VERSION "HNNBNNNYNNNNNNNNNNNNNNNNNNNNNNNNNNNNNNNNNN/4/%%%/4/'%**4NNN///"

NS_ :

BS_:

BU_: BAP_Tester BedienDisp_vo BedienSG_hi CGS DDA Gateway Gateway_PAG GurtMikrofon OTA_FC ZR_High ZR_LIMU ZR_MIB_TOP_ab_Gen3 ZR_Standard

BO_ 2527679896 Fahrwerk_12: 8 Gateway_PAG
 SG_ Fahrwerk_12_CRC : 0|8@1+ (1,0) [0|255] ""  Vector__XXX
 SG_ Fahrwerk_12_BZ : 8|4@1+ (1,0) [0|15] ""  Vector__XXX
 SG_ EFP_ReifenTempOf_VL : 12|6@1+ (2,-25) [-25|99] "Unit_DegreCelsi"  Vector__XXX
 SG_ EFP_ReifenTempOf_VR : 18|6@1+ (2,-25) [-25|99] "Unit_DegreCelsi"  Vector__XXX
 SG_ EFP_ReifenTempOf_HL : 24|6@1+ (2,-25) [-25|99] "Unit_DegreCelsi"  Vector__XXX
 SG_ EFP_ReifenTempOf_HR : 30|6@1+ (2,-25) [-25|99] "Unit_DegreCelsi"  Vector__XXX
 SG_ FA_FahrerAnf_Lift_Abwurf : 39|1@1+ (1.0,0.0) [0.0|1] ""  ZR_MIB_TOP_ab_Gen3
 SG_ FA_Niveau_AOCCT_timer2_verbaut : 40|1@1+ (1.0,0.0) [0.0|1] ""  Vector__XXX
 SG_ FA_Niveau_AOCCT_timer2_count : 41|1@1+ (1.0,0.0) [0.0|1] ""  Vector__XXX
 SG_ FA_Niveau_AOCCT_timer1_verbaut : 42|1@1+ (1.0,0.0) [0.0|1] ""  Vector__XXX
 SG_ FA_Niveau_AOCCT_timer1_count : 43|1@1+ (1.0,0.0) [0.0|1] ""  Vector__XXX
 SG_ FA_Niveau_AOCCT_teststatus : 44|1@1+ (1.0,0.0) [0.0|1] ""  Vector__XXX
 SG_ FA_Niveau_AOCCT_fehlerstatus : 45|1@1+ (1.0,0.0) [0.0|1] ""  Vector__XXX
 SG_ FA_Zuladung_VA : 46|6@1+ (20,0) [0|1200] "Unit_KiloGram"  Vector__XXX
 SG_ FA_Zuladung_HA : 52|6@1+ (20,0) [0|1200] "Unit_KiloGram"  Vector__XXX
 SG_ FA_Zuladung_Status_VA : 58|3@1+ (1.0,0.0) [0.0|7] ""  Vector__XXX
 SG_ FA_Zuladung_Status_HA : 61|3@1+ (1.0,0.0) [0.0|7] ""  Vector__XXX

BO_ 705 Fahrwerk_Anzeige_01: 8 Gateway
 SG_ Fahrwerk_Anzeige_01_CRC : 0|8@1+ (1,0) [0|255] ""  Vector__XXX
 SG_ Fahrwerk_Anzeige_01_BZ : 8|4@1+ (1,0) [0|15] ""  Vector__XXX
 SG_ EFP_Verbau_DR : 12|1@1+ (1.0,0.0) [0.0|1] ""  Vector__XXX
 SG_ EFP_Verbau_eAllrad : 13|1@1+ (1.0,0.0) [0.0|1] ""  Vector__XXX
 SG_ EFP_Verbau_LF : 14|1@1+ (1.0,0.0) [0.0|1] ""  Vector__XXX
 SG_ LF_Texte : 15|2@1+ (1.0,0.0) [0.0|3] ""  Vector__XXX
 SG_ EFP_Verbau_eAWS : 17|1@1+ (1.0,0.0) [0.0|1] ""  Vector__XXX
 SG_ eAWS_Warnmeldung_Prio1 : 18|1@1+ (1.0,0.0) [0.0|1] ""  Vector__XXX
 SG_ eAWS_Warnmeldung_Prio2 : 19|1@1+ (1.0,0.0) [0.0|1] ""  Vector__XXX
 SG_ LF_Texte_2 : 20|4@1+ (1.0,0.0) [0.0|15] ""  Vector__XXX
 SG_ EFP_Status_Taster_Lift : 24|2@1+ (1.0,0.0) [0.0|3] ""  OTA_FC
 SG_ EFP_Status_Taster_Fahrwerk : 26|2@1+ (1.0,0.0) [0.0|3] ""  BedienDisp_vo,OTA_FC
 SG_ FDR_Warnung_ALR : 28|2@1+ (1.0,0.0) [0.0|3] ""  Vector__XXX
 SG_ FDR_Warnung_TV : 30|2@1+ (1.0,0.0) [0.0|3] ""  Vector__XXX
 SG_ EFP_Verbau_eABC : 32|1@1+ (1.0,0.0) [0.0|1] ""  Vector__XXX
 SG_ LF_Warnung_Prio1_02 : 33|3@1+ (1.0,0.0) [0.0|7] ""  Vector__XXX
 SG_ LF_Warnung_Prio1 : 36|2@1+ (1.0,0.0) [0.0|3] ""  Vector__XXX
 SG_ LF_Warnung_Prio2 : 38|2@1+ (1.0,0.0) [0.0|3] ""  Vector__XXX
 SG_ eABC_Warnung_Prio2 : 40|2@1+ (1.0,0.0) [0.0|3] ""  Vector__XXX
 SG_ eABC_Warnung_Prio1 : 42|3@1+ (1.0,0.0) [0.0|7] ""  Vector__XXX
 SG_ eABC_Texte : 45|3@1+ (1.0,0.0) [0.0|7] ""  Vector__XXX
 SG_ DR_Warnung : 48|2@1+ (1.0,0.0) [0.0|3] ""  Vector__XXX
 SG_ NR_LED_Offroadlevel : 50|2@1+ (1.0,0.0) [0.0|3] ""  Vector__XXX
 SG_ NR_LED_Ladelevel : 52|2@1+ (1.0,0.0) [0.0|3] ""  Vector__XXX
 SG_ NR_LED_Sync : 54|2@1+ (1.0,0.0) [0.0|3] ""  Vector__XXX
 SG_ NR_LED_XtraLevel : 56|2@1+ (1.0,0.0) [0.0|3] ""  Vector__XXX
 SG_ NR_LED_Strassenlevel : 58|2@1+ (1.0,0.0) [0.0|3] ""  Vector__XXX
 SG_ EFP_Warnung_Naesse : 60|3@1+ (1.0,0.0) [0.0|7] ""  Vector__XXX
 SG_ EFP_Warnung_Naesse_verf : 63|1@1+ (1.0,0.0) [0.0|1] ""  Vector__XXX

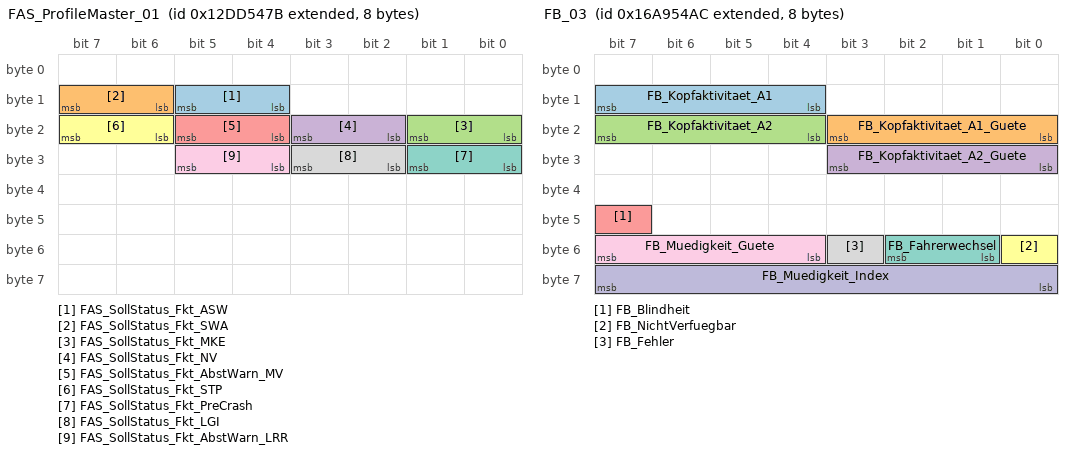
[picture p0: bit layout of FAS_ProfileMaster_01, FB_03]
BO_ 2463978619 FAS_ProfileMaster_01: 8 Gateway
 SG_ FAS_SollStatus_Fkt_ASW : 12|2@1+ (1.0,0.0) [0.0|3] ""  ZR_High
 SG_ FAS_SollStatus_Fkt_SWA : 14|2@1+ (1.0,0.0) [0.0|3] ""  ZR_High
 SG_ FAS_SollStatus_Fkt_MKE : 16|2@1+ (1.0,0.0) [0.0|3] ""  ZR_High
 SG_ FAS_SollStatus_Fkt_NV : 18|2@1+ (1.0,0.0) [0.0|3] ""  ZR_High
 SG_ FAS_SollStatus_Fkt_AbstWarn_MV : 20|2@1+ (1.0,0.0) [0.0|3] ""  ZR_High
 SG_ FAS_SollStatus_Fkt_STP : 22|2@1+ (1.0,0.0) [0.0|3] ""  ZR_High
 SG_ FAS_SollStatus_Fkt_PreCrash : 24|2@1+ (1.0,0.0) [0.0|3] ""  ZR_High
 SG_ FAS_SollStatus_Fkt_LGI : 26|2@1+ (1.0,0.0) [0.0|3] ""  ZR_High
 SG_ FAS_SollStatus_Fkt_AbstWarn_LRR : 28|2@1+ (1.0,0.0) [0.0|3] ""  Vector__XXX

BO_ 2527679660 FB_03: 8 Gateway
 SG_ FB_Kopfaktivitaet_A1 : 12|4@1+ (7.143,0) [0.000|100.002] "Unit_None"  Vector__XXX
 SG_ FB_Kopfaktivitaet_A1_Guete : 16|4@1+ (6.667,0) [0.000|100.005] "Unit_PerCent"  Vector__XXX
 SG_ FB_Kopfaktivitaet_A2 : 20|4@1+ (7.143,0) [0.000|100.002] "Unit_None"  Vector__XXX
 SG_ FB_Kopfaktivitaet_A2_Guete : 24|4@1+ (6.667,0) [0.000|100.005] "Unit_PerCent"  Vector__XXX
 SG_ FB_Blindheit : 47|1@1+ (1.0,0.0) [0.0|1] ""  Vector__XXX
 SG_ FB_NichtVerfuegbar : 48|1@1+ (1.0,0.0) [0.0|1] ""  Vector__XXX
 SG_ FB_Fahrerwechsel : 49|2@1+ (1.0,0.0) [0.0|3] ""  ZR_High
 SG_ FB_Fehler : 51|1@1+ (1.0,0.0) [0.0|1] ""  ZR_High
 SG_ FB_Muedigkeit_Guete : 52|4@1+ (6.667,0) [0.000|100.005] "Unit_PerCent"  ZR_High
 SG_ FB_Muedigkeit_Index : 56|8@1+ (0.05,0) [0.00|9.00] "Unit_None"  ZR_High

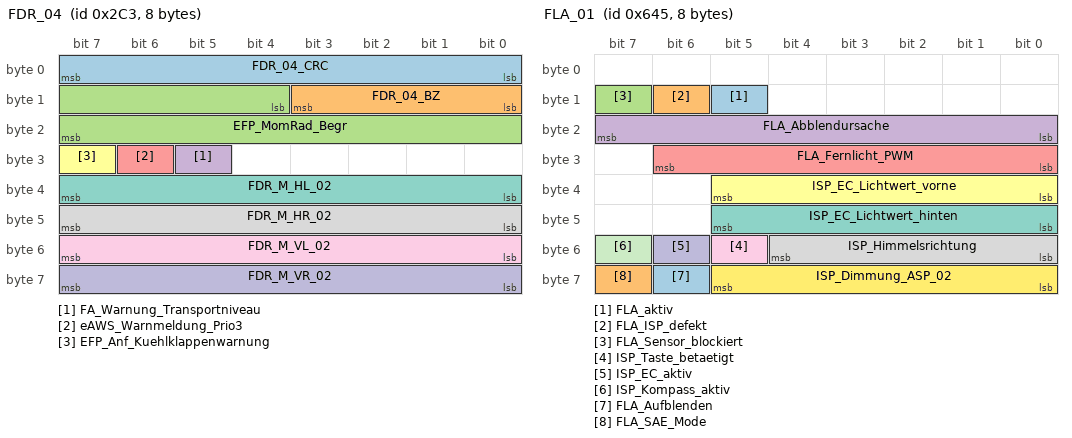
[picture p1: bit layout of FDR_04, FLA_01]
BO_ 707 FDR_04: 8 Gateway
 SG_ FDR_04_CRC : 0|8@1+ (1,0) [0|255] ""  Vector__XXX
 SG_ FDR_04_BZ : 8|4@1+ (1,0) [0|15] ""  Vector__XXX
 SG_ EFP_MomRad_Begr : 12|12@1+ (3,0) [0|12279] "Unit_NewtoMeter"  Vector__XXX
 SG_ FA_Warnung_Transportniveau : 29|1@1+ (1.0,0.0) [0.0|1] ""  Vector__XXX
 SG_ eAWS_Warnmeldung_Prio3 : 30|1@1+ (1.0,0.0) [0.0|1] ""  Vector__XXX
 SG_ EFP_Anf_Kuehlklappenwarnung : 31|1@1+ (1.0,0.0) [0.0|1] ""  Vector__XXX
 SG_ FDR_M_HL_02 : 32|8@1+ (1,-100) [-100|100] "Unit_PerCent"  ZR_High,ZR_LIMU,ZR_MIB_TOP_ab_Gen3,ZR_Standard
 SG_ FDR_M_HR_02 : 40|8@1+ (1,-100) [-100|100] "Unit_PerCent"  ZR_High,ZR_LIMU,ZR_MIB_TOP_ab_Gen3,ZR_Standard
 SG_ FDR_M_VL_02 : 48|8@1+ (1,-100) [-100|100] "Unit_PerCent"  ZR_High,ZR_LIMU,ZR_MIB_TOP_ab_Gen3,ZR_Standard
 SG_ FDR_M_VR_02 : 56|8@1+ (1,-100) [-100|100] "Unit_PerCent"  ZR_High,ZR_LIMU,ZR_MIB_TOP_ab_Gen3,ZR_Standard

BO_ 1605 FLA_01: 8 Gateway
 SG_ FLA_aktiv : 13|1@1+ (1.0,0.0) [0.0|1] ""  Vector__XXX
 SG_ FLA_ISP_defekt : 14|1@1+ (1.0,0.0) [0.0|1] ""  ZR_High
 SG_ FLA_Sensor_blockiert : 15|1@1+ (1.0,0.0) [0.0|1] ""  ZR_High
 SG_ FLA_Abblendursache : 16|8@1+ (1.0,0.0) [0.0|255] ""  ZR_High
 SG_ FLA_Fernlicht_PWM : 24|7@1+ (1,0) [0|100] "Unit_PerCent"  Vector__XXX
 SG_ ISP_EC_Lichtwert_vorne : 32|6@1+ (1,0) [0|61] "Unit_None"  Vector__XXX
 SG_ ISP_EC_Lichtwert_hinten : 40|6@1+ (1,0) [0|61] "Unit_None"  Vector__XXX
 SG_ ISP_Himmelsrichtung : 48|5@1+ (12,0) [0|348] "Unit_DegreOfArc"  Vector__XXX
 SG_ ISP_Taste_betaetigt : 53|1@1+ (1.0,0.0) [0.0|1] ""  Vector__XXX
 SG_ ISP_EC_aktiv : 54|1@1+ (1.0,0.0) [0.0|1] ""  Vector__XXX
 SG_ ISP_Kompass_aktiv : 55|1@1+ (1.0,0.0) [0.0|1] ""  Vector__XXX
 SG_ ISP_Dimmung_ASP_02 : 56|6@1+ (0.0226,0) [0.0000|1.4012] "Unit_Volt"  OTA_FC
 SG_ FLA_Aufblenden : 62|1@1+ (1.0,0.0) [0.0|1] ""  Vector__XXX
 SG_ FLA_SAE_Mode : 63|1@1+ (1.0,0.0) [0.0|1] ""  Vector__XXX

BO_ 2589283684 FoD_01: 8 Gateway
 SG_ FoD_Transmission_Info : 60|2@1+ (1.0,0.0) [0.0|3] ""  ZR_High,ZR_LIMU,ZR_MIB_TOP_ab_Gen3
 SG_ FoD_Anz_Funktionsabschaltung : 62|2@1+ (1.0,0.0) [0.0|3] ""  Vector__XXX

BO_ 2549875571 FoD_ZR_Req: 8 Gateway
 SG_ FoD_ZR_Req_Data : 0|64@1+ (1.0,0.0) [0.0|18446744073709551615] ""  ZR_High,ZR_LIMU,ZR_MIB_TOP_ab_Gen3

BO_ 2550006643 FoD_ZR_Resp: 8 ZR_High
 SG_ FoD_ZR_Resp_Data : 0|64@1+ (1.0,0.0) [0.0|18446744073709551615] ""  Gateway,Gateway_PAG

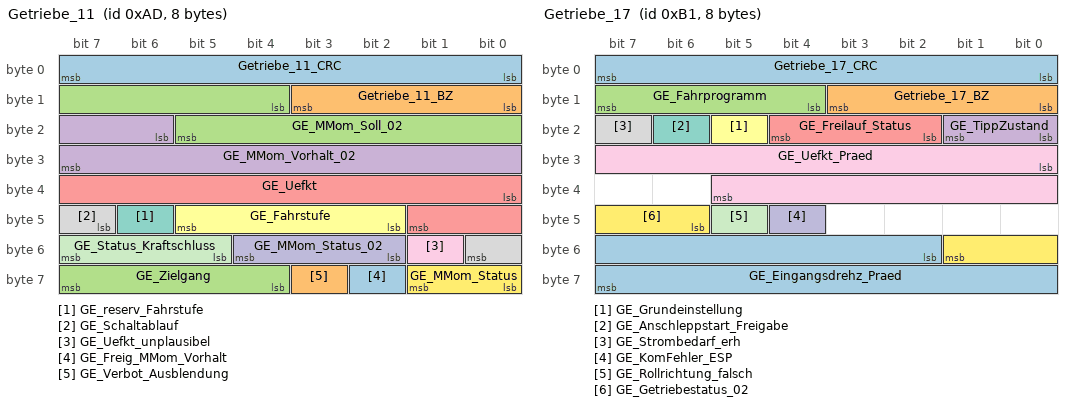
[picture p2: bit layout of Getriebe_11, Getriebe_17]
BO_ 173 Getriebe_11: 8 Gateway
 SG_ Getriebe_11_CRC : 0|8@1+ (1,0) [0|255] ""  Vector__XXX
 SG_ Getriebe_11_BZ : 8|4@1+ (1,0) [0|15] ""  Vector__XXX
 SG_ GE_MMom_Soll_02 : 12|10@1+ (1,-509) [-509|509] ""  Vector__XXX
 SG_ GE_MMom_Vorhalt_02 : 22|10@1+ (1,-509) [-509|509] ""  Vector__XXX
 SG_ GE_Uefkt : 32|10@1+ (0.1,0) [0.0|102.2] ""  Vector__XXX
 SG_ GE_Fahrstufe : 42|4@1+ (1.0,0.0) [0.0|15] ""  DDA,OTA_FC,ZR_High,ZR_LIMU,ZR_MIB_TOP_ab_Gen3
 SG_ GE_reserv_Fahrstufe : 46|1@1+ (1,0) [0|1] ""  Vector__XXX
 SG_ GE_Schaltablauf : 47|2@1+ (1.0,0.0) [0.0|3] ""  Vector__XXX
 SG_ GE_Uefkt_unplausibel : 49|1@1+ (1.0,0.0) [0.0|1] ""  Vector__XXX
 SG_ GE_MMom_Status_02 : 50|3@1+ (1.0,0.0) [0.0|7] ""  Vector__XXX
 SG_ GE_Status_Kraftschluss : 53|3@1+ (1.0,0.0) [0.0|7] ""  Vector__XXX
 SG_ GE_MMom_Status : 56|2@1+ (1.0,0.0) [0.0|3] ""  Vector__XXX
 SG_ GE_Freig_MMom_Vorhalt : 58|1@1+ (1.0,0.0) [0.0|1] ""  Vector__XXX
 SG_ GE_Verbot_Ausblendung : 59|1@1+ (1.0,0.0) [0.0|1] ""  Vector__XXX
 SG_ GE_Zielgang : 60|4@1+ (1.0,0.0) [0.0|15] ""  OTA_FC,ZR_High

BO_ 968 Getriebe_14: 8 Gateway
 SG_ GE_OBD_AbsperrVent : 12|4@1+ (1.0,0.0) [0.0|15] ""  Vector__XXX
 SG_ GE_amax_moeglich : 16|9@1+ (0.024,-2.016) [-2.016|10.224] "Unit_MeterPerSeconSquar"  Vector__XXX
 SG_ GE_Charisma_FahrPr : 25|4@1+ (1.0,0.0) [0.0|15] ""  Vector__XXX
 SG_ GE_Charisma_Status : 29|2@1+ (1.0,0.0) [0.0|3] ""  Vector__XXX
 SG_ GE_Freigabe_Verfallsinfo_WFS : 31|1@1+ (1.0,0.0) [0.0|1] ""  Vector__XXX
 SG_ GE_LaunchControl_LB : 32|4@1+ (1.0,0.0) [0.0|15] ""  Vector__XXX
 SG_ GE_Status_PaddleNeutral : 37|2@1+ (1.0,0.0) [0.0|3] ""  Vector__XXX
 SG_ GE_Remotestart_Betrieb : 39|1@1+ (1.0,0.0) [0.0|1] ""  Vector__XXX
 SG_ Freilauf_Charisma_FahrPr : 40|4@1+ (1.0,0.0) [0.0|15] ""  Vector__XXX
 SG_ Freilauf_Charisma_Status : 44|2@1+ (1.0,0.0) [0.0|3] ""  Vector__XXX
 SG_ GE_Freigabe_Info_WFS : 46|1@1+ (1.0,0.0) [0.0|1] ""  Vector__XXX
 SG_ GE_Sperr_Info_WFS : 47|1@1+ (1.0,0.0) [0.0|1] ""  Vector__XXX
 SG_ GE_Zustand_Kuppltemp : 48|2@1+ (1.0,0.0) [0.0|3] ""  Vector__XXX
 SG_ GE_Codierung_MSG : 50|1@1+ (1.0,0.0) [0.0|1] ""  Vector__XXX
 SG_ GE_LaunchControl : 51|1@1+ (1.0,0.0) [0.0|1] ""  OTA_FC
 SG_ GE_Heizwunsch : 52|2@1+ (1.0,0.0) [0.0|3] ""  Vector__XXX
 SG_ GE_OBD_Status : 54|1@1+ (1.0,0.0) [0.0|1] ""  Vector__XXX
 SG_ GE_LFR_Adaption : 55|1@1+ (1.0,0.0) [0.0|1] ""  Vector__XXX
 SG_ GE_Sumpftemperatur : 56|8@1+ (1,-58) [-58|196] "Unit_DegreCelsi"  OTA_FC,ZR_High,ZR_MIB_TOP_ab_Gen3,ZR_Standard

BO_ 177 Getriebe_17: 8 Gateway
 SG_ Getriebe_17_CRC : 0|8@1+ (1,0) [0|255] ""  Vector__XXX
 SG_ Getriebe_17_BZ : 8|4@1+ (1,0) [0|15] ""  Vector__XXX
 SG_ GE_Fahrprogramm : 12|4@1+ (1.0,0.0) [0.0|15] ""  OTA_FC,ZR_High
 SG_ GE_TippZustand : 16|2@1+ (1.0,0.0) [0.0|3] ""  ZR_High
 SG_ GE_Freilauf_Status : 18|3@1+ (1.0,0.0) [0.0|7] ""  Vector__XXX
 SG_ GE_Grundeinstellung : 21|1@1+ (1.0,0.0) [0.0|1] ""  Vector__XXX
 SG_ GE_Anschleppstart_Freigabe : 22|1@1+ (1.0,0.0) [0.0|1] ""  Vector__XXX
 SG_ GE_Strombedarf_erh : 23|1@1+ (1.0,0.0) [0.0|1] ""  Vector__XXX
 SG_ GE_Uefkt_Praed : 24|14@1+ (0.008,0) [0.000|131.056] ""  Vector__XXX
 SG_ GE_KomFehler_ESP : 44|1@1+ (1.0,0.0) [0.0|1] ""  Vector__XXX
 SG_ GE_Rollrichtung_falsch : 45|1@1+ (1.0,0.0) [0.0|1] ""  Vector__XXX
 SG_ GE_Getriebestatus_02 : 46|4@1+ (1.0,0.0) [0.0|15] ""  OTA_FC
 SG_ GE_Eingangsdrehz_Praed : 50|14@1+ (1,0) [0|16381] "Unit_MinutInver"  Vector__XXX

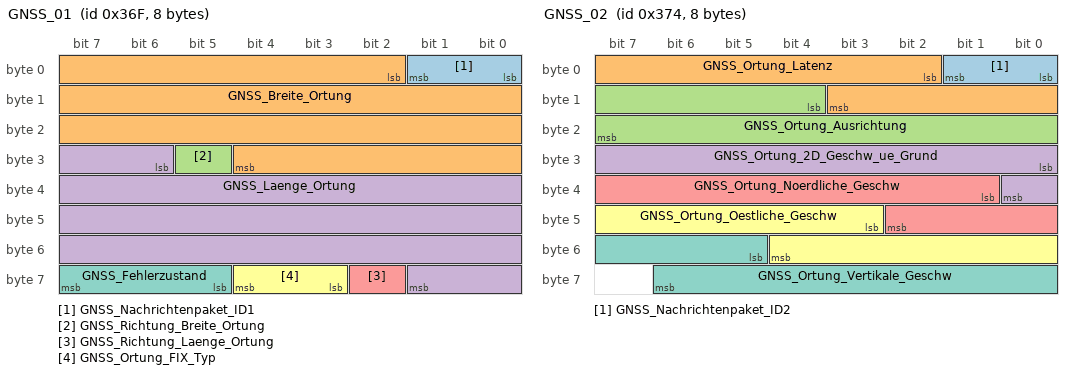
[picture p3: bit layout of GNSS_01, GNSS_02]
BO_ 879 GNSS_01: 8 Gateway
 SG_ GNSS_Nachrichtenpaket_ID1 : 0|2@1+ (1,0) [0|3] "Unit_Bit"  ZR_High,ZR_LIMU,ZR_MIB_TOP_ab_Gen3,ZR_Standard
 SG_ GNSS_Breite_Ortung : 2|27@1+ (0.000001,0) [0.000000|90.000000] "Unit_DegreOfArc"  ZR_High,ZR_LIMU,ZR_MIB_TOP_ab_Gen3,ZR_Standard
 SG_ GNSS_Richtung_Breite_Ortung : 29|1@1+ (1.0,0.0) [0.0|1] ""  ZR_High,ZR_LIMU,ZR_MIB_TOP_ab_Gen3,ZR_Standard
 SG_ GNSS_Laenge_Ortung : 30|28@1+ (0.000001,0) [0.000000|180.000000] "Unit_DegreOfArc"  ZR_High,ZR_LIMU,ZR_MIB_TOP_ab_Gen3,ZR_Standard
 SG_ GNSS_Richtung_Laenge_Ortung : 58|1@1+ (1.0,0.0) [0.0|1] ""  ZR_High,ZR_LIMU,ZR_MIB_TOP_ab_Gen3,ZR_Standard
 SG_ GNSS_Ortung_FIX_Typ : 59|2@1+ (1.0,0.0) [0.0|3] ""  ZR_High,ZR_LIMU,ZR_MIB_TOP_ab_Gen3,ZR_Standard
 SG_ GNSS_Fehlerzustand : 61|3@1+ (1.0,0.0) [0.0|7] ""  ZR_High,ZR_LIMU,ZR_MIB_TOP_ab_Gen3,ZR_Standard

BO_ 884 GNSS_02: 8 Gateway
 SG_ GNSS_Nachrichtenpaket_ID2 : 0|2@1+ (1,0) [0|3] "Unit_Bit"  ZR_High,ZR_LIMU,ZR_MIB_TOP_ab_Gen3,ZR_Standard
 SG_ GNSS_Ortung_Latenz : 2|10@1+ (1,0) [0|1021] "Unit_MilliSecon"  ZR_High,ZR_LIMU,ZR_MIB_TOP_ab_Gen3,ZR_Standard
 SG_ GNSS_Ortung_Ausrichtung : 12|12@1+ (0.1,0) [0.0|359.9] "Unit_DegreOfArc"  ZR_High,ZR_LIMU,ZR_MIB_TOP_ab_Gen3,ZR_Standard
 SG_ GNSS_Ortung_2D_Geschw_ue_Grund : 24|9@1+ (0.25,0) [0.00|125.00] "Unit_MeterPerSecon"  ZR_High,ZR_LIMU,ZR_MIB_TOP_ab_Gen3,ZR_Standard
 SG_ GNSS_Ortung_Noerdliche_Geschw : 33|10@1+ (0.25,-125) [-125.00|125.00] "Unit_MeterPerSecon"  ZR_High,ZR_LIMU,ZR_MIB_TOP_ab_Gen3,ZR_Standard
 SG_ GNSS_Ortung_Oestliche_Geschw : 43|10@1+ (0.25,-125) [-125.00|125.00] "Unit_MeterPerSecon"  ZR_High,ZR_LIMU,ZR_MIB_TOP_ab_Gen3,ZR_Standard
 SG_ GNSS_Ortung_Vertikale_Geschw : 53|10@1+ (0.25,-125) [-125.00|125.00] "Unit_MeterPerSecon"  ZR_High,ZR_LIMU,ZR_MIB_TOP_ab_Gen3,ZR_Standard

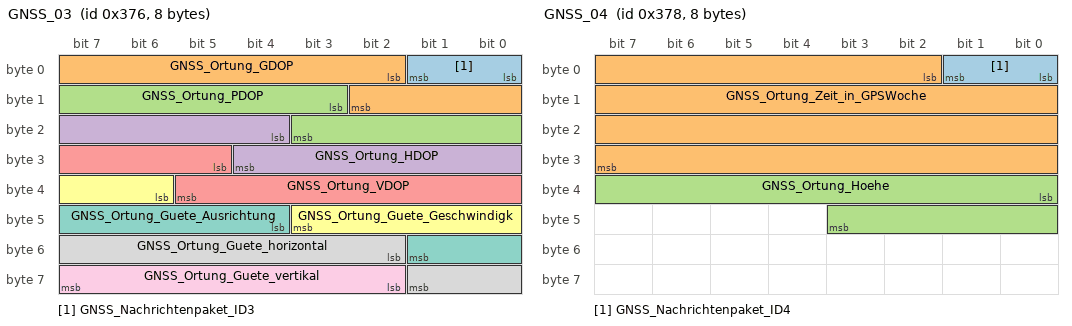
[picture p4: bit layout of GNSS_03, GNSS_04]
BO_ 886 GNSS_03: 8 Gateway
 SG_ GNSS_Nachrichtenpaket_ID3 : 0|2@1+ (1,0) [0|3] "Unit_Bit"  ZR_High,ZR_LIMU,ZR_MIB_TOP_ab_Gen3,ZR_Standard
 SG_ GNSS_Ortung_GDOP : 2|9@1+ (0.1,0) [0.0|50.0] "Unit_None"  ZR_High,ZR_LIMU,ZR_MIB_TOP_ab_Gen3,ZR_Standard
 SG_ GNSS_Ortung_PDOP : 11|9@1+ (0.1,0) [0.0|50.0] "Unit_None"  ZR_High,ZR_LIMU,ZR_MIB_TOP_ab_Gen3,ZR_Standard
 SG_ GNSS_Ortung_HDOP : 20|9@1+ (0.1,0) [0.0|50.0] "Unit_None"  ZR_High,ZR_LIMU,ZR_MIB_TOP_ab_Gen3,ZR_Standard
 SG_ GNSS_Ortung_VDOP : 29|9@1+ (0.1,0) [0.0|50.0] "Unit_None"  ZR_High,ZR_LIMU,ZR_MIB_TOP_ab_Gen3,ZR_Standard
 SG_ GNSS_Ortung_Guete_Geschwindigk : 38|6@1+ (0.05,0) [0.00|3.05] "Unit_MeterPerSecon"  ZR_High,ZR_LIMU,ZR_MIB_TOP_ab_Gen3,ZR_Standard
 SG_ GNSS_Ortung_Guete_Ausrichtung : 44|6@1+ (0.15,0) [0.00|9.15] "Unit_DegreOfArc"  ZR_High,ZR_LIMU,ZR_MIB_TOP_ab_Gen3,ZR_Standard
 SG_ GNSS_Ortung_Guete_horizontal : 50|8@1+ (1,0) [0|250] "Unit_Meter"  ZR_High,ZR_LIMU,ZR_MIB_TOP_ab_Gen3,ZR_Standard
 SG_ GNSS_Ortung_Guete_vertikal : 58|6@1+ (2,0) [0|122] "Unit_Meter"  ZR_High,ZR_LIMU,ZR_MIB_TOP_ab_Gen3,ZR_Standard

BO_ 888 GNSS_04: 8 Gateway
 SG_ GNSS_Nachrichtenpaket_ID4 : 0|2@1+ (1,0) [0|3] "Unit_Bit"  ZR_High,ZR_LIMU,ZR_MIB_TOP_ab_Gen3,ZR_Standard
 SG_ GNSS_Ortung_Zeit_in_GPSWoche : 2|30@1+ (1,0) [0|604800001] "Unit_MilliSecon"  ZR_High,ZR_LIMU,ZR_MIB_TOP_ab_Gen3,ZR_Standard
 SG_ GNSS_Ortung_Hoehe : 32|12@1+ (2,-500) [-500|7686] "Unit_Meter"  ZR_High,ZR_LIMU,ZR_MIB_TOP_ab_Gen3,ZR_Standard

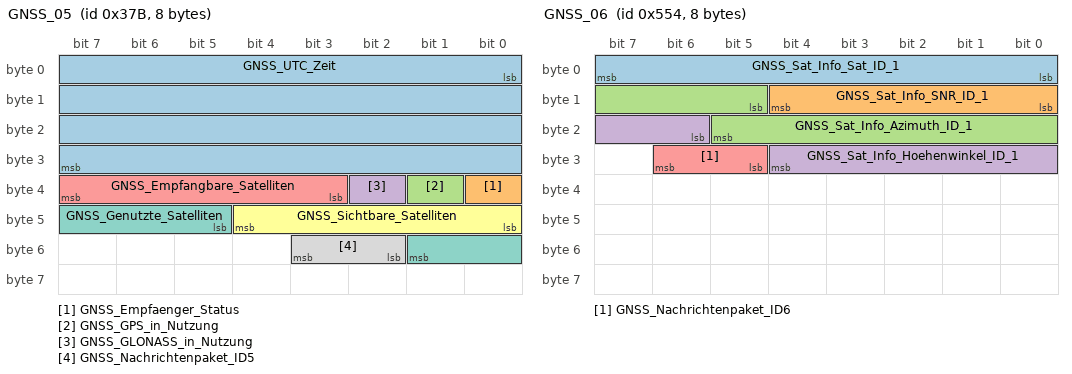
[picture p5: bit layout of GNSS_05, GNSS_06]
BO_ 891 GNSS_05: 8 Gateway
 SG_ GNSS_UTC_Zeit : 0|32@1+ (1,0) [1|4294967295] "Unit_Secon"  OTA_FC,ZR_High,ZR_LIMU,ZR_MIB_TOP_ab_Gen3,ZR_Standard
 SG_ GNSS_Empfaenger_Status : 32|1@1+ (1.0,0.0) [0.0|1] ""  OTA_FC,ZR_High,ZR_LIMU,ZR_MIB_TOP_ab_Gen3,ZR_Standard
 SG_ GNSS_GPS_in_Nutzung : 33|1@1+ (1.0,0.0) [0.0|1] ""  ZR_High,ZR_LIMU,ZR_MIB_TOP_ab_Gen3,ZR_Standard
 SG_ GNSS_GLONASS_in_Nutzung : 34|1@1+ (1.0,0.0) [0.0|1] ""  ZR_High,ZR_LIMU,ZR_MIB_TOP_ab_Gen3,ZR_Standard
 SG_ GNSS_Empfangbare_Satelliten : 35|5@1+ (1,0) [1|30] "Unit_None"  ZR_High,ZR_LIMU,ZR_MIB_TOP_ab_Gen3,ZR_Standard
 SG_ GNSS_Sichtbare_Satelliten : 40|5@1+ (1,0) [1|30] "Unit_None"  ZR_High,ZR_LIMU,ZR_MIB_TOP_ab_Gen3,ZR_Standard
 SG_ GNSS_Genutzte_Satelliten : 45|5@1+ (1,0) [1|30] "Unit_None"  ZR_High,ZR_LIMU,ZR_MIB_TOP_ab_Gen3,ZR_Standard
 SG_ GNSS_Nachrichtenpaket_ID5 : 50|2@1+ (1,0) [0|3] "Unit_Bit"  ZR_High,ZR_LIMU,ZR_MIB_TOP_ab_Gen3,ZR_Standard

BO_ 1364 GNSS_06: 8 Gateway
 SG_ GNSS_Sat_Info_Sat_ID_1 : 0|8@1+ (1,0) [0|255] ""  ZR_High,ZR_LIMU,ZR_MIB_TOP_ab_Gen3,ZR_Standard
 SG_ GNSS_Sat_Info_SNR_ID_1 : 8|5@1+ (2,0) [0|60] "Unit_DeziBel"  ZR_High,ZR_LIMU,ZR_MIB_TOP_ab_Gen3,ZR_Standard
 SG_ GNSS_Sat_Info_Azimuth_ID_1 : 13|9@1+ (1,0) [0|359] "Unit_DegreOfArc"  ZR_High,ZR_LIMU,ZR_MIB_TOP_ab_Gen3,ZR_Standard
 SG_ GNSS_Sat_Info_Hoehenwinkel_ID_1 : 22|7@1+ (1,0) [0|90] "Unit_DegreOfArc"  ZR_High,ZR_LIMU,ZR_MIB_TOP_ab_Gen3,ZR_Standard
 SG_ GNSS_Nachrichtenpaket_ID6 : 29|2@1+ (1,0) [0|3] "Unit_Bit"  ZR_High,ZR_LIMU,ZR_MIB_TOP_ab_Gen3,ZR_Standard

BO_ 299 GRA_ACC_01: 8 Gateway
 SG_ GRA_ACC_01_CRC : 0|8@1+ (1,0) [0|255] ""  Vector__XXX
 SG_ GRA_ACC_01_BZ : 8|4@1+ (1,0) [0|15] ""  Vector__XXX
 SG_ GRA_Hauptschalter : 12|1@1+ (1.0,0.0) [0.0|1] ""  ZR_High
 SG_ GRA_Abbrechen : 13|1@1+ (1.0,0.0) [0.0|1] ""  ZR_High
 SG_ GRA_Typ_Hauptschalter : 14|1@1+ (1.0,0.0) [0.0|1] ""  ZR_High
 SG_ GRA_Limiter : 15|1@1+ (1.0,0.0) [0.0|1] ""  ZR_High
 SG_ GRA_Tip_Setzen : 16|1@1+ (1.0,0.0) [0.0|1] ""  ZR_High
 SG_ GRA_Tip_Hoch : 17|1@1+ (1.0,0.0) [0.0|1] ""  ZR_High
 SG_ GRA_Tip_Runter : 18|1@1+ (1.0,0.0) [0.0|1] ""  ZR_High
 SG_ GRA_Tip_Wiederaufnahme : 19|1@1+ (1.0,0.0) [0.0|1] ""  ZR_High
 SG_ GRA_Verstellung_Zeitluecke : 20|2@1+ (1.0,0.0) [0.0|3] ""  ZR_High
 SG_ GRA_Codierung : 22|2@1+ (1.0,0.0) [0.0|3] ""  ZR_High
 SG_ GRA_Fehler : 24|1@1+ (1.0,0.0) [0.0|1] ""  ZR_High
 SG_ GRA_LIM_Taste_verfuegbar : 25|1@1+ (1.0,0.0) [0.0|1] ""  ZR_High
 SG_ GRA_Tip_Stufe_2 : 26|1@1+ (1.0,0.0) [0.0|1] ""  ZR_High
 SG_ GRA_Typ_Bedienteil : 27|3@1+ (1.0,0.0) [0.0|7] ""  ZR_High
 SG_ GRA_TravelAssist : 30|1@1+ (1.0,0.0) [0.0|1] ""  Vector__XXX
 SG_ GRA_reserveByte4 : 31|1@1+ (1.0,0.0) [0.0|1] ""  Vector__XXX
 SG_ GRA_reserveByte5 : 32|8@1+ (1.0,0.0) [0.0|255] ""  Vector__XXX
 SG_ GRA_reserveByte6 : 40|8@1+ (1.0,0.0) [0.0|255] ""  Vector__XXX
 SG_ GRA_reserveByte7 : 48|8@1+ (1.0,0.0) [0.0|255] ""  Vector__XXX
 SG_ GRA_reserveByte8 : 56|8@1+ (1.0,0.0) [0.0|255] ""  Vector__XXX

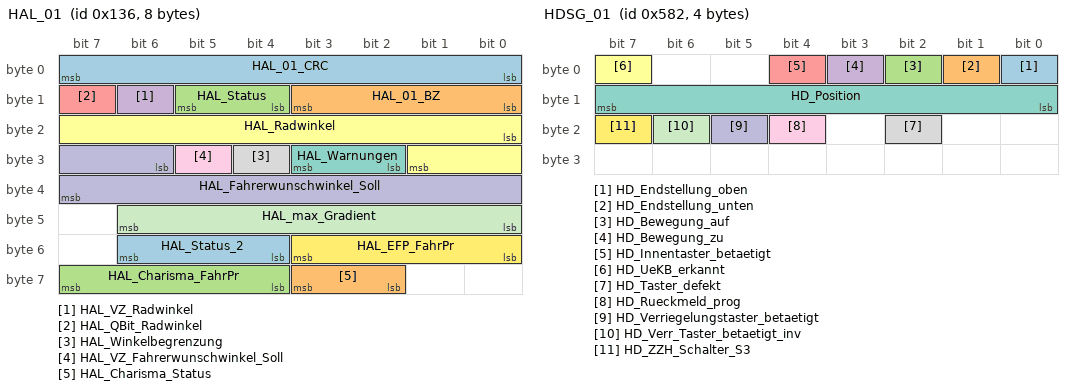
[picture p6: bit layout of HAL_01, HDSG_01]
BO_ 310 HAL_01: 8 Gateway
 SG_ HAL_01_CRC : 0|8@1+ (1,0) [0|255] ""  Vector__XXX
 SG_ HAL_01_BZ : 8|4@1+ (1,0) [0|15] ""  Vector__XXX
 SG_ HAL_Status : 12|2@1+ (1.0,0.0) [0.0|3] ""  Vector__XXX
 SG_ HAL_VZ_Radwinkel : 14|1@1+ (1.0,0.0) [0.0|1] ""  ZR_LIMU
 SG_ HAL_QBit_Radwinkel : 15|1@1+ (1.0,0.0) [0.0|1] ""  Vector__XXX
 SG_ HAL_Radwinkel : 16|10@1+ (0.01,0) [0.00|10.19] "Unit_DegreOfArc"  ZR_LIMU
 SG_ HAL_Warnungen : 26|2@1+ (1.0,0.0) [0.0|3] ""  Vector__XXX
 SG_ HAL_Winkelbegrenzung : 28|1@1+ (1.0,0.0) [0.0|1] ""  Vector__XXX
 SG_ HAL_VZ_Fahrerwunschwinkel_Soll : 29|1@1+ (1.0,0.0) [0.0|1] ""  Vector__XXX
 SG_ HAL_Fahrerwunschwinkel_Soll : 30|10@1+ (0.01,0) [0.00|10.21] "Unit_DegreOfArc"  Vector__XXX
 SG_ HAL_max_Gradient : 40|7@1+ (0.1,0) [0.0|12.5] "Unit_DegreOfArcPerSecon"  Vector__XXX
 SG_ HAL_EFP_FahrPr : 48|4@1+ (1.0,0.0) [0.0|15] ""  Vector__XXX
 SG_ HAL_Status_2 : 52|3@1+ (1.0,0.0) [0.0|7] ""  Vector__XXX
 SG_ HAL_Charisma_Status : 58|2@1+ (1.0,0.0) [0.0|3] ""  Vector__XXX
 SG_ HAL_Charisma_FahrPr : 60|4@1+ (1.0,0.0) [0.0|15] ""  Vector__XXX

BO_ 1410 HDSG_01: 4 Gateway
 SG_ HD_Endstellung_oben : 0|1@1+ (1.0,0.0) [0.0|1] ""  ZR_High
 SG_ HD_Endstellung_unten : 1|1@1+ (1.0,0.0) [0.0|1] ""  ZR_High
 SG_ HD_Bewegung_auf : 2|1@1+ (1.0,0.0) [0.0|1] ""  ZR_High
 SG_ HD_Bewegung_zu : 3|1@1+ (1.0,0.0) [0.0|1] ""  ZR_High
 SG_ HD_Innentaster_betaetigt : 4|1@1+ (1.0,0.0) [0.0|1] ""  ZR_High
 SG_ HD_UeKB_erkannt : 7|1@1+ (1.0,0.0) [0.0|1] ""  ZR_High
 SG_ HD_Position : 8|8@1+ (1,0) [0|100] "Unit_PerCent"  ZR_High
 SG_ HD_Taster_defekt : 18|1@1+ (1.0,0.0) [0.0|1] ""  ZR_High
 SG_ HD_Rueckmeld_prog : 20|1@1+ (1.0,0.0) [0.0|1] ""  Vector__XXX
 SG_ HD_Verriegelungstaster_betaetigt : 21|1@1+ (1.0,0.0) [0.0|1] ""  ZR_High
 SG_ HD_Verr_Taster_betaetigt_inv : 22|1@1+ (1.0,0.0) [0.0|1] ""  Vector__XXX
 SG_ HD_ZZH_Schalter_S3 : 23|1@1+ (1.0,0.0) [0.0|1] ""  Vector__XXX

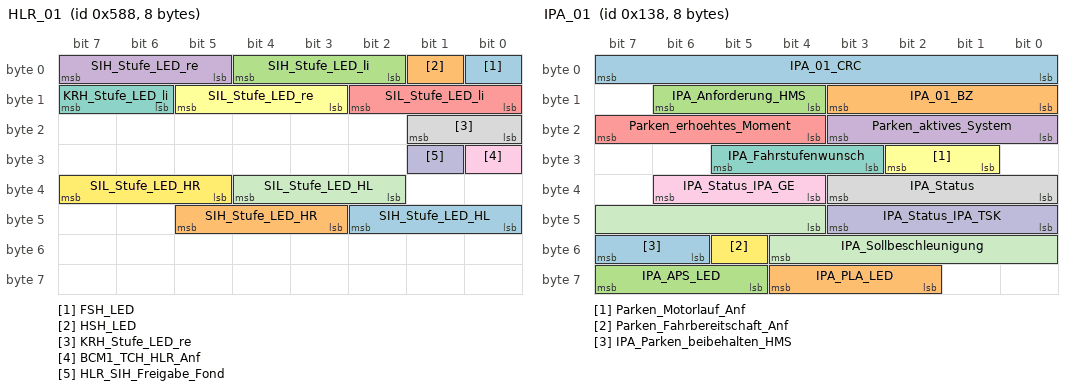
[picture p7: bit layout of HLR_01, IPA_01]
BO_ 1416 HLR_01: 8 Gateway
 SG_ FSH_LED : 0|1@1+ (1.0,0.0) [0.0|1] ""  ZR_High
 SG_ HSH_LED : 1|1@1+ (1.0,0.0) [0.0|1] ""  ZR_High
 SG_ SIH_Stufe_LED_li : 2|3@1+ (1.0,0.0) [0.0|7] ""  Vector__XXX
 SG_ SIH_Stufe_LED_re : 5|3@1+ (1.0,0.0) [0.0|7] ""  Vector__XXX
 SG_ SIL_Stufe_LED_li : 8|3@1+ (1.0,0.0) [0.0|7] ""  Vector__XXX
 SG_ SIL_Stufe_LED_re : 11|3@1+ (1.0,0.0) [0.0|7] ""  Vector__XXX
 SG_ KRH_Stufe_LED_li : 14|2@1+ (1.0,0.0) [0.0|3] ""  Vector__XXX
 SG_ KRH_Stufe_LED_re : 16|2@1+ (1.0,0.0) [0.0|3] ""  Vector__XXX
 SG_ BCM1_TCH_HLR_Anf : 24|1@1+ (1.0,0.0) [0.0|1] ""  Vector__XXX
 SG_ HLR_SIH_Freigabe_Fond : 25|1@1+ (1.0,0.0) [0.0|1] ""  ZR_High
 SG_ SIL_Stufe_LED_HL : 34|3@1+ (1.0,0.0) [0.0|7] ""  Vector__XXX
 SG_ SIL_Stufe_LED_HR : 37|3@1+ (1.0,0.0) [0.0|7] ""  Vector__XXX
 SG_ SIH_Stufe_LED_HL : 40|3@1+ (1.0,0.0) [0.0|7] ""  Vector__XXX
 SG_ SIH_Stufe_LED_HR : 43|3@1+ (1.0,0.0) [0.0|7] ""  Vector__XXX

BO_ 1016 HLR_02: 8 Gateway
 SG_ HLR_FlHz_Freigabe_Ruhesitz : 14|2@1+ (1.0,0.0) [0.0|3] ""  ZR_High
 SG_ HLR_FlHz_Freigabe_VR : 16|2@1+ (1.0,0.0) [0.0|3] ""  ZR_High
 SG_ HLR_FlHz_Freigabe_VL : 18|2@1+ (1.0,0.0) [0.0|3] ""  ZR_High
 SG_ HLR_FlHz_Freigabe_HR : 20|2@1+ (1.0,0.0) [0.0|3] ""  ZR_High
 SG_ HLR_FlHz_Freigabe_HL : 22|2@1+ (1.0,0.0) [0.0|3] ""  ZR_High
 SG_ HLR_TCH_Freigabe : 24|1@1+ (1.0,0.0) [0.0|1] ""  ZR_High
 SG_ HLR_SIH_Freigabe_Fond : 25|1@1+ (1.0,0.0) [0.0|1] ""  BedienSG_hi,ZR_High
 SG_ HLR_Sp_Heizung_Freigabe_BT : 26|1@1+ (1.0,0.0) [0.0|1] ""  ZR_High
 SG_ HLR_Sp_Heizung_Freigabe_FT : 27|1@1+ (1.0,0.0) [0.0|1] ""  ZR_High
 SG_ HLR_KRH_Freigabe_VL : 28|2@1+ (1.0,0.0) [0.0|3] ""  ZR_High
 SG_ HLR_KRH_Freigabe_VR : 30|2@1+ (1.0,0.0) [0.0|3] ""  ZR_High
 SG_ HLR_SIH_Freigabe_VL : 32|2@1+ (1.0,0.0) [0.0|3] ""  ZR_High
 SG_ HLR_SIH_Freigabe_VR : 34|2@1+ (1.0,0.0) [0.0|3] ""  ZR_High
 SG_ HLR_SIH_Freigabe_HL : 36|2@1+ (1.0,0.0) [0.0|3] ""  BedienSG_hi,ZR_High
 SG_ HLR_SIH_Freigabe_HR : 38|2@1+ (1.0,0.0) [0.0|3] ""  BedienSG_hi,ZR_High
 SG_ HLR_SIL_Freigabe_VL : 40|2@1+ (1.0,0.0) [0.0|3] ""  ZR_High
 SG_ HLR_SIL_Freigabe_VR : 42|2@1+ (1.0,0.0) [0.0|3] ""  ZR_High
 SG_ HLR_SIL_Freigabe_HL : 44|2@1+ (1.0,0.0) [0.0|3] ""  ZR_High
 SG_ HLR_SIL_Freigabe_HR : 46|2@1+ (1.0,0.0) [0.0|3] ""  ZR_High
 SG_ HLR_FSH_Freigabe : 48|6@1+ (20,0) [20|1240] "Unit_Watt"  ZR_High
 SG_ HLR_HSH_Freigabe : 54|1@1+ (1.0,0.0) [0.0|1] ""  ZR_High
 SG_ HLR_LRH_Freigabe : 55|1@1+ (1.0,0.0) [0.0|1] ""  ZR_High
 SG_ HLR_PTC_linear_Freigabe : 56|6@1+ (50,0) [0|3100] "Unit_Watt"  Vector__XXX
 SG_ HLR_PTC_Freigabe : 62|2@1+ (1.0,0.0) [0.0|3] ""  Vector__XXX

BO_ 1412 HSP_01: 6 Gateway_PAG
 SG_ HSP_01_CRC : 0|8@1+ (1,0) [0|255] ""  Vector__XXX
 SG_ HSP_01_BZ : 8|4@1+ (1,0) [0|15] ""  Vector__XXX
 SG_ HSP_Taster : 12|1@1+ (1.0,0.0) [0.0|1] ""  Vector__XXX
 SG_ HSP_Status_LED : 13|1@1+ (1.0,0.0) [0.0|1] ""  Vector__XXX
 SG_ HSP_Warnung_LED : 14|1@1+ (1.0,0.0) [0.0|1] ""  Vector__XXX
 SG_ HSP_Warnung_Ton : 15|1@1+ (1.0,0.0) [0.0|1] ""  Vector__XXX
 SG_ HSP_Warnung_Text : 16|1@1+ (1.0,0.0) [0.0|1] ""  Vector__XXX
 SG_ HSP_Endlage_eingefahren : 17|1@1+ (1.0,0.0) [0.0|1] ""  OTA_FC
 SG_ HSP_Endlage_ausgefahren : 18|1@1+ (1.0,0.0) [0.0|1] ""  OTA_FC
 SG_ HSP_Unterspannung : 19|1@1+ (1.0,0.0) [0.0|1] ""  Vector__XXX
 SG_ HSP_Ueberspannung : 20|1@1+ (1.0,0.0) [0.0|1] ""  Vector__XXX
 SG_ HSP_Lokalaktiv : 21|1@1+ (1.0,0.0) [0.0|1] ""  Vector__XXX
 SG_ HSP_ResponseError : 22|1@1+ (1.0,0.0) [0.0|1] ""  Vector__XXX
 SG_ HSP_ErrorGueltigkeit_1 : 23|1@1+ (1.0,0.0) [0.0|1] ""  Vector__XXX
 SG_ HSP_ErrorGueltigkeit_2 : 24|1@1+ (1.0,0.0) [0.0|1] ""  Vector__XXX
 SG_ HSP_def : 25|1@1+ (1.0,0.0) [0.0|1] ""  Vector__XXX
 SG_ HSP_Motor_def : 26|1@1+ (1.0,0.0) [0.0|1] ""  Vector__XXX
 SG_ HSP_Spoiler_Error : 27|1@1+ (1.0,0.0) [0.0|1] ""  Vector__XXX
 SG_ HSP_Taster_Error : 28|1@1+ (1.0,0.0) [0.0|1] ""  Vector__XXX
 SG_ HSP_LED_Error : 29|1@1+ (1.0,0.0) [0.0|1] ""  Vector__XXX
 SG_ HSP_Spielschutz : 30|1@1+ (1.0,0.0) [0.0|1] ""  Vector__XXX
 SG_ HSP_Motor_Temp_Text : 31|1@1+ (1.0,0.0) [0.0|1] ""  Vector__XXX
 SG_ HSP_Charisma_FahrPr : 32|4@1+ (1.0,0.0) [0.0|15] ""  Vector__XXX
 SG_ HSP_Charisma_Status : 36|2@1+ (1.0,0.0) [0.0|3] ""  Vector__XXX
 SG_ HSP_man_Betaet_nicht_zulaessig : 38|1@1+ (1.0,0.0) [0.0|1] ""  Vector__XXX
 SG_ HSP_Komponentensteuerung : 39|1@1+ (1.0,0.0) [0.0|1] ""  Vector__XXX
 SG_ HSP_BAP_Messages : 40|4@1+ (1.0,0.0) [0.0|15] ""  Vector__XXX

BO_ 1283 HVK_01: 8 Gateway
 SG_ HVK_01_CRC : 0|8@1+ (1,0) [0|255] ""  Vector__XXX
 SG_ HVK_01_BZ : 8|4@1+ (1,0) [0|15] ""  Vector__XXX
 SG_ HVK_Istmodus_Anf : 12|1@1+ (1.0,0.0) [0.0|1] ""  Vector__XXX
 SG_ HVK_TN1_Sollmodus : 13|2@1+ (1.0,0.0) [0.0|3] ""  Vector__XXX
 SG_ HVK_MO_EmSollzustand : 16|8@1+ (1.0,0.0) [0.0|255] ""  Vector__XXX
 SG_ HVK_BMS_Sollmodus : 24|3@1+ (1.0,0.0) [0.0|7] ""  ZR_High
 SG_ HVK_DCDC_Sollmodus : 27|3@1+ (1.0,0.0) [0.0|7] ""  Vector__XXX
 SG_ HVK_EKK_Sollmodus : 30|3@1+ (1.0,0.0) [0.0|7] ""  Vector__XXX
 SG_ HVK_HVPTC_Sollmodus : 33|3@1+ (1.0,0.0) [0.0|7] ""  Vector__XXX
 SG_ HVK_HVLM_Sollmodus : 36|3@1+ (1.0,0.0) [0.0|7] ""  Vector__XXX
 SG_ HVK_HV_Netz_Warnungen : 39|2@1+ (1.0,0.0) [0.0|3] ""  ZR_High
 SG_ HV_Bordnetz_aktiv : 41|1@1+ (1.0,0.0) [0.0|1] ""  OTA_FC
 SG_ HV_Bordnetz_Fehler : 42|1@1+ (1.0,0.0) [0.0|1] ""  ZR_High
 SG_ HVK_Gesamtst_Spgfreiheit : 43|2@1+ (1.0,0.0) [0.0|3] ""  ZR_High
 SG_ HVK_AktiveEntladung_Anf : 45|1@1+ (1.0,0.0) [0.0|1] ""  Vector__XXX
 SG_ HVK_Iso_Messung_Start : 50|3@1+ (1.0,0.0) [0.0|7] ""  Vector__XXX
 SG_ HVK_AIAD_Sollmodus_2 : 53|1@1+ (1.0,0.0) [0.0|1] ""  Vector__XXX
 SG_ HVK_DCDC_EKK_Sollmodus : 62|2@1+ (1.0,0.0) [0.0|3] ""  Vector__XXX

BO_ 1340 HVLM_04: 8 Gateway
 SG_ HVLM_04_CRC : 0|8@1+ (1,0) [0|255] ""  Vector__XXX
 SG_ HVLM_04_BZ : 8|4@1+ (1,0) [0|15] ""  Vector__XXX
 SG_ HVLM_STH_Betriebsmodus : 12|3@1+ (1.0,0.0) [0.0|7] ""  ZR_High
 SG_ HVLM_Standklima_Timer_Status : 15|1@1+ (1.0,0.0) [0.0|1] ""  ZR_High
 SG_ HVLM_HVEM_MaxLeistung : 16|9@1+ (50,0) [0|25450] "Unit_Watt"  Vector__XXX
 SG_ HVLM_Status_Netz : 25|1@1+ (1.0,0.0) [0.0|1] ""  ZR_High
 SG_ HVLM_Anf_Ladescreen : 26|1@1+ (1.0,0.0) [0.0|1] ""  ZR_LIMU,ZR_MIB_TOP_ab_Gen3
 SG_ HVLM_Ladeart : 27|2@1+ (1.0,0.0) [0.0|3] ""  OTA_FC,ZR_High
 SG_ HVLM_VK_STH_Einsatz : 29|3@1+ (1.0,0.0) [0.0|7] ""  ZR_High
 SG_ HVLM_VK_Modus : 32|2@1+ (1.0,0.0) [0.0|3] ""  OTA_FC,ZR_High
 SG_ HVLM_IstModus_02 : 34|2@1+ (1.0,0.0) [0.0|3] ""  OTA_FC,ZR_High
 SG_ HVLM_HV_Anf : 36|2@1+ (1.0,0.0) [0.0|3] ""  ZR_High
 SG_ HVLM_Fehlerstatus : 38|3@1+ (1.0,0.0) [0.0|7] ""  OTA_FC,ZR_High
 SG_ HVLM_Anforderung_HMS : 41|3@1+ (1.0,0.0) [0.0|7] ""  Vector__XXX
 SG_ HVLM_Parken_beibehalten_HMS : 44|2@1+ (1.0,0.0) [0.0|3] ""  OTA_FC
 SG_ HVLM_Status_Tankklappe : 46|2@1+ (1.0,0.0) [0.0|3] ""  Vector__XXX
 SG_ HVLM_AWC_Sollmodus : 48|3@1+ (1.0,0.0) [0.0|7] ""  ZR_High
 SG_ HVLM_Stecker_Status : 51|2@1+ (1.0,0.0) [0.0|3] ""  OTA_FC,ZR_High
 SG_ HVLM_LadeAnforderung : 53|3@1+ (1.0,0.0) [0.0|7] ""  ZR_High
 SG_ HVLM_MaxBatLadestromHV : 56|8@1+ (1,0) [0|253] "Unit_Amper"  Vector__XXX

BO_ 1524 Innenlicht_11: 8 Gateway
 SG_ IL_Dimmung_V_Tuerkontur : 0|8@1+ (1,0) [0|100] "Unit_PerCent"  ZR_High
 SG_ IL_Dimmung_H_Tuerkontur : 8|8@1+ (1,0) [0|100] "Unit_PerCent"  ZR_High
 SG_ IL_Dimmung_Tuerinnengriff : 16|8@1+ (1,0) [0|100] "Unit_PerCent"  ZR_High
 SG_ IL_Dimmung_Umfeldbel : 24|8@1+ (1,0) [0|100] "Unit_PerCent"  ZR_High
 SG_ IL_Bel_FS_Ausstieg : 32|1@1+ (1.0,0.0) [0.0|1] ""  ZR_High
 SG_ IL_Bel_BFS_Ausstieg : 33|1@1+ (1.0,0.0) [0.0|1] ""  ZR_High
 SG_ IL_Bel_HFS_Ausstieg : 34|1@1+ (1.0,0.0) [0.0|1] ""  ZR_High
 SG_ IL_Bel_HBFS_Ausstieg : 35|1@1+ (1.0,0.0) [0.0|1] ""  ZR_High
 SG_ BCM1_Innenlicht_gedimmt_V : 36|1@1+ (1.0,0.0) [0.0|1] ""  ZR_High
 SG_ BCM1_Innenlicht_gedimmt_H : 37|1@1+ (1.0,0.0) [0.0|1] ""  ZR_High
 SG_ IL_Innenlicht_aktiv : 38|1@1+ (1.0,0.0) [0.0|1] ""  ZR_High
 SG_ IL_Klemme_30G_aktiv : 39|1@1+ (1.0,0.0) [0.0|1] ""  Vector__XXX
 SG_ BCM1_DI_Rampe_Innenlicht : 40|1@1+ (1.0,0.0) [0.0|1] ""  ZR_High
 SG_ BCM1_DI_Rampe_Leselicht : 41|1@1+ (1.0,0.0) [0.0|1] ""  ZR_High
 SG_ BCM1_Innenlicht_H : 42|1@1+ (1.0,0.0) [0.0|1] ""  ZR_High
 SG_ BCM1_Innenlicht_V : 43|1@1+ (1.0,0.0) [0.0|1] ""  ZR_High
 SG_ BCM1_Leselicht_Anf_hl : 44|1@1+ (1.0,0.0) [0.0|1] ""  ZR_High
 SG_ BCM1_Leselicht_Anf_hr : 45|1@1+ (1.0,0.0) [0.0|1] ""  ZR_High
 SG_ BCM1_Leselicht_Anf_vl : 46|1@1+ (1.0,0.0) [0.0|1] ""  ZR_High
 SG_ BCM1_Leselicht_Anf_vr : 47|1@1+ (1.0,0.0) [0.0|1] ""  ZR_High
 SG_ BCM1_Leuchten_Aus : 48|1@1+ (1.0,0.0) [0.0|1] ""  ZR_High
 SG_ AMB_Charisma_FahrPr : 49|4@1+ (1.0,0.0) [0.0|15] ""  Vector__XXX
 SG_ AMB_Charisma_Status : 53|2@1+ (1.0,0.0) [0.0|3] ""  Vector__XXX
 SG_ IL_Dimmung_Lautspr : 56|8@1+ (1,0) [0|100] "Unit_PerCent"  ZR_High

BO_ 312 IPA_01: 8 Gateway
 SG_ IPA_01_CRC : 0|8@1+ (1,0) [0|255] ""  Vector__XXX
 SG_ IPA_01_BZ : 8|4@1+ (1,0) [0|15] ""  Vector__XXX
 SG_ IPA_Anforderung_HMS : 12|3@1+ (1.0,0.0) [0.0|7] ""  ZR_High
 SG_ Parken_aktives_System : 16|4@1+ (1.0,0.0) [0.0|15] ""  DDA,ZR_High
 SG_ Parken_erhoehtes_Moment : 20|4@1+ (1.0,0.0) [0.0|15] ""  Vector__XXX
 SG_ Parken_Motorlauf_Anf : 25|2@1+ (1.0,0.0) [0.0|3] ""  Vector__XXX
 SG_ IPA_Fahrstufenwunsch : 27|3@1+ (1.0,0.0) [0.0|7] ""  Vector__XXX
 SG_ IPA_Status : 32|4@1+ (1.0,0.0) [0.0|15] ""  Vector__XXX
 SG_ IPA_Status_IPA_GE : 36|3@1+ (1.0,0.0) [0.0|7] ""  Vector__XXX
 SG_ IPA_Status_IPA_TSK : 40|4@1+ (1.0,0.0) [0.0|15] ""  Vector__XXX
 SG_ IPA_Sollbeschleunigung : 44|9@1+ (0.01,-4.11) [-4.10|1.00] "Unit_MeterPerSeconSquar"  Vector__XXX
 SG_ Parken_Fahrbereitschaft_Anf : 53|1@1+ (1.0,0.0) [0.0|1] ""  Vector__XXX
 SG_ IPA_Parken_beibehalten_HMS : 54|2@1+ (1.0,0.0) [0.0|3] ""  Vector__XXX
 SG_ IPA_PLA_LED : 58|3@1+ (1.0,0.0) [0.0|7] ""  Vector__XXX
 SG_ IPA_APS_LED : 61|3@1+ (1.0,0.0) [0.0|7] ""  Vector__XXX

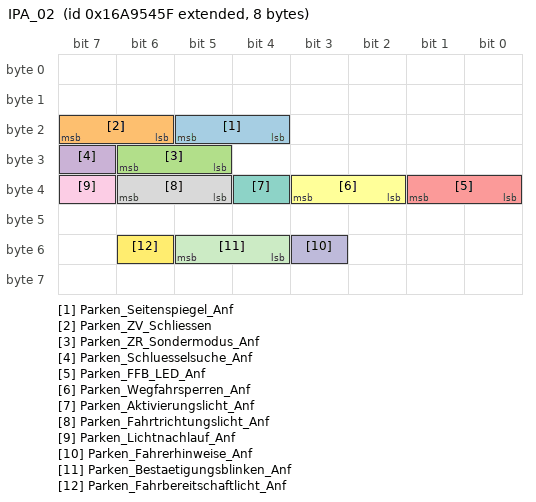
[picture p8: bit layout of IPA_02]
BO_ 2527679583 IPA_02: 8 Gateway
 SG_ Parken_Seitenspiegel_Anf : 20|2@1+ (1.0,0.0) [0.0|3] ""  ZR_High
 SG_ Parken_ZV_Schliessen : 22|2@1+ (1.0,0.0) [0.0|3] ""  ZR_High
 SG_ Parken_ZR_Sondermodus_Anf : 29|2@1+ (1.0,0.0) [0.0|3] ""  DDA,ZR_High,ZR_LIMU,ZR_MIB_TOP_ab_Gen3,ZR_Standard
 SG_ Parken_Schluesselsuche_Anf : 31|1@1+ (1.0,0.0) [0.0|1] ""  Vector__XXX
 SG_ Parken_FFB_LED_Anf : 32|2@1+ (1.0,0.0) [0.0|3] ""  Vector__XXX
 SG_ Parken_Wegfahrsperren_Anf : 34|2@1+ (1.0,0.0) [0.0|3] ""  Vector__XXX
 SG_ Parken_Aktivierungslicht_Anf : 36|1@1+ (1.0,0.0) [0.0|1] ""  Vector__XXX
 SG_ Parken_Fahrtrichtungslicht_Anf : 37|2@1+ (1.0,0.0) [0.0|3] ""  Vector__XXX
 SG_ Parken_Lichtnachlauf_Anf : 39|1@1+ (1.0,0.0) [0.0|1] ""  Vector__XXX
 SG_ Parken_Fahrerhinweise_Anf : 51|1@1+ (1.0,0.0) [0.0|1] ""  Vector__XXX
 SG_ Parken_Bestaetigungsblinken_Anf : 52|2@1+ (1.0,0.0) [0.0|3] ""  ZR_High
 SG_ Parken_Fahrbereitschaftlicht_Anf : 54|1@1+ (1.0,0.0) [0.0|1] ""  Vector__XXX

BO_ 1903 ISO_AMP_Req: 8 Gateway
 SG_ ISO_AMP_Req_Data : 0|64@1+ (1.0,0.0) [0.0|18446744073709551615] ""  ZR_High,ZR_MIB_TOP_ab_Gen3,ZR_Standard

BO_ 2009 ISO_AMP_Resp: 8 ZR_High
 SG_ ISO_AMP_Resp_Data : 0|64@1+ (1.0,0.0) [0.0|18446744073709551615] ""  Gateway,Gateway_PAG

BO_ 1792 ISO_Funktionaler_Req_All: 8 Gateway
 SG_ ISO_ALL_01_Req_Data : 0|64@1+ (1.0,0.0) [0.0|18446744073709551615] ""  BedienDisp_vo,BedienSG_hi,DDA,GurtMikrofon,ZR_High,ZR_LIMU,ZR_MIB_TOP_ab_Gen3,ZR_Standard

BO_TX_BU_ 705 :Gateway,Gateway_PAG;
BO_TX_BU_ 2463978619 :Gateway,Gateway_PAG;
BO_TX_BU_ 2527679660 :Gateway,Gateway_PAG;
BO_TX_BU_ 707 :Gateway,Gateway_PAG;
BO_TX_BU_ 1605 :Gateway,Gateway_PAG;
BO_TX_BU_ 2589283684 :Gateway,Gateway_PAG;
BO_TX_BU_ 2549875571 :Gateway,Gateway_PAG;
BO_TX_BU_ 2550006643 :ZR_High,ZR_LIMU,ZR_MIB_TOP_ab_Gen3;
BO_TX_BU_ 173 :Gateway,Gateway_PAG;
BO_TX_BU_ 968 :Gateway,Gateway_PAG;
BO_TX_BU_ 177 :Gateway,Gateway_PAG;
BO_TX_BU_ 879 :Gateway,Gateway_PAG;
BO_TX_BU_ 884 :Gateway,Gateway_PAG;
BO_TX_BU_ 886 :Gateway,Gateway_PAG;
BO_TX_BU_ 888 :Gateway,Gateway_PAG;
BO_TX_BU_ 891 :Gateway,Gateway_PAG;
BO_TX_BU_ 1364 :Gateway,Gateway_PAG;
BO_TX_BU_ 299 :Gateway,Gateway_PAG;
BO_TX_BU_ 310 :Gateway,Gateway_PAG;
BO_TX_BU_ 1410 :Gateway,Gateway_PAG;
BO_TX_BU_ 1416 :Gateway,Gateway_PAG;
BO_TX_BU_ 1016 :Gateway,Gateway_PAG;
BO_TX_BU_ 1283 :Gateway,Gateway_PAG;
BO_TX_BU_ 1340 :Gateway,Gateway_PAG;
BO_TX_BU_ 1524 :Gateway,Gateway_PAG;
BO_TX_BU_ 312 :Gateway,Gateway_PAG;
BO_TX_BU_ 2527679583 :Gateway,Gateway_PAG;
BO_TX_BU_ 1903 :Gateway,Gateway_PAG;
BO_TX_BU_ 2009 :ZR_High,ZR_MIB_TOP_ab_Gen3,ZR_Standard;
BO_TX_BU_ 1792 :Gateway,Gateway_PAG;
CM_ BO_ 879 "Nachricht 1 für Ortung:
Position und Fixtyp.";
CM_ BO_ 884 "Nachricht 2 für Ortung:
Latenz, Geschwindigkeit und Richtung.";
CM_ BO_ 886 "Nachricht 3 für Ortung:
Qualität der Ortung.";
CM_ BO_ 888 "Nachricht 4 für Ortung:
Zeitstempel der Ortung.";
CM_ BO_ 891 "Nachricht 5:
Empfängerstatus und UTC.";
CM_ BO_ 1364 "Nachricht 6:
Enthält Informationen über die Satelliten. Die Daten des stärksten Satelliten werden übertragen";
CM_ BO_ 1416 "Heizleistungsregelung";
CM_ BO_ 1016 "Heizleistungsregelung 
MLBevo (NVEM im Gateway)";
CM_ BO_ 1340 "CAN-Botschaft";
CM_ BO_ 2527679583 "ehemals ZFAS_01";

CM_ SG_ 2527679896 EFP_ReifenTempOf_HL "Oberflächennahe Reifentemperatur";
CM_ SG_ 2527679896 EFP_ReifenTempOf_HR "Oberflächennahe Reifentemperatur";
CM_ SG_ 2527679896 EFP_ReifenTempOf_VL "Oberflächennahe Reifentemperatur";
CM_ SG_ 2527679896 EFP_ReifenTempOf_VR "Oberflächennahe Reifentemperatur";
CM_ SG_ 2527679896 FA_FahrerAnf_Lift_Abwurf "Fahrer Lift Anforderung Abwurf";
CM_ SG_ 2527679896 FA_Niveau_AOCCT_fehlerstatus "Berechnung ActiveOffCycleCreditTechnology: Fahrwerk Niveau Fehler";
CM_ SG_ 2527679896 FA_Niveau_AOCCT_teststatus "Berechnung ActiveOffCycleCreditTechnology: Fahrwerk Niveau Diagnose durchgeführt";
CM_ SG_ 2527679896 FA_Niveau_AOCCT_timer1_count "Berechnung ActiveOffCycleCreditTechnology: Timer 1 für Fahrwerk Niveau Position <75%";
CM_ SG_ 2527679896 FA_Niveau_AOCCT_timer1_verbaut "Berechnung ActiveOffCycleCreditTechnology: Timer 1 für Fahrwerk Niveau verbaut und codiert";
CM_ SG_ 2527679896 FA_Niveau_AOCCT_timer2_count "Berechnung ActiveOffCycleCreditTechnology: Timer 2 für Fahrwerk Niveau Position >=75%";
CM_ SG_ 2527679896 FA_Niveau_AOCCT_timer2_verbaut "Berechnung ActiveOffCycleCreditTechnology: Timer 2 für Fahrwerk Niveau verbaut und codiert";
CM_ SG_ 2527679896 FA_Zuladung_HA "Signal für die Zuladung der Hinterachse aus dem EFP als delta Gewicht zu der kodierten Gewichtsklasse.";
CM_ SG_ 2527679896 FA_Zuladung_Status_HA "Status für die Zuladung der Hinterachse aus dem EFP";
CM_ SG_ 2527679896 FA_Zuladung_Status_VA "Status für die Zuladung der Vorderachse aus dem EFP";
CM_ SG_ 2527679896 FA_Zuladung_VA "Signal für die Zuladung der Vorderachse aus dem EFP als delta Gewicht zu der kodierten Gewichtsklasse.";
CM_ SG_ 2527679896 Fahrwerk_12_BZ "4bit Botschaftszähler, wird mit jeder Sendebotschaft inkrementiert";
CM_ SG_ 2527679896 Fahrwerk_12_CRC "Checksumme

Berechnung siehe Lastenheft 'End-to-End-Kommunkationsabsicherung'";

CM_ SG_ 705 DR_Warnung "Signal zur Ansteuerung von Dämpferregler-Warnungen im Kombiinstrument.";
CM_ SG_ 705 eABC_Texte "Signal zur Ansteuerung von Fahrerhinweisen im Kombi seitens eABC.";
CM_ SG_ 705 eABC_Warnung_Prio1 "Signal zur Ansteuerung von Prio1 Warnmeldungein im Kombi seitens eABC.";
CM_ SG_ 705 eABC_Warnung_Prio2 "Signal zur Ansteuerung von Prio2 Warnmeldungein im Kombi seitens eABC.";
CM_ SG_ 705 eAWS_Warnmeldung_Prio1 "Signal zur Ansteuerung der Prio1 Warnmeldung für das eAWS im Kombi ";
CM_ SG_ 705 eAWS_Warnmeldung_Prio2 "Signal zur Ansteuerung der Prio2 Warnmeldung für das eAWS im Kombi";
CM_ SG_ 705 EFP_Status_Taster_Fahrwerk "Status des EFP PAG Fahrwerkmodus";
CM_ SG_ 705 EFP_Status_Taster_Lift "Status des EFP Liftmodus";
CM_ SG_ 705 EFP_Verbau_DR "Verbauinfo Dämpferfunktion im EFP";
CM_ SG_ 705 EFP_Verbau_eABC "Verbauinfo eABC";
CM_ SG_ 705 EFP_Verbau_eAllrad "Verbauinfo eAllrad-Funktion im EFP";
CM_ SG_ 705 EFP_Verbau_eAWS "Verbauinfo eAWS";
CM_ SG_ 705 EFP_Verbau_LF "Verbauinfo Luftfederfunktion im EFP";
CM_ SG_ 705 EFP_Warnung_Naesse "Signal zur Ansteuerung von Naesse-Erkennung-Warnungen im Kombiinstrument";
CM_ SG_ 705 EFP_Warnung_Naesse_verf "Signal zur Ansteuerung von Fahrerhinweisen im Kombi";
CM_ SG_ 705 Fahrwerk_Anzeige_01_CRC "Für MLB:
'Berechnung siehe Lastenheft 'Kommunikationsabsicherung für FlexRay und CAN''

Ab MQB und MLBevo:
'Berechnung siehe Lastenheft 'End-to-End Kommunikationsabsicherung''

Endwerte siehe Begleitdokument 'S-PDU Kennungsfolgen'";
CM_ SG_ 705 FDR_Warnung_ALR "Warnmeldungen der Allradverteilung";
CM_ SG_ 705 FDR_Warnung_TV "Signal zur Ansteuerung von Warnungen im Kombi";
CM_ SG_ 705 LF_Texte "Signal zur Ansteuerung von Fahrerhinweisen im Kombi";
CM_ SG_ 705 LF_Texte_2 "Signal zur Ansteuerung von Fahrerhinweisen im Kombi";
CM_ SG_ 705 LF_Warnung_Prio1 "Signal zur Ansteuerung von Prio1-Warnungen im Kombi";
CM_ SG_ 705 LF_Warnung_Prio1_02 "Signal zur Ansteuerung von Prio1-Warnungen seitens Niveau im Kombi";
CM_ SG_ 705 LF_Warnung_Prio2 "Signal zur Ansteuerung von Prio2-Warnungen im Kombi";
CM_ SG_ 705 NR_LED_Ladelevel "Statusrückmeldung der eingestelten Fahrzeughöhe Ladelevel";
CM_ SG_ 705 NR_LED_Offroadlevel "Statusrückmeldung der eingestelten Fahrzeughöhe Offroadlevel";
CM_ SG_ 705 NR_LED_Strassenlevel "Statusrückmeldung der eingestelten Fahrzeughöhe Strassenlevel";
CM_ SG_ 705 NR_LED_Sync "Statusrückmeldung der Synchronität zwischen Luftfedersystem und Fahrprofilauswahl";
CM_ SG_ 705 NR_LED_XtraLevel "Statusrückmeldung der eingestelten Fahrzeughöhe XtraLevel";

CM_ SG_ 2463978619 FAS_SollStatus_Fkt_AbstWarn_LRR "FAS-ProfileMaster Sollstatus der Kundenfunktion";
CM_ SG_ 2463978619 FAS_SollStatus_Fkt_AbstWarn_MV "FAS-ProfileMaster Sollstatus der Kundenfunktion";
CM_ SG_ 2463978619 FAS_SollStatus_Fkt_ASW "FAS-ProfileMaster Sollstatus der Kundenfunktion";
CM_ SG_ 2463978619 FAS_SollStatus_Fkt_LGI "FAS-ProfileMaster Sollstatus der Kundenfunktion";
CM_ SG_ 2463978619 FAS_SollStatus_Fkt_MKE "FAS-ProfileMaster Sollstatus der Kundenfunktion";
CM_ SG_ 2463978619 FAS_SollStatus_Fkt_NV "FAS-ProfileMaster Sollstatus der Kundenfunktion";
CM_ SG_ 2463978619 FAS_SollStatus_Fkt_PreCrash "FAS-ProfileMaster Sollstatus der Kundenfunktion";
CM_ SG_ 2463978619 FAS_SollStatus_Fkt_STP "FAS-ProfileMaster Sollstatus der Kundenfunktion";
CM_ SG_ 2463978619 FAS_SollStatus_Fkt_SWA "FAS-ProfileMaster Sollstatus der Kundenfunktion";

CM_ SG_ 2527679660 FB_Blindheit "Blindheit: Sensor operativ aber Sichtbeeinträchtigung";
CM_ SG_ 2527679660 FB_Fahrerwechsel "Fahrerwechsel erkannt";
CM_ SG_ 2527679660 FB_Fehler "Fehler liegt vor";
CM_ SG_ 2527679660 FB_Kopfaktivitaet_A1 "kurzfristige Kopfbewegungen
";
CM_ SG_ 2527679660 FB_Kopfaktivitaet_A1_Guete "Guete kurzfristige Kopfbewegung";
CM_ SG_ 2527679660 FB_Kopfaktivitaet_A2 "langfristige Kopfbewegungen
";
CM_ SG_ 2527679660 FB_Kopfaktivitaet_A2_Guete "Guete Langfristige Kopfbewegung";
CM_ SG_ 2527679660 FB_Muedigkeit_Guete "Güte der Müdigkeitserkennung";
CM_ SG_ 2527679660 FB_Muedigkeit_Index "Müdigkeitsignal nach HFC Müdigkeitsskala";
CM_ SG_ 2527679660 FB_NichtVerfuegbar "Fahrerbeobachtung nicht verfügbar";

CM_ SG_ 707 eAWS_Warnmeldung_Prio3 "Signal zur Ansteuerung der Prio3 Warnmeldung für das eAWS im Kombi";
CM_ SG_ 707 EFP_Anf_Kuehlklappenwarnung "Signal wird zur Ansteuerung einer Kühlklappenwarnung im Kombiinstrument genutzt";
CM_ SG_ 707 EFP_MomRad_Begr "Begrenzung des beschleunigt wirkenden Antriebstrangsollmomentenanteils auf Summenradebene 
Für MLBevo: Faktor in TS_Faktor_Radmomente beachten!";
CM_ SG_ 707 FA_Warnung_Transportniveau "Signal zur Ansteuerung einer Warnmeldung, wenn beim Transportmodus das Zielniveau nicht angefahren wird";
CM_ SG_ 707 FDR_04_BZ "4bit Botschaftszähler, wird mit jeder Sendebotschaft inkrementiert";
CM_ SG_ 707 FDR_04_CRC "Für MLB:
Berechnung siehe Lastenheft 'Kommunikationsabsicherung für FlexRay und CAN'
Ab MQB und MLBevo:
Berechnung siehe Lastenheft 'End-to-End Kommunikationsabsicherung'

Endwerte siehe Begleitdokument 'S-PDU Kennungsfolgen'";
CM_ SG_ 707 FDR_M_HL_02 "Momentenanzeige für MMI.";
CM_ SG_ 707 FDR_M_HR_02 "Momentenanzeige für MMI.";
CM_ SG_ 707 FDR_M_VL_02 "Momentenanzeige für MMI.";
CM_ SG_ 707 FDR_M_VR_02 "Momentenanzeige für MMI.";

CM_ SG_ 1605 FLA_Abblendursache "FLA Abblendursache
(20ms Task)";
CM_ SG_ 1605 FLA_aktiv "FLA aktiv  (200ms Task)";
CM_ SG_ 1605 FLA_Aufblenden "FLA Aufblenden (20ms Task)";
CM_ SG_ 1605 FLA_Fernlicht_PWM "FLA PWM Vorgabe Fernlicht
(20ms Task)";
CM_ SG_ 1605 FLA_ISP_defekt "FLA Innenspiegel defekt
interner Fehler  (200ms Task)";
CM_ SG_ 1605 FLA_SAE_Mode "Rückmeldung an den Fahrer, über Wechsel in den SAE Modus --> wird nur für den amerikanischen Markt benötigt.";
CM_ SG_ 1605 FLA_Sensor_blockiert "FLA Sensor blockiert
Sichtbeeinträchtigung CMOS-Kamera  (200ms Task)";
CM_ SG_ 1605 ISP_Dimmung_ASP_02 "Dimmwertvorgabe für Aussenspiegel
Es wird 1:1 die Spannung am Innenspiegel nach außen übertragen.";
CM_ SG_ 1605 ISP_EC_aktiv "Status Innenspiegel (EC-Spiegel)";
CM_ SG_ 1605 ISP_EC_Lichtwert_hinten "Innenspiegel: Lichtwert hinten
";
CM_ SG_ 1605 ISP_EC_Lichtwert_vorne "Innenspiegel: Lichtwert vorne
";
CM_ SG_ 1605 ISP_Himmelsrichtung "Himmelsrichtung Kompass im EC Spiegel
Wertebereich 0-29 (12°-Schritte, 0-348°)
";
CM_ SG_ 1605 ISP_Kompass_aktiv "Status Kompass Innenspiegel";
CM_ SG_ 1605 ISP_Taste_betaetigt "ISP Taste betätigt
(200ms Task)";

CM_ SG_ 2589283684 FoD_Anz_Funktionsabschaltung "Signal triggert Aufschaltung eines Popups, um dem Fahrer die Abschaltung einer Funktion zu melden.";
CM_ SG_ 2589283684 FoD_Transmission_Info "Mit dem Signal zeigt der FoD-Master allen FoD-Slaves den Beginn und das Ende eines Freischaltuebertragungszykluses (FS-ID-Zyklus) an.";

CM_ SG_ 2549875571 FoD_ZR_Req_Data "FoD - Function On Demand
ISO-TP Datenkanal - FID2NA
Request Funktion 0x03 FoD-Master

FoD-Master an Zentralrechner";

CM_ SG_ 2550006643 FoD_ZR_Resp_Data "FoD - Function On Demand
ISO-TP Datenkanal - FID2NA
Response Knoten 0x73 Zentralrechner

Zentralrechner an FoD Master";

CM_ SG_ 173 GE_Fahrstufe "Fahrprogramm des Getriebes

Hinweis: Zwischenstellung '0x0' darf nur für Zustandswechsel P/R, R/N, N/D ausgegeben werden, nicht für D/S oder D/Tippgasse wegen Abschaltkriterium GRA/ACC";
CM_ SG_ 173 GE_Freig_MMom_Vorhalt "Freigabe für die Anforderung einer Momentenreserve durch das Getriebe über das Signal
MLB: GE_MMom_Vorhalt
MQB/MLBevo: GE_MMom_Vorhalt_02";
CM_ SG_ 173 GE_MMom_Soll_02 "Momenteneingriff an den Motor.
Fordert vom MSG eine kurzfristige Reduzierung oder Anhebung des Moments.
Das Signal ist nur gültig in Kombination mit GE_MMom_Status (bei MQB) bzw. GE_MMom_Status_02 (bei MLBevo).

Achtung:
Einheitenloser Wert! Faktor i";
CM_ SG_ 173 GE_MMom_Status "Qualifiziert 
MLB: GE_MMom_Soll
MQB: GE_MMom_Soll_02";
CM_ SG_ 173 GE_MMom_Status_02 "Das Signal qualifiziert GE_MMom_Soll_02 und gibt an, wie der Wert aus GE_MMom_soll – vorbehaltlich der Umsetzbarkeit aufgrund motorinterner Restriktionen – umgesetzt werden soll.
Werte:
0= kein Eingriff
1=   absoluter reduzierender Eingriff auf Gesamt ";
CM_ SG_ 173 GE_MMom_Vorhalt_02 "Anforderung einer Momentenreserve durch das Getriebe, gilt nur mit Freigabe durch 
GE_Freig_MMom_Vorhalt

Anforderung wird als Absolut-Wert umgesetzt, nicht als Relativ-Wert/Delta zum aktuellen Ist-Moment (d. h. eine Momentenreserve wird eingestellt, w";
CM_ SG_ 173 GE_reserv_Fahrstufe "reserviert, falls künftig Erweiterung von GE_Fahrstufe nötig";
CM_ SG_ 173 GE_Schaltablauf "Das Signal zeigt den aktuellen Status eines Schaltvorgangs.

Bei Signal = 0 liegt kein Schaltvorgang vor.
Bei Signal =2 liegt die Befüllphase der zuschaltenden Kupplung bzw. 
                      die Vorbereitungsphase dazu vor.

Mit den unterschie";
CM_ SG_ 173 GE_Status_Kraftschluss "Zeigt den Ist-Status des Kraftschlusses im Getriebe.
(Anmerkung: meist wird damit der Zustand des Anfahrelements beschrieben, d.h. bei DL/DQ die Kupplung;  bei AQ/AL der Wandler incl. Überbrückungskupplung)
0 = offen, kein Kraftschluss
1 = offen mit Kr";
CM_ SG_ 173 GE_Uefkt "Übertragungsfunktion des Getriebes
Drehzahlverhältnis = Eingangsdrehzahl / Ausgangsdrehzahl

AL: Wandlerverstärkung x Drehzahlverhältnis
VL: Drehzahlverhältnis
DL: Drehzahlverhältnis der aktiven und kraftschluß führenden Welle zum Abtrieb, bei Schalt";
CM_ SG_ 173 GE_Uefkt_unplausibel "Das Signal darf nur im Reku-Manager in Hybrid-Varianten verwendet werden.
Zeigt an, ob die Plausibilisierung Momenten-Verhältnis zu Drehzahl-Verhältnis i.O. ist.
Ein gesetztes Signal meldet eine unplausible GE_Uefkt bzw. GE_Uefkt_02.";
CM_ SG_ 173 GE_Verbot_Ausblendung "Verbot Einspritzausblendung für komfortable Schaltungen";
CM_ SG_ 173 GE_Zielgang "VL-Getriebe:
Signalisiert den Zielgang im manuellen Modus während eines Schaltvorgangs bzw. die momentane simulierte Gangstufe wenn kein Schaltvorgang aktiv ist. In den Fahrprogrammen 'D' und 'S' ist die Übersetzung variabel und somit wird dauerhaft 'Ist";
CM_ SG_ 173 Getriebe_11_BZ "Botschaftszähler
Botschaft asynchron geroutet. Zählerwert kann springen.";
CM_ SG_ 173 Getriebe_11_CRC "Für MLB:
'Berechnung siehe Lastenheft 'Kommunikationsabsicherung für FlexRay und CAN''

Ab MQB und MLBevo:
'Berechnung siehe Lastenheft 'End-to-End Kommunikationsabsicherung''

Endwerte siehe Begleitdokument 'S-PDU Kennungsfolgen'";

CM_ SG_ 968 Freilauf_Charisma_FahrPr "MLBevo: Aktuelles Fahrprogramm des Charisma-Teilnehmers (siehe Systemlastenheft Drive Select)
MQB: Istwert der Kennlinie (siehe Systemlastenheft MQB FPA)";
CM_ SG_ 968 Freilauf_Charisma_Status "Charisma Systemstatus des Charisma-Teilnehmers

Wert 0x3 ist nur für Fahrzeuge ab MQB relevant";
CM_ SG_ 968 GE_amax_moeglich "AL/DL: maximal mögliche Beschleunigung unter Berücksichtigung aller möglichen Gänge.

Eine Reduzierung des maximalen Motormoments durch Efficiency wird in dem Signal berücksichtigt.

VL: maximal mögliche Beschleunigung bei Nenndrehzahl (Efficency wird";
CM_ SG_ 968 GE_Charisma_FahrPr "MLBevo: Aktuelles Fahrprogramm des Charisma-Teilnehmers (siehe Systemlastenheft Drive Select)
MQB: Istwert der Kennlinie (siehe Systemlastenheft MQB FPA)";
CM_ SG_ 968 GE_Charisma_Status "Charisma Systemstatus des Charisma-Teilnehmers

Wert 0x3 ist nur für Fahrzeuge ab MQB relevant";
CM_ SG_ 968 GE_Codierung_MSG "Statusausgabe der Diagnose für Falschverbau. Plausibilisierung der empfangenen Motor- und Getriebevariante mit der erwarteten Motor- und Getriebevarianten.";
CM_ SG_ 968 GE_Freigabe_Info_WFS "WFS-Freigabeinformation";
CM_ SG_ 968 GE_Freigabe_Verfallsinfo_WFS "WFS";
CM_ SG_ 968 GE_LaunchControl "Während einer LaunchControl-Anfahrt sendet das Getriebesteuergerät das Bit LaunchControl aktiv.
Die Bremse wertet dieses Bit aus, um während einer solchen Anfahrt die Regelgrenzen der Schlupfregelung zu erweitern.
Im Motor Nutzung zur Verbesserung des A";
CM_ SG_ 968 GE_LaunchControl_LB "LB launch control status";
CM_ SG_ 968 GE_LFR_Adaption "Qualifiziert das ausgegeben Motorbelastungsmoment (durch GE_Vorsteuermoment) für die Verwendung zur LFR (Leerlauffüllungsregelung) im Moto";
CM_ SG_ 968 GE_OBD_AbsperrVent "Das Getriebesteuergerät führt eine elektrische Diagnose des von ihm angesteuerten Absperrventils für den Öl-Wasser-Wärmetauscher durch und übermittelt das Ergebnis an das MSG (Standard-4Bit-OBD-Status, nicht alle Zustände müssen genutzt werden; so sind z.";
CM_ SG_ 968 GE_OBD_Status "Dieses Bit steuert die MIL-Lampe an (Motorsteuergerät reicht diese Info an Kombi weiter).";
CM_ SG_ 968 GE_Remotestart_Betrieb "Das GSG ist für den Remotestart-Betrieb bereit. Nach Empfang der Motorstartanforderung für RSt-Betrieb durch BCM wird der Fahrzeugmotor gestartet und solange der Motor läuft, bleibt dieses Bit aktiv. Dieses Signal ist nur zur Verwendung durch das BCM zur ";
CM_ SG_ 968 GE_Sperr_Info_WFS "WFS-Sperrinformation";
CM_ SG_ 968 GE_Status_PaddleNeutral "Status Ablauf der Paddle Neutral Funktion";
CM_ SG_ 968 GE_Sumpftemperatur "Getriebesumpftemperatur wird über den Temperatursensor auf der Getriebeplatine ermittelt. Die absolute Sumpftemperatur wird vom Motor empfangen, um entsprechende Kühlleistung für das Getriebe einzustellen.";
CM_ SG_ 968 GE_Zustand_Kuppltemp "Dieses Signal gibt den Temperaturzustand der Kupplung im DQ-Getriebe (z. Zt. DQ2x0, DQ500) an das ACC-System.";

CM_ SG_ 177 GE_Anschleppstart_Freigabe "Bilden einer Schleppstartfreigabe aus Fahrdynamiksicht. Schleppstartabbruch bei kritischer Fahrzeugstabilität";
CM_ SG_ 177 GE_Eingangsdrehz_Praed "prädizierte Getriebe-Eingangsdrehzahl (während Schaltungen kann die voraussichtliche Drehzahl am Ende der Schaltung gezeigt werden)";
CM_ SG_ 177 GE_Fahrprogramm "Signalisiert das Fahrprogramm  im Bezug auf
die Fahrstufe des Getriebes.

Audi/MQB:
Offroad

Bentley:
Snow
Gravel
Mud_Ruts
Sand_Dune

Touareg:
Offroad
Snow";
CM_ SG_ 177 GE_Freilauf_Status "Freilauf-Status-Signal vom Frailauf-Master an aktive Freilauf-Teilnehmer. In diesem Signal zeigt der Freilauf-Master an, welchen aktuellen Status die Freilauf-Betriebsstrategie hat.";
CM_ SG_ 177 GE_Getriebestatus_02 "Signalisierung von speziellen Betriebszuständen des Getriebes:
1= Rennstartvorbereitung; genutzt im MSG zum Aufbau einer Momentenreserve, in Allrad und Quersperre (GQS)
2= Rennstart; nicht genutzt im MSG
3= Anfahrt; genutzt im MSG zur Umschaltung des F";
CM_ SG_ 177 GE_Grundeinstellung "Grundeinstellung des Getriebes ist aktiv

Hinweis:
Verwendung nur im MQB";
CM_ SG_ 177 GE_KomFehler_ESP "Anzeige Kommunikationsfehler bei Empfang vom ESP.

Einsatz nur in PDK-Projekten.";
CM_ SG_ 177 GE_Rollrichtung_falsch "Rollrichtung des Fahrzeugs ist entgegen der eingelegten Fahrstufe (bezogen auf GE_Fahrstufe);
0 = Rollrichtung richtig bzw. Init (auch im Stillstand bzw. in P/N/Zwischenposition)
1 = Rollrichtung falsch";
CM_ SG_ 177 GE_Strombedarf_erh "Das GSG teilt dem MSG einen aufgrund der Kühlung erhöhten Strombedarf mit, damit gleichzeitig die Kühler-Lüfter-Ansteuerung kurzzeitig reduziert wird.

Signal wird bisher nur im MQB-PHEV verwendet.";
CM_ SG_ 177 GE_TippZustand "Zeigt den Tippzustand in eine Fahrstufe und ein Fahrprogramm via Paddles oder Schaltbetätigung an.
Das Signal ist gültig in Kombination mit GE_Fahrstufe und GE_Fahrprogramm.

MLBevo:
DL und AL: nur Tipp_in_permanent
PDK2: Tipp_in_temporaer und Tipp_i";
CM_ SG_ 177 GE_Uefkt_Praed "Praedizierte Triebstrangübertragungsfunktion 
(Verständnis Übertragungsfunktion gemäß Ge_Uefkt_02)
Weiterführende Informationen sind bei der entsprechenden Fachabteilung zu erfragen.";
CM_ SG_ 177 Getriebe_17_BZ "Botschaftszähler
Botschaft asynchron geroutet. Zählerwert kann springen.";
CM_ SG_ 177 Getriebe_17_CRC "Für MLB:
'Berechnung siehe Lastenheft 'Kommunikationsabsicherung für FlexRay und CAN''

Ab MQB und MLBevo:
'Berechnung siehe Lastenheft 'End-to-End Kommunikationsabsicherung''

Endwerte siehe Begleitdokument 'S-PDU Kennungsfolgen'";

CM_ SG_ 879 GNSS_Breite_Ortung "Breitengrad des Ortungsergebnisses nach WGS84 als Kombination von mehreren GNSSen";
CM_ SG_ 879 GNSS_Fehlerzustand "Fehlerzustand von der GNSS-Funktion, daraufhin können keine GNSS-Daten geliefert werden";
CM_ SG_ 879 GNSS_Laenge_Ortung "Längengrad des Ortungsergebnisses nach WGS84 als Kombination von mehreren GNSSen";
CM_ SG_ 879 GNSS_Nachrichtenpaket_ID1 "+1 für jedes neue Paket. Zyklische ID-Vergabe (Zähler). Zur Identifizierung zusammenhängender Nachrichten, die die Daten derselben GNSS-Ortung enthalten und somit zum selben Zyklus gehören. D.h. Daten in den Nachrichten wurden zur selben Zeit erzeugt. Der";
CM_ SG_ 879 GNSS_Ortung_FIX_Typ "Art des 'GNSS-Fix' für die aktuelle Position auf Basis mehrerer GNSS Systeme.";
CM_ SG_ 879 GNSS_Richtung_Breite_Ortung "Richtung des Breitengrads des Ortungsergebnisses nach WGS84 als Kombination von mehreren GNSSen";
CM_ SG_ 879 GNSS_Richtung_Laenge_Ortung "Richtung des Längengrads des Ortungsergebnisses nach WGS84 als Kombination von mehreren GNSSen";

CM_ SG_ 884 GNSS_Nachrichtenpaket_ID2 "+1 für jedes neue Paket. Zyklische ID-Vergabe (Zähler). Zur Identifizierung zusammenhängender Nachrichten, die die Daten derselben GNSS-Ortung enthalten und somit zum selben Zyklus gehören. D.h. Daten in den Nachrichten wurden zur selben Zeit erzeugt. Der";
CM_ SG_ 884 GNSS_Ortung_2D_Geschw_ue_Grund "Geschwindigkeit in m pro Sekunde entsprechend dem GNSS-Empfänger";
CM_ SG_ 884 GNSS_Ortung_Ausrichtung "Ausrichtung (Kurswinkel) der GNSS-Messung";
CM_ SG_ 884 GNSS_Ortung_Latenz "Latenz zwischen GNSS-Messung und aktueller Verteilung über CAN-Bus.
Hinweis: Zur Stabilisierung der Latenz soll die GNSS-Zeit für die Bestimmung der CAN-Zyklendauer verwendet werden.";
CM_ SG_ 884 GNSS_Ortung_Noerdliche_Geschw "Geschwindigkeit in m pro Sekunde in Nordrichtung entsprechend dem GNSS-Empfänger";
CM_ SG_ 884 GNSS_Ortung_Oestliche_Geschw "Geschwindigkeit in m pro Sekunde in Ostrichtung entsprechend dem GNSS-Empfänger";
CM_ SG_ 884 GNSS_Ortung_Vertikale_Geschw "Geschwindigkeit  in m pro Sekunde in vertikaler Richtung (aufwärts) entsprechend dem GNSS-Empfänger";

CM_ SG_ 886 GNSS_Nachrichtenpaket_ID3 "+1 für jedes neue Paket. Zyklische ID-Vergabe (Zähler). Zur Identifizierung zusammenhängender Nachrichten, die die Daten derselben GNSS-Ortung enthalten und somit zum selben Zyklus gehören. D.h. Daten in den Nachrichten wurden zur selben Zeit erzeugt. Der";
CM_ SG_ 886 GNSS_Ortung_GDOP "Synthetischer Wert für den Verlust an Präzision der Postions- und Zeitmessung auf Grund der Satellitenkonstellation";
CM_ SG_ 886 GNSS_Ortung_Guete_Ausrichtung "Gesamtgenauigkeit bezüglich der Ausrichtung (Kurswinkel)";
CM_ SG_ 886 GNSS_Ortung_Guete_Geschwindigk "Gesamtgenauigkeit bezüglich Geschwindigkeit am Erdboden";
CM_ SG_ 886 GNSS_Ortung_Guete_horizontal "Gesamtgenauigkeit bezüglich der 2D-Position (horzontal)";
CM_ SG_ 886 GNSS_Ortung_Guete_vertikal "Gesamtgenauigkeit bezüglich der 1D-Position (vertikal)";
CM_ SG_ 886 GNSS_Ortung_HDOP "Synthetischer Wert für den Verlust an Präzision der 2D-Postionsmessung (horizontal) auf Grund der Satellitenkonstellation";
CM_ SG_ 886 GNSS_Ortung_PDOP "Synthetischer Wert für den Verlust an Präzision der Postionsmessung auf Grund der Satellitenkonstellation";
CM_ SG_ 886 GNSS_Ortung_VDOP "Synthetischer Wert für den Verlust an Präzision der 1D-Postionsmessung (vertikal) auf Grund der Satellitenkonstellation";

CM_ SG_ 888 GNSS_Nachrichtenpaket_ID4 "+1 für jedes neue Paket. Zyklische ID-Vergabe (Zähler). Zur Identifizierung zusammenhängender Nachrichten, die die Daten derselben GNSS-Ortung enthalten und somit zum selben Zyklus gehören. D.h. Daten in den Nachrichten wurden zur selben Zeit erzeugt. Der";
CM_ SG_ 888 GNSS_Ortung_Hoehe "Höhe über dem Meeresspiegel";
CM_ SG_ 888 GNSS_Ortung_Zeit_in_GPSWoche "Zeitstempel für die Jitter-Prüfung aso. Zeit muss sychron zur Zeit der GNSS-Ortung sein.";

CM_ SG_ 891 GNSS_Empfaenger_Status "Im 'Backup Mode' wird z.B. die UTC Zeit durch eine gepufferte 'Realtime Clock' bereitgestellt.
Im 'Live Mode' wird die UTC Zeit durch das GNSS Modul bereitgestellt. ";
CM_ SG_ 891 GNSS_Empfangbare_Satelliten "Anzahl der Satelliten, welche bei der aktuellen Satellitenkonfiguration ptentiell verfügbar sind";
CM_ SG_ 891 GNSS_Genutzte_Satelliten "Anzahl der Satelliten, welche für die aktuelle Ortung verwendet werden";
CM_ SG_ 891 GNSS_GLONASS_in_Nutzung "1: das genannte GNSS wurde für die Ortung verwendet";
CM_ SG_ 891 GNSS_GPS_in_Nutzung "1: das genannte GNSS wurde für die Ortung verwendet";
CM_ SG_ 891 GNSS_Nachrichtenpaket_ID5 "+1 für jedes neue Paket. Zyklische ID-Vergabe (Zähler). Zur Identifizierung zusammenhängender Nachrichten, die die Daten derselben GNSS-Ortung enthalten und somit zum selben Zyklus gehören. D.h. Daten in den Nachrichten wurden zur selben Zeit erzeugt. Der";
CM_ SG_ 891 GNSS_Sichtbare_Satelliten "Anzahl der Satelliten, welche aktuell empfangen werden";
CM_ SG_ 891 GNSS_UTC_Zeit "UTC-Zeit, Sekunden seit dem 01.01.1970 00:00";

CM_ SG_ 1364 GNSS_Nachrichtenpaket_ID6 "+1 für jedes neue Paket. Zyklische ID-Vergabe (Zähler). Zur Identifizierung zusammenhängender Nachrichten, die die Daten derselben GNSS-Ortung enthalten und somit zum selben Zyklus gehören. D.h. Daten in den Nachrichten wurden zur selben Zeit erzeugt. Der";
CM_ SG_ 1364 GNSS_Sat_Info_Azimuth_ID_1 "Azimut des Satelliten";
CM_ SG_ 1364 GNSS_Sat_Info_Hoehenwinkel_ID_1 "Höhenwinkel des Satelliten";
CM_ SG_ 1364 GNSS_Sat_Info_Sat_ID_1 "ID des Satelliten";
CM_ SG_ 1364 GNSS_Sat_Info_SNR_ID_1 "Signal-Rausch-Verhältnis des Satelliten";

CM_ SG_ 299 GRA_Abbrechen "GRA : aus mit speichern
ACC : Soft aus";
CM_ SG_ 299 GRA_ACC_01_BZ "4bit Botschaftszaehler, wird mit jeder Sendebotschaft inkrementiert
Botschaft asynchron geroutet. Zählerwert kann springen.";
CM_ SG_ 299 GRA_ACC_01_CRC "Für MLB:
'Berechnung siehe Lastenheft 'Kommunikationsabsicherung für FlexRay und CAN''

Ab MQB und MLBevo:
'Berechnung siehe Lastenheft 'End-to-End Kommunikationsabsicherung''

Endwerte siehe Begleitdokument 'S-PDU Kennungsfolgen'";
CM_ SG_ 299 GRA_Codierung "Das Signal zeigt an, ob das Sende-SG (SMLS/MFL) auf GRA- oder ACC-Bedienteil codiert ist:
0: kein GRA- oder ACC Bedienteil
1: GRA-Bedienteil
2: ACC-Bedienteil
3: Limiter_Only-Bedienteil";
CM_ SG_ 299 GRA_Fehler "Das Signal zeigt an, dass das Sende-SG (SMLS/MFG) einen Defekt des GRA-Bedienteils erkannt hat und hierzu ein FSPE abgelegt wurde.";
CM_ SG_ 299 GRA_Hauptschalter "Stellung des GRA/ACC-Hauptschalters: 
Bei gerastetem Hauptschalter:
0: Hauptschalter aus
1: Hauptschalter ein
Bei getastetem Hauptschalter:
0: Taster nicht betätigt
1: Taster betätigt";
CM_ SG_ 299 GRA_LIM_Taste_verfuegbar "Das Signal zeigt an, ob eine Limiter-Umschalttaste am jeweiligen GRA/ACC-Bedienelement vorhanden ist.";
CM_ SG_ 299 GRA_Limiter "Stellung des Limiter-Tasters";
CM_ SG_ 299 GRA_reserveByte4 "Zweck: Befüllen der reservierten Bitpositionen mit 0 (wg. LIN-Teilnehmer MFL)";
CM_ SG_ 299 GRA_reserveByte5 "Zweck: Befüllen der reservierten Bitpositionen mit 0 (wg. LIN-Teilnehmer MFL)";
CM_ SG_ 299 GRA_reserveByte6 "Zweck: Befüllen der reservierten Bitpositionen mit 0 (wg. LIN-Teilnehmer MFL)";
CM_ SG_ 299 GRA_reserveByte7 "Zweck: Befüllen der reservierten Bitpositionen mit 0 (wg. LIN-Teilnehmer MFL)";
CM_ SG_ 299 GRA_reserveByte8 "Zweck: Befüllen der reservierten Bitpositionen mit 0 (wg. LIN-Teilnehmer MFL)";
CM_ SG_ 299 GRA_Tip_Hoch "Tippschalter Tip Up / Geschwindigkeit erhöhen";
CM_ SG_ 299 GRA_Tip_Runter "Tippschalter Tip Down / Geschwindigkeit reduzieren";
CM_ SG_ 299 GRA_Tip_Setzen "Tippschalter Set";
CM_ SG_ 299 GRA_Tip_Stufe_2 "Signal zeigt an, dass der zweistufige GRA/ACC-Hebel (8_Positions_Bedienteil) in der 2. Tip-Stufe betätigt wird. Das Signal wird nur gleichzeitig mit dem Signal GRA_Tip_Hoch oder GRA_Tip_Runter gesetzt, wobei die Bits GRA_Tip_Hoch bzw. GRA_Tip_Runter die R";
CM_ SG_ 299 GRA_Tip_Wiederaufnahme "Tippschalter Wiederaufnahme";
CM_ SG_ 299 GRA_TravelAssist "Taste für TravelAssist";
CM_ SG_ 299 GRA_Typ_Bedienteil "Das Signal kennzeichnet die Variante des GRA/ACC-Bedienteils:
0: Init
1: 4-Positionen-Bedienteil (z.B. GRA im Blinkerhebel)
2: 6-Positionen-Bedienteil (GRA/ACC-Bedienteil mit separaten Stellungen für Set/Resume/TipUp/TipDown) 
3: 8-Positionen-Bediente";
CM_ SG_ 299 GRA_Typ_Hauptschalter "Variante des GRA/ACC-Hauptschalters:
0: gerasteter Hauptschalter (bzw. Taster mit Speicherung des Status im SMLS (PAG))
1: getasteter Hauptschalter, keine Speicherung des Status im SMLS";
CM_ SG_ 299 GRA_Verstellung_Zeitluecke "Verstellung der Zeitlücke für ACC

DIST -1 = Zeitluecke um 1 Stufe kleiner
DIST +1 = Zeitluecke um 1 Stufe groeßer
DIST Toggle = Zeitlücke um 1 Stufe kleiner, von kleinster Stufe auf größte Stufe";

CM_ SG_ 310 HAL_01_BZ "Botschaft asynchron geroutet. Zählerwert kann springen.";
CM_ SG_ 310 HAL_01_CRC "Für MLB:
'Berechnung siehe Lastenheft 'Kommunikationsabsicherung für FlexRay und CAN''

Ab MQB und MLBevo:
'Berechnung siehe Lastenheft 'End-to-End Kommunikationsabsicherung''

Endwerte siehe Begleitdokument 'S-PDU Kennungsfolgen'
";
CM_ SG_ 310 HAL_Charisma_FahrPr "MLBevo: Aktuelles Fahrprogramm des Charisma-Teilnehmers (siehe Systemlastenheft Drive Select)
MQB: Istwert der Kennlinie (siehe Systemlastenheft MQB FPA)";
CM_ SG_ 310 HAL_Charisma_Status "Rückmeldung an den Charisma-Master";
CM_ SG_ 310 HAL_EFP_FahrPr "Aktueller Ist-Zustand der HAL";
CM_ SG_ 310 HAL_Fahrerwunschwinkel_Soll "Zielwinkel (=Fahrerwunschwinkel) am Rad Hinterachslenkung in Grad";
CM_ SG_ 310 HAL_max_Gradient "maximaler Zustellgradient für die Stabilisierungsfunktion mit HAL durch ESP";
CM_ SG_ 310 HAL_QBit_Radwinkel "Wenn Bit gesetzt, dann entspreicht das Signal nicht mehr ASIL-D. (z.B. Ausfall der redundanten Sensorik)";
CM_ SG_ 310 HAL_Radwinkel "Zusätzlich durch die HAL gestellter Radwinkeloffset an der Hinterachse in Grad";
CM_ SG_ 310 HAL_Status "Status der Hinterachslenkung
0: normaler Betrieb 
1: HAL verriegelt (z.B. harter Fehler, nicht kalibriert)
2: Rücknahme der Leistung, Funktion eingeschränkt/Derating aktiv 
3: HAL deaktiviert";
CM_ SG_ 310 HAL_Status_2 "Zustand der Hinterachlenkung in der Smart application";
CM_ SG_ 310 HAL_VZ_Fahrerwunschwinkel_Soll "Soll-Lenkrichtung der HAL";
CM_ SG_ 310 HAL_VZ_Radwinkel "Lenkrichtung der HAL";
CM_ SG_ 310 HAL_Warnungen "Warnmeldungsanforderung von der Hinterachslenkung an das Kombiinstrumnent";
CM_ SG_ 310 HAL_Winkelbegrenzung "Signal liefert die Info über eine aktive Winkelbegrenzung in der HAL aufgrund Bauteilschutz";

CM_ SG_ 1410 HD_Bewegung_auf "Bewegung HD (öffnen)";
CM_ SG_ 1410 HD_Bewegung_zu "Bewegung HD (schließen)";
CM_ SG_ 1410 HD_Endstellung_oben "obere Endstellung HD
";
CM_ SG_ 1410 HD_Endstellung_unten "untere Endstellung HD";
CM_ SG_ 1410 HD_Innentaster_betaetigt "Betätigung Innentaster HD
";
CM_ SG_ 1410 HD_Position "HD Position von 0 bis 100 %";
CM_ SG_ 1410 HD_Rueckmeld_prog "Programmierung Endstellung HD 
";
CM_ SG_ 1410 HD_Taster_defekt "Anzeige ob Heckdeckeltaster defekt ist";
CM_ SG_ 1410 HD_UeKB_erkannt "Erkennung Einklemmschutz";
CM_ SG_ 1410 HD_Verr_Taster_betaetigt_inv "Inverses Bit (Fusi-Anforderung) Betätigung des Verriegelungstaster für Heckdeckel";
CM_ SG_ 1410 HD_Verriegelungstaster_betaetigt "Betätigung des Verriegelungstaster für Heckdeckel";
CM_ SG_ 1410 HD_ZZH_Schalter_S3 "Teilt den Zustand des Statusschalters in einer unidirektionalen ZZH mit.";

CM_ SG_ 1416 BCM1_TCH_HLR_Anf "Kundenanforderung des Thermocupholders zum Heizen-/Kühlen";
CM_ SG_ 1416 FSH_LED "LED Ansteuerung Frontscheibenheizung";
CM_ SG_ 1416 HLR_SIH_Freigabe_Fond "Freigabe des EM für Sitzheizungen hinten";
CM_ SG_ 1416 HSH_LED "LED Ansteuerung Heckscheibenheizung";
CM_ SG_ 1416 KRH_Stufe_LED_li "Statusmeldung Kopfraumheizung links";
CM_ SG_ 1416 KRH_Stufe_LED_re "Statusmeldung Kopfraumheizung rechts";
CM_ SG_ 1416 SIH_Stufe_LED_HL "Statusmeldung Sitzheizung hinten links";
CM_ SG_ 1416 SIH_Stufe_LED_HR "Statusmeldung Sitzheizung hinten rechts";
CM_ SG_ 1416 SIH_Stufe_LED_li "Statusmeldung Sitzheizung links";
CM_ SG_ 1416 SIH_Stufe_LED_re "Statusmeldung Sitzheizung rechts";
CM_ SG_ 1416 SIL_Stufe_LED_HL "Statusmeldung Sitzlüftung hinten links";
CM_ SG_ 1416 SIL_Stufe_LED_HR "Statusmeldung Sitzlüftung hinten rechts";
CM_ SG_ 1416 SIL_Stufe_LED_li "Statusmeldung Sitzlüftung links";
CM_ SG_ 1416 SIL_Stufe_LED_re "Statusmeldung Sitzlüftung rechts";

CM_ SG_ 1016 HLR_FlHz_Freigabe_HL "Freigabe des NVEM für die Flächenheizung hinten links";
CM_ SG_ 1016 HLR_FlHz_Freigabe_HR "Freigabe des NVEM für die Flächenheizung hinten rechts";
CM_ SG_ 1016 HLR_FlHz_Freigabe_Ruhesitz "Freigabe des NVEM für die Flächenheizung des Ruhesitzes";
CM_ SG_ 1016 HLR_FlHz_Freigabe_VL "Freigabe des NVEM für die Flächenheizung vorne links";
CM_ SG_ 1016 HLR_FlHz_Freigabe_VR "Freigabe des NVEM für die Flächenheizung vorne rechts";
CM_ SG_ 1016 HLR_FSH_Freigabe "Freigabe des EEM für die Frontscheibenheizung";
CM_ SG_ 1016 HLR_HSH_Freigabe "Freigabe des EEM für die Heckscheibenheizung";
CM_ SG_ 1016 HLR_KRH_Freigabe_VL "Freigabe des EEM für die Kopfraumheizung vorne links";
CM_ SG_ 1016 HLR_KRH_Freigabe_VR "Freigabe des EEM für die Kopfraumheizung vorne rechts";
CM_ SG_ 1016 HLR_LRH_Freigabe "Freigabe für die Lenkradheizung";
CM_ SG_ 1016 HLR_PTC_Freigabe "Freigabe des elektrischen Energiemanagements für das gestufte/geregelte PTC";
CM_ SG_ 1016 HLR_PTC_linear_Freigabe "Freigabe des EEM für den linearen PTC-Zuheizer";
CM_ SG_ 1016 HLR_SIH_Freigabe_Fond "Freigabe des EM für Sitzheizungen hinten";
CM_ SG_ 1016 HLR_SIH_Freigabe_HL "Freigabe des EEM für die Sitzheizung hinten links";
CM_ SG_ 1016 HLR_SIH_Freigabe_HR "Freigabe des EEM für die Sitzheizung hinten rechts";
CM_ SG_ 1016 HLR_SIH_Freigabe_VL "Freigabe des EEM für die Sitzheizung vorne links";
CM_ SG_ 1016 HLR_SIH_Freigabe_VR "Freigabe des EEM für die Sitzheizung vorne rechts";
CM_ SG_ 1016 HLR_SIL_Freigabe_HL "Freigabe des EEM für die Sitzbelüftung hinten links";
CM_ SG_ 1016 HLR_SIL_Freigabe_HR "Freigabe des EEM für die Sitzlüftung hinten rechts";
CM_ SG_ 1016 HLR_SIL_Freigabe_VL "Freigabe des EEM für die Sitzlüftung Vorne Links";
CM_ SG_ 1016 HLR_SIL_Freigabe_VR "Freigabe des EEM für die Sitzlüftung vorne Rechts";
CM_ SG_ 1016 HLR_Sp_Heizung_Freigabe_BT "Freigabe der Außenspiegelheizung Beifahrerseite";
CM_ SG_ 1016 HLR_Sp_Heizung_Freigabe_FT "Freigabe des EEM für die Außenspiegelheizung rechtsFreigabe der Außenspiegelheizung Fahrerseite";
CM_ SG_ 1016 HLR_TCH_Freigabe "Freigabe des NVEM für den Thermocupholder";

CM_ SG_ 1412 HSP_01_CRC "CRC8-Checksumme über alle Datenbytes der Botschaft HSPs_01

 Für MLB:
 'Berechnung siehe Lastenheft 'Kommunikationsabsicherung für Flexray und CAN''

 Ab MQB und MLBevo:
 'Berechnung siehe Lastenheft 'End-to-End Kommunikationsabsicherung'

 Endwer";
CM_ SG_ 1412 HSP_BAP_Messages "Statusinformationen für BAP Kommunikation.";
CM_ SG_ 1412 HSP_Charisma_FahrPr "MLBevo: Aktuelles Fahrprogramm des Charisma-Teilnehmers (siehe Systemlastenheft Drive Select)
MQB: Istwert der Kennlinie (siehe Systemlastenheft MQB FPA)";
CM_ SG_ 1412 HSP_Charisma_Status "Rückmeldung an den Charisma-Master

Wert 0x3 ist nur für Fahrzeuge ab MQB relevant";
CM_ SG_ 1412 HSP_def "Spoilersteuergerät defekt";
CM_ SG_ 1412 HSP_Endlage_ausgefahren "Spoiler in Endlage ausgefahren";
CM_ SG_ 1412 HSP_Endlage_eingefahren "Spoiler in Endlage eingefahren";
CM_ SG_ 1412 HSP_Komponentensteuerung "Ansteuerart des HSP";
CM_ SG_ 1412 HSP_LED_Error "Spoiler meldet LED-Fehler";
CM_ SG_ 1412 HSP_man_Betaet_nicht_zulaessig "Manuelle Betätigung des Spoilers nicht zulässig.";
CM_ SG_ 1412 HSP_Motor_def "elektr. Fehler im Spoilermotor";
CM_ SG_ 1412 HSP_Motor_Temp_Text "Kombimeldung für Systemverfügbarkeit";
CM_ SG_ 1412 HSP_ResponseError "siehe LIN2.0-Specification
(Darf nicht über ein Fehlergueltigkeitsbit abgesichtert werden!)";
CM_ SG_ 1412 HSP_Taster_Error "Spoiler meldet Tasterfehler";
CM_ SG_ 1412 HSP_Warnung_LED "Kombi Warnung LED Spoiler";
CM_ SG_ 1412 HSP_Warnung_Text "Kombi Warnung Text Spoiler";
CM_ SG_ 1412 HSP_Warnung_Ton "Kombi Warnung Ton Spoiler";

CM_ SG_ 1283 HV_Bordnetz_aktiv "Signalisiert ein aktives Hochvoltbordnetz. Für die Belastbarkeit des HV-Netzes müssen Strom- bzw. Leistungsgrenzen eingehalten werden";
CM_ SG_ 1283 HV_Bordnetz_Fehler "Status ob im  HV-Netz ein Fehler detektiert wurde.";
CM_ SG_ 1283 HVK_01_CRC "Für MLB:
'Berechnung siehe Lastenheft 'Kommunikationsabsicherung für FlexRay und CAN''

Ab MQB und MLBevo:
'Berechnung siehe Lastenheft 'End-to-End Kommunikationsabsicherung''

Endwerte siehe Begleitdokument 'S-PDU Kennungsfolgen'";
CM_ SG_ 1283 HVK_AIAD_Sollmodus_2 "Freigabe für die HV-Netz Teilnahme";
CM_ SG_ 1283 HVK_AktiveEntladung_Anf "Anforderung zum aktiven Entladen des HV-Netzes, während der Abschaltung des HV-Netz.";
CM_ SG_ 1283 HVK_BMS_Sollmodus "Angeforderter Sollmodus der HV-Batterie:
0 : HV_Off                                
1 : HV_On (HS geschlossen)                
2 : nicht belegbar                        
3 : AC-Laden_erw (HS +AC_2-Schütze geschlossen)                         
4 : AC-";
CM_ SG_ 1283 HVK_DCDC_EKK_Sollmodus "Bedarfsgerechtes Aktivieren des 400V-DCDC-Wandlers bei Anforderung durch TME";
CM_ SG_ 1283 HVK_DCDC_Sollmodus "angeforderte Soll-Betriebsart des DC/DC-Wandlers: 
0: Standby; Kommunikation aktiv
1: Zwischenkreis des HV-Netzes wird vorgeladen; HV-Netz wird aktiviert und darf nicht  
    belastet werden.
2: Tiefsetzen (HV --> BN 14,4V)
    Sollwertvorgabe projek";
CM_ SG_ 1283 HVK_EKK_Sollmodus "Sollmodus elektrischer Klimakompressor";
CM_ SG_ 1283 HVK_Gesamtst_Spgfreiheit "Status des HV-Systems";
CM_ SG_ 1283 HVK_HV_Netz_Warnungen "Anforderung Warnung/Fehler HV-System im Kombi
0: Keine Warnung/Init
1:Anforderung_Anzeige_Warnung_HV-Netz (gelbes Symbol)
2:Anforderung_Anzeige_Fehler_HV-Netz (rotes Symbol)
3:Anforderung_Anzeige_Warnung_Kein_Wiederstart_möglich";
CM_ SG_ 1283 HVK_HVLM_Sollmodus "Angeforderter Sollmodus des Lademanagers.";
CM_ SG_ 1283 HVK_HVPTC_Sollmodus "Sollmodus HV-PTC
0 : keine Freigabe
1 : Freigabe
2 : Freigabe_ausgesetzt
3 : nicht belegbar
4 : nicht belegbar
5 : nicht belegbar
6 : nicht belegbar
7 : Init   (CAN-Initialisierung)   

Info: 'nicht belegbar' d.h. Sollmodus nicht relevant für HV";
CM_ SG_ 1283 HVK_Iso_Messung_Start "Anforderung an die isolationswiderstandsüberwachenden HV-Komponenten zur Durchführung der Isolations-Widerstandsmessung.";
CM_ SG_ 1283 HVK_Istmodus_Anf "HVK-Anforderung an alle HV-Komponenten deren Istmodus im schnellen Zyklus (Inhibitzeit) zu senden.";
CM_ SG_ 1283 HVK_MO_EmSollzustand "Anforderung vom HVK Sollzustand der Elm_State
0 = HvOff              
1 = HvStbyReq          
2 = HvStbyWait         
3 = HvBattOnReq        
4 = HvBattOnWait       
10 = HvOnIdle          
18 = HvOnDrvReq        
19 = HvOnDrvWait       
20 = HvO";
CM_ SG_ 1283 HVK_TN1_Sollmodus "Angeforderter Sollmodus der Steuereinheit für das Schütze des Teilnetz1 'Ladepfad':
0 : HV_Off                                
1 : HV_On (Schütz geschlossen)                
2 : reserviert
3 : Init   (CAN-Initialisierung)";

CM_ SG_ 1340 HVLM_04_BZ "Fortlaufender Botschaftszaehler";
CM_ SG_ 1340 HVLM_04_CRC "Für MLB:
'Berechnung siehe Lastenheft 'Kommunikationsabsicherung für FlexRay und CAN''

Ab MQB und MLBevo:
'Berechnung siehe Lastenheft 'End-to-End Kommunikationsabsicherung''

Endwerte siehe Begleitdokument 'S-PDU Kennungsfolgen'";
CM_ SG_ 1340 HVLM_Anf_Ladescreen "Anforderung für Ladescreen (BEV)";
CM_ SG_ 1340 HVLM_Anforderung_HMS "Anforderung zur Verriegelung des Triebstrangs";
CM_ SG_ 1340 HVLM_AWC_Sollmodus "Sollmodus AWC Ladegerät";
CM_ SG_ 1340 HVLM_Fehlerstatus "aktueller Fehlerstatus des Ladegerätes
";
CM_ SG_ 1340 HVLM_HV_Anf "HV-Aktivierung Anforderung und Grund der Anforderung";
CM_ SG_ 1340 HVLM_HVEM_MaxLeistung "Maximal zulässige Leistung, die das HVEM vom Lader nutzen darf. Wenn das Fzg nicht über einen Lader mit dem AC Netz verbunden ist ist dieser Wert 0.";
CM_ SG_ 1340 HVLM_IstModus_02 "aktueller Modus";
CM_ SG_ 1340 HVLM_LadeAnforderung "Mitteilung des Lademanagements an das MSG ob Stecker erkannt wurde, Laden gestartet, ein autonomer Betriebszustand aktiviert, eine Relaxing Phase für die Batterie angefordert werden soll";
CM_ SG_ 1340 HVLM_Ladeart "Anzeige, ob Strom in das Fzg. fließt und wofür er verwendet wird.";
CM_ SG_ 1340 HVLM_MaxBatLadestromHV "Empfohlener HV Batterieladestrom bei einer geplanten Ladung";
CM_ SG_ 1340 HVLM_Parken_beibehalten_HMS "Anforderung den Triebstrang verriegelt zu halten";
CM_ SG_ 1340 HVLM_Standklima_Timer_Status "Signalisierung an das KBT ob mind. ein Timer zur Standklimatisierung programmiert ist";
CM_ SG_ 1340 HVLM_Status_Netz "Information, ob das Fahrzeug mit einem Stromnetz verbunden ist.";
CM_ SG_ 1340 HVLM_Status_Tankklappe "Signal zeigt aktuellen Status der Tankklappe für FuelCellUnit an.";
CM_ SG_ 1340 HVLM_Stecker_Status "Status der Steckererkennung unabhängig vom Lademodus (AC oder DC)";
CM_ SG_ 1340 HVLM_STH_Betriebsmodus "Betriebsmodus der Standheizung für Vorkonditionierung und Timerklimatisierung";
CM_ SG_ 1340 HVLM_VK_Modus "Übermittlung des aktuellen Konditionierungs-Status für HMI, Mobile Online Dienste";
CM_ SG_ 1340 HVLM_VK_STH_Einsatz "Auswahl der PHEV Standheizung";

CM_ SG_ 1524 AMB_Charisma_FahrPr "MLBevo: Aktuelles Fahrprogramm des Charisma-Teilnehmers (siehe Systemlastenheft Drive Select)
MQB: Istwert der Kennlinie (siehe Systemlastenheft MQB FPA)";
CM_ SG_ 1524 AMB_Charisma_Status "Systemstatus des Charismateilnehmers

Wert 0x3 ist nur für Fahrzeuge ab MQB relevant";
CM_ SG_ 1524 BCM1_DI_Rampe_Innenlicht "Dimmrampe Innenlicht";
CM_ SG_ 1524 BCM1_DI_Rampe_Leselicht "Dimmrampe Leselicht";
CM_ SG_ 1524 BCM1_Innenlicht_gedimmt_H "Steuerung von BCM_Innenlicht_H";
CM_ SG_ 1524 BCM1_Innenlicht_gedimmt_V "Steuerung von BCM_Innenlicht_V";
CM_ SG_ 1524 BCM1_Innenlicht_H "Anforderung Innenlicht hinten";
CM_ SG_ 1524 BCM1_Innenlicht_V "Anforderung Innenlicht vorne";
CM_ SG_ 1524 BCM1_Leselicht_Anf_hl " Leselicht hinten links Anforderung";
CM_ SG_ 1524 BCM1_Leselicht_Anf_hr "Leselicht hinten rechts Anforderung";
CM_ SG_ 1524 BCM1_Leselicht_Anf_vl "Leselicht vorne links Anforderung";
CM_ SG_ 1524 BCM1_Leselicht_Anf_vr "Leselicht vorne rechts Anforderung";
CM_ SG_ 1524 BCM1_Leuchten_Aus "Innenbeleuchtung ausschalten (keine Änderung / ausschalten)";
CM_ SG_ 1524 IL_Bel_BFS_Ausstieg "Einschalten der Ausstiegsleuchten oder Türwarnleuchten in Tür oder im Schweller";
CM_ SG_ 1524 IL_Bel_FS_Ausstieg "Einschalten der Ausstiegsleuchten oder Türwarnleuchten in Tür oder im Schweller";
CM_ SG_ 1524 IL_Bel_HBFS_Ausstieg "Einschalten der Ausstiegsleuchten oder Türwarnleuchten in Tür oder im Schweller";
CM_ SG_ 1524 IL_Bel_HFS_Ausstieg "Einschalten der Ausstiegsleuchten oder Türwarnleuchten in Tür oder im Schweller";
CM_ SG_ 1524 IL_Dimmung_H_Tuerkontur "Dimmung Türkontur hinten (bei Änderung im 30 ms Raster)";
CM_ SG_ 1524 IL_Dimmung_Lautspr "Dimmung Umfeldbeleuchtung an Türaußenseite oder Außenspiegel";
CM_ SG_ 1524 IL_Dimmung_Tuerinnengriff "Dimmung Türinnengriff";
CM_ SG_ 1524 IL_Dimmung_Umfeldbel "Dimmung Umfeldbeleuchtung an Türaußenseite oder Außenspiegel";
CM_ SG_ 1524 IL_Dimmung_V_Tuerkontur "Dimmung Türkontur vorne (bei Änderung im 30 ms Raster)";
CM_ SG_ 1524 IL_Innenlicht_aktiv "Status Innenlicht";
CM_ SG_ 1524 IL_Klemme_30G_aktiv "Synchrones Abschalten";

CM_ SG_ 312 IPA_01_BZ "Fehlende Beschreibung (Import)
Botschaft asynchron geroutet. Zählerwert kann springen.";
CM_ SG_ 312 IPA_01_CRC "Für MLB:
'Berechnung siehe Lastenheft 'Kommunikationsabsicherung für FlexRay und CAN''

Ab MQB und MLBevo:
'Berechnung siehe Lastenheft 'End-to-End Kommunikationsabsicherung''

Endwerte siehe Begleitdokument 'S-PDU Kennungsfolgen'";
CM_ SG_ 312 IPA_Anforderung_HMS "Anforderung vom IPA (Intelligent Park Assist) an das HMS (Haltemanagement System)";
CM_ SG_ 312 IPA_APS_LED "Ansteuerung der APS Funktions-LED durch das BCM.
0 = LED aus
1 = LED ein
2 = LED blinken
3 = Funktion gesperrt, LED aus
4 = frei
5 = frei
6 = Init
7 = frei";
CM_ SG_ 312 IPA_Fahrstufenwunsch "Flankengesteuerter Fahrstufenwunsch von IPA/PiloPa an das Getriebe";
CM_ SG_ 312 IPA_Parken_beibehalten_HMS "Anforderung seitens Pilotiertem Parken bzw. Manövrierassistent das Lösen der EPB bzw. das Auslegen der Parksperre zu blockieren";
CM_ SG_ 312 IPA_PLA_LED "Ansteuerung der PLA Funktions-LED durch das BCM.
0 = LED aus
1 = LED ein
2 = LED blinken
3 = Funktion gesperrt, LED aus
4 = frei
5 = frei
6 = Init
7 = frei";
CM_ SG_ 312 IPA_Sollbeschleunigung "Anforderung vom IPA an den TSK, das Fahrzeug zu beschleunigen.";
CM_ SG_ 312 IPA_Status "Zustand der IPA-Statusmaschine";
CM_ SG_ 312 IPA_Status_IPA_GE "Statusinformation von IPA/PiloPa für Handshakemechanismus mit dem Getriebe-SG";
CM_ SG_ 312 IPA_Status_IPA_TSK "Statusinformation vom IPA für Handshakemechanismus mit TSK";
CM_ SG_ 312 Parken_aktives_System "Das Signal zeigt an, welches der Parksysteme auf dem zFAS gerade aktiv ist.";
CM_ SG_ 312 Parken_erhoehtes_Moment "Anforderung einer spezifizierten Motormomenten-Rampe seitens IPA/PiloPa für das Überfahren einer Schwelle oder eines Bordsteins.";
CM_ SG_ 312 Parken_Fahrbereitschaft_Anf "Anforderung seitens iPA/pilotiertes Parken, die Fahrbereitschaft aufrecht zu erhalten und das Verlassenskonzept im MSG beim „automatischen Parkvorgang“ zu deaktivieren.";
CM_ SG_ 312 Parken_Motorlauf_Anf "Anforderung Motorlauf seitens PiloPa";

CM_ SG_ 2527679583 Parken_Aktivierungslicht_Anf "Anforderung des Aktivierungslichts nach erfolgreicher Aktivierungshandlung seitens Pilotiertem Parken.";
CM_ SG_ 2527679583 Parken_Bestaetigungsblinken_Anf "Anforderung seitens Pilotiertem Parken für ein Erfolgsblinken nach dem Erreichen der Zielposition bzw. für ein Abbruchsblinken bei Eintreten einer Abbruchsbedingung.";
CM_ SG_ 2527679583 Parken_Fahrbereitschaftlicht_Anf "Anforderung des Fahrbereitschaftslichts";
CM_ SG_ 2527679583 Parken_Fahrerhinweise_Anf "Anforderung zur erneuten Lampenaufprüfung und Anzeige von Warnhinweisen nach einem pilotierten Ausparkvorgang.";
CM_ SG_ 2527679583 Parken_Fahrtrichtungslicht_Anf "Anforderung seitens Pilotiertem Parken für die Anzeige der initialen Fahrtrichtung nach Systemaktivierung.";
CM_ SG_ 2527679583 Parken_FFB_LED_Anf "Statusinformation des Pilotierten Parkens für die Ansteuerung der LED auf der Funkfernbedienung.";
CM_ SG_ 2527679583 Parken_Lichtnachlauf_Anf "Anforderung des Lichtnachlaufs beim BCM1 (analog Verlassenskonzept) für das Pilotierte Parken. ";
CM_ SG_ 2527679583 Parken_Schluesselsuche_Anf "Ansteuerung der Schlüsselsuche für das pilotierte Parken.";
CM_ SG_ 2527679583 Parken_Seitenspiegel_Anf "Anforderung für Seitenspiegel an- oder abklappen beim PiloPa";
CM_ SG_ 2527679583 Parken_Wegfahrsperren_Anf "Ansteuerung der Wegfahrsperren Komponenten für das pilotierte Parken.  ";
CM_ SG_ 2527679583 Parken_ZR_Sondermodus_Anf "Anforderung Sondermodus, um beim „pilotierten Parken“ spezielle Funktionsanpassungen im Infotainment-Bereich zu ermöglichen (u.a. schnellerer Startup, Abschaltung BT)";
CM_ SG_ 2527679583 Parken_ZV_Schliessen "Anforderung für Zentralverriegelung verriegeln oder safen beim PiloPa";

CM_ SG_ 1903 ISO_AMP_Req_Data "OffBoard Tester Diagnose Request AMP";

CM_ SG_ 1792 ISO_ALL_01_Req_Data "Funktionaler Request ALL";
BA_DEF_REL_ BU_SG_REL_  "GenSigTimeoutTime" INT 0 65535;
BA_DEF_ BO_  "DiagRequest" ENUM "No", "Yes";
BA_DEF_ BO_  "DiagResponse" ENUM "No", "Yes";
BA_DEF_ BO_  "DiagState" ENUM "No", "Yes";
BA_DEF_ BO_  "GenMsgChkConstant" HEX 0 4095;
BA_DEF_ BO_  "GenMsgCycleTime" INT 0 65535;
BA_DEF_ BO_  "GenMsgCycleTimeFast" INT 0 65535;
BA_DEF_ BO_  "GenMsgDelayTime" INT 0 100000;
BA_DEF_ BO_  "GenMsgILSupport" ENUM "No", "Yes";
BA_DEF_ BO_  "GenMsgNrOfRepetition" INT 0 100;
BA_DEF_ BO_  "GenMsgPDUConstants" STRING;
BA_DEF_ BO_  "GenMsgSendType" ENUM "Cyclic", "not_used", "not_used", "not_used", "not_used", "not_used", "not_used", "IfActive", "NoMsgSendType";
BA_DEF_ BO_  "GenMsgStartDelayTime" INT 0 100000;
BA_DEF_ BO_  "NmMessage" ENUM "No", "Yes";
BA_DEF_ BO_  "NmhMessage" ENUM "No", "Yes";
BA_DEF_ BO_  "MsgType" ENUM "Application", "NM ", "NMH", "TP2.0", "ISO-TP ", "BAP", "EID", "KS", "XCP_PRE_CONFIGURED", "XCP_RUNTIME_CONFIGURED";
BA_DEF_ BO_  "VAGTP20_API" HEX 0 255;
BA_DEF_ BO_  "VAGTP20_DynConnection" ENUM "No", "Yes";
BA_DEF_ BO_  "VAGTP20_DynSetup" ENUM "No", "Yes";
BA_DEF_ BO_  "VAGTP20_StatConnection" ENUM "No", "Yes";
BA_DEF_ SG_  "GenSigActiveRepetitions" INT -2147483648 2147483647;
BA_DEF_ SG_  "GenSigInactiveValue" INT -2147483648 2147483647;
BA_DEF_ SG_  "GenSigSendType" ENUM "Cyclic", "OnWrite", "OnWriteWithRepetition", "OnChange", "OnChangeWithRepetition", "IfActive", "IfActiveWithRepetition", "NoSigSendType", "OnChangeAndIfActive", "OnChangeAndIfActiveWithRepetition";
BA_DEF_ SG_  "GenSigStartValue" INT -2147483648 2147483647;
BA_DEF_ SG_  "NWM-WakeupAllowed" ENUM "No", "Yes";
BA_DEF_ SG_  "GenSigFuncType" ENUM "NoFunction", "MsgCounter", "CRC-8", "XOR", "XOR-2", "DatedBit", "SW-Kl15", "CHK", "Constant", "Protocol", "CRC-8-SAE_J1850", "CRC-32", "DataLength", "DataID", "MsgCounter16", "SOK-Signatur", "Cluster";
BA_DEF_ SG_  "GenSigSwitchedByIgnition" ENUM "No", "Yes";
BA_DEF_ SG_  "Fehlerwert" HEX 0 2147483647;
BA_DEF_ SG_  "GenSigMissingSourceValue" HEX 0 2147483647;
BA_DEF_DEF_REL_  "GenSigTimeoutTime" 0;
BA_DEF_DEF_  "DiagRequest" "No";
BA_DEF_DEF_  "DiagResponse" "No";
BA_DEF_DEF_  "DiagState" "No";
BA_DEF_DEF_  "GenMsgChkConstant" 0;
BA_DEF_DEF_  "GenMsgCycleTime" 0;
BA_DEF_DEF_  "GenMsgCycleTimeFast" 0;
BA_DEF_DEF_  "GenMsgDelayTime" 0;
BA_DEF_DEF_  "GenMsgILSupport" "No";
BA_DEF_DEF_  "GenMsgNrOfRepetition" 0;
BA_DEF_DEF_  "GenMsgPDUConstants" "";
BA_DEF_DEF_  "GenMsgSendType" "NoMsgSendType";
BA_DEF_DEF_  "GenMsgStartDelayTime" 0;
BA_DEF_DEF_  "NmMessage" "No";
BA_DEF_DEF_  "NmhMessage" "No";
BA_DEF_DEF_  "MsgType" "Application";
BA_DEF_DEF_  "VAGTP20_API" 0;
BA_DEF_DEF_  "VAGTP20_DynConnection" "No";
BA_DEF_DEF_  "VAGTP20_DynSetup" "No";
BA_DEF_DEF_  "VAGTP20_StatConnection" "No";
BA_DEF_DEF_  "GenSigActiveRepetitions" 0;
BA_DEF_DEF_  "GenSigInactiveValue" 0;
BA_DEF_DEF_  "GenSigSendType" "NoSigSendType";
BA_DEF_DEF_  "GenSigStartValue" 0;
BA_DEF_DEF_  "NWM-WakeupAllowed" "No";
BA_DEF_DEF_  "GenSigFuncType" "NoFunction";
BA_DEF_DEF_  "GenSigSwitchedByIgnition" "Yes";
BA_DEF_DEF_  "Fehlerwert" 0;
BA_DEF_DEF_  "GenSigMissingSourceValue" 0;
BA_ "GenMsgCycleTime" BO_ 2527679896 320;
BA_ "GenMsgILSupport" BO_ 2527679896 1;
BA_ "GenMsgPDUConstants" BO_ 2527679896 "0x7a,0xdd,0x42,0x9a,0x9f,0x9d,0x28,0xf7,0x16,0x78,0x96,0x86,0x87,0x6e,0x7c,0xaf";
BA_ "GenMsgSendType" BO_ 2527679896 0;
BA_ "GenMsgCycleTime" BO_ 705 80;
BA_ "GenMsgILSupport" BO_ 705 1;
BA_ "GenMsgPDUConstants" BO_ 705 "0x96,0x12,0x1e,0xcd,0x2f,0x45,0xec,0xcb,0xd1,0x39,0x04,0x7c,0xb7,0x29,0x37,0x47";
BA_ "GenMsgSendType" BO_ 705 0;
BA_ "GenMsgCycleTime" BO_ 2463978619 960;
BA_ "GenMsgCycleTimeFast" BO_ 2463978619 40;
BA_ "GenMsgDelayTime" BO_ 2463978619 40;
BA_ "GenMsgILSupport" BO_ 2463978619 1;
BA_ "GenMsgNrOfRepetition" BO_ 2463978619 10;
BA_ "GenMsgSendType" BO_ 2463978619 0;
BA_ "GenMsgCycleTime" BO_ 2527679660 320;
BA_ "GenMsgILSupport" BO_ 2527679660 1;
BA_ "GenMsgSendType" BO_ 2527679660 0;
BA_ "GenMsgStartDelayTime" BO_ 2527679660 250;
BA_ "GenMsgCycleTime" BO_ 707 80;
BA_ "GenMsgILSupport" BO_ 707 1;
BA_ "GenMsgPDUConstants" BO_ 707 "0x4e,0xc0,0xa1,0x90,0xc4,0xb0,0xe7,0x7d,0xdb,0x1e,0x6f,0x69,0xac,0x73,0x9c,0x17";
BA_ "GenMsgSendType" BO_ 707 0;
BA_ "GenMsgCycleTime" BO_ 1605 1000;
BA_ "GenMsgDelayTime" BO_ 1605 20;
BA_ "GenMsgILSupport" BO_ 1605 1;
BA_ "GenMsgSendType" BO_ 1605 0;
BA_ "GenMsgCycleTime" BO_ 2589283684 960;
BA_ "GenMsgDelayTime" BO_ 2589283684 320;
BA_ "GenMsgILSupport" BO_ 2589283684 1;
BA_ "GenMsgSendType" BO_ 2589283684 0;
BA_ "GenMsgStartDelayTime" BO_ 2589283684 320;
BA_ "GenMsgILSupport" BO_ 2549875571 1;
BA_ "MsgType" BO_ 2549875571 4;
BA_ "GenMsgILSupport" BO_ 2550006643 1;
BA_ "MsgType" BO_ 2550006643 4;
BA_ "GenMsgCycleTime" BO_ 173 1000;
BA_ "GenMsgDelayTime" BO_ 173 10;
BA_ "GenMsgILSupport" BO_ 173 1;
BA_ "GenMsgPDUConstants" BO_ 173 "0x3f,0x69,0x39,0xdc,0x94,0xf9,0x14,0x64,0xd8,0x6a,0x34,0xce,0xa2,0x55,0xb5,0x2c";
BA_ "GenMsgSendType" BO_ 173 0;
BA_ "GenMsgCycleTime" BO_ 968 200;
BA_ "GenMsgILSupport" BO_ 968 1;
BA_ "GenMsgSendType" BO_ 968 0;
BA_ "GenMsgCycleTime" BO_ 177 500;
BA_ "GenMsgDelayTime" BO_ 177 10;
BA_ "GenMsgILSupport" BO_ 177 1;
BA_ "GenMsgPDUConstants" BO_ 177 "0xe1,0x9e,0xc2,0xe9,0x48,0x98,0xf5,0xb6,0x47,0x83,0x26,0x45,0x9a,0x10,0x7b,0x1c";
BA_ "GenMsgSendType" BO_ 177 0;
BA_ "GenMsgStartDelayTime" BO_ 177 270;
BA_ "GenMsgCycleTime" BO_ 879 1000;
BA_ "GenMsgILSupport" BO_ 879 1;
BA_ "GenMsgSendType" BO_ 879 0;
BA_ "GenMsgCycleTime" BO_ 884 1000;
BA_ "GenMsgILSupport" BO_ 884 1;
BA_ "GenMsgSendType" BO_ 884 0;
BA_ "GenMsgCycleTime" BO_ 886 1000;
BA_ "GenMsgILSupport" BO_ 886 1;
BA_ "GenMsgSendType" BO_ 886 0;
BA_ "GenMsgCycleTime" BO_ 888 1000;
BA_ "GenMsgILSupport" BO_ 888 1;
BA_ "GenMsgSendType" BO_ 888 0;
BA_ "GenMsgCycleTime" BO_ 891 1000;
BA_ "GenMsgILSupport" BO_ 891 1;
BA_ "GenMsgSendType" BO_ 891 0;
BA_ "GenMsgCycleTime" BO_ 1364 1000;
BA_ "GenMsgILSupport" BO_ 1364 1;
BA_ "GenMsgSendType" BO_ 1364 0;
BA_ "GenMsgCycleTime" BO_ 299 200;
BA_ "GenMsgDelayTime" BO_ 299 20;
BA_ "GenMsgILSupport" BO_ 299 1;
BA_ "GenMsgPDUConstants" BO_ 299 "0x6a,0x38,0xb4,0x27,0x22,0xef,0xe1,0xbb,0xf8,0x80,0x84,0x49,0xc7,0x9e,0x1e,0x2b";
BA_ "GenMsgSendType" BO_ 299 0;
BA_ "GenMsgStartDelayTime" BO_ 299 40;
BA_ "GenMsgChkConstant" BO_ 310 55;
BA_ "GenMsgCycleTime" BO_ 310 100;
BA_ "GenMsgDelayTime" BO_ 310 10;
BA_ "GenMsgILSupport" BO_ 310 1;
BA_ "GenMsgPDUConstants" BO_ 310 "0x37,0x37,0x37,0x37,0x37,0x37,0x37,0x37,0x37,0x37,0x37,0x37,0x37,0x37,0x37,0x37";
BA_ "GenMsgSendType" BO_ 310 0;
BA_ "GenMsgCycleTime" BO_ 1410 200;
BA_ "GenMsgDelayTime" BO_ 1410 20;
BA_ "GenMsgILSupport" BO_ 1410 1;
BA_ "GenMsgSendType" BO_ 1410 0;
BA_ "GenMsgStartDelayTime" BO_ 1410 290;
BA_ "GenMsgCycleTime" BO_ 1416 500;
BA_ "GenMsgDelayTime" BO_ 1416 50;
BA_ "GenMsgILSupport" BO_ 1416 1;
BA_ "GenMsgSendType" BO_ 1416 0;
BA_ "GenMsgStartDelayTime" BO_ 1416 300;
BA_ "GenMsgCycleTime" BO_ 1016 500;
BA_ "GenMsgDelayTime" BO_ 1016 50;
BA_ "GenMsgILSupport" BO_ 1016 1;
BA_ "GenMsgSendType" BO_ 1016 0;
BA_ "GenMsgStartDelayTime" BO_ 1016 70;
BA_ "GenMsgChkConstant" BO_ 1412 127;
BA_ "GenMsgCycleTime" BO_ 1412 200;
BA_ "GenMsgILSupport" BO_ 1412 1;
BA_ "GenMsgPDUConstants" BO_ 1412 "0x7f,0x7f,0x7f,0x7f,0x7f,0x7f,0x7f,0x7f,0x7f,0x7f,0x7f,0x7f,0x7f,0x7f,0x7f,0x7f";
BA_ "GenMsgSendType" BO_ 1412 0;
BA_ "GenMsgStartDelayTime" BO_ 1412 310;
BA_ "GenMsgCycleTime" BO_ 1283 100;
BA_ "GenMsgDelayTime" BO_ 1283 10;
BA_ "GenMsgILSupport" BO_ 1283 1;
BA_ "GenMsgPDUConstants" BO_ 1283 "0xed,0xd6,0x96,0x63,0xa5,0x12,0xd5,0x9a,0x1e,0x0d,0x24,0xcd,0x8c,0xa6,0x2f,0x41";
BA_ "GenMsgSendType" BO_ 1283 0;
BA_ "GenMsgStartDelayTime" BO_ 1283 10;
BA_ "GenMsgCycleTime" BO_ 1340 100;
BA_ "GenMsgILSupport" BO_ 1340 1;
BA_ "GenMsgPDUConstants" BO_ 1340 "0x8e,0xf9,0xe1,0x2e,0x83,0x34,0xd0,0xf1,0xaa,0x2c,0xbb,0x81,0x17,0x60,0x11,0x37";
BA_ "GenMsgSendType" BO_ 1340 0;
BA_ "GenMsgCycleTime" BO_ 1524 500;
BA_ "GenMsgDelayTime" BO_ 1524 50;
BA_ "GenMsgILSupport" BO_ 1524 1;
BA_ "GenMsgSendType" BO_ 1524 0;
BA_ "GenMsgCycleTime" BO_ 312 200;
BA_ "GenMsgDelayTime" BO_ 312 20;
BA_ "GenMsgILSupport" BO_ 312 1;
BA_ "GenMsgPDUConstants" BO_ 312 "0x77,0x4e,0x14,0x87,0xf2,0xf8,0xb2,0x61,0xf6,0xa4,0x52,0x94,0xd4,0x81,0x2a,0xb1";
BA_ "GenMsgSendType" BO_ 312 0;
BA_ "GenMsgCycleTime" BO_ 2527679583 960;
BA_ "GenMsgCycleTimeFast" BO_ 2527679583 160;
BA_ "GenMsgDelayTime" BO_ 2527679583 80;
BA_ "GenMsgILSupport" BO_ 2527679583 1;
BA_ "GenMsgNrOfRepetition" BO_ 2527679583 5;
BA_ "GenMsgPDUConstants" BO_ 2527679583 "0xc6,0x7f,0x85,0xb6,0xe6,0xae,0xf8,0x26,0xb0,0x8c,0x19,0x10,0x5b,0x33,0x64,0x6c";
BA_ "GenMsgSendType" BO_ 2527679583 0;
BA_ "DiagRequest" BO_ 1903 1;
BA_ "MsgType" BO_ 1903 4;
BA_ "DiagResponse" BO_ 2009 1;
BA_ "MsgType" BO_ 2009 4;
BA_ "DiagState" BO_ 1792 1;
BA_ "MsgType" BO_ 1792 4;
BA_ "GenSigSendType" SG_ 2527679896 EFP_ReifenTempOf_HL 0;
BA_ "GenSigStartValue" SG_ 2527679896 EFP_ReifenTempOf_HL 63;
BA_ "GenSigSwitchedByIgnition" SG_ 2527679896 EFP_ReifenTempOf_HL 0;
BA_ "GenSigSendType" SG_ 2527679896 EFP_ReifenTempOf_HR 0;
BA_ "GenSigStartValue" SG_ 2527679896 EFP_ReifenTempOf_HR 63;
BA_ "GenSigSwitchedByIgnition" SG_ 2527679896 EFP_ReifenTempOf_HR 0;
BA_ "GenSigSendType" SG_ 2527679896 EFP_ReifenTempOf_VL 0;
BA_ "GenSigStartValue" SG_ 2527679896 EFP_ReifenTempOf_VL 63;
BA_ "GenSigSwitchedByIgnition" SG_ 2527679896 EFP_ReifenTempOf_VL 0;
BA_ "GenSigSendType" SG_ 2527679896 EFP_ReifenTempOf_VR 0;
BA_ "GenSigStartValue" SG_ 2527679896 EFP_ReifenTempOf_VR 63;
BA_ "GenSigSwitchedByIgnition" SG_ 2527679896 EFP_ReifenTempOf_VR 0;
BA_ "GenSigSendType" SG_ 2527679896 FA_FahrerAnf_Lift_Abwurf 0;
BA_ "GenSigSwitchedByIgnition" SG_ 2527679896 FA_FahrerAnf_Lift_Abwurf 0;
BA_ "GenSigSendType" SG_ 2527679896 FA_Niveau_AOCCT_fehlerstatus 0;
BA_ "GenSigSwitchedByIgnition" SG_ 2527679896 FA_Niveau_AOCCT_fehlerstatus 0;
BA_ "GenSigSendType" SG_ 2527679896 FA_Niveau_AOCCT_teststatus 0;
BA_ "GenSigSwitchedByIgnition" SG_ 2527679896 FA_Niveau_AOCCT_teststatus 0;
BA_ "GenSigSendType" SG_ 2527679896 FA_Niveau_AOCCT_timer1_count 0;
BA_ "GenSigSwitchedByIgnition" SG_ 2527679896 FA_Niveau_AOCCT_timer1_count 0;
BA_ "GenSigSendType" SG_ 2527679896 FA_Niveau_AOCCT_timer1_verbaut 0;
BA_ "GenSigSwitchedByIgnition" SG_ 2527679896 FA_Niveau_AOCCT_timer1_verbaut 0;
BA_ "GenSigSendType" SG_ 2527679896 FA_Niveau_AOCCT_timer2_count 0;
BA_ "GenSigSwitchedByIgnition" SG_ 2527679896 FA_Niveau_AOCCT_timer2_count 0;
BA_ "GenSigSendType" SG_ 2527679896 FA_Niveau_AOCCT_timer2_verbaut 0;
BA_ "GenSigSwitchedByIgnition" SG_ 2527679896 FA_Niveau_AOCCT_timer2_verbaut 0;
BA_ "GenSigSendType" SG_ 2527679896 FA_Zuladung_HA 0;
BA_ "GenSigStartValue" SG_ 2527679896 FA_Zuladung_HA 62;
BA_ "GenSigSwitchedByIgnition" SG_ 2527679896 FA_Zuladung_HA 0;
BA_ "Fehlerwert" SG_ 2527679896 FA_Zuladung_HA 63;
BA_ "GenSigSendType" SG_ 2527679896 FA_Zuladung_Status_HA 0;
BA_ "GenSigSwitchedByIgnition" SG_ 2527679896 FA_Zuladung_Status_HA 0;
BA_ "GenSigSendType" SG_ 2527679896 FA_Zuladung_Status_VA 0;
BA_ "GenSigSwitchedByIgnition" SG_ 2527679896 FA_Zuladung_Status_VA 0;
BA_ "GenSigSendType" SG_ 2527679896 FA_Zuladung_VA 0;
BA_ "GenSigStartValue" SG_ 2527679896 FA_Zuladung_VA 62;
BA_ "GenSigSwitchedByIgnition" SG_ 2527679896 FA_Zuladung_VA 0;
BA_ "Fehlerwert" SG_ 2527679896 FA_Zuladung_VA 63;
BA_ "GenSigSendType" SG_ 2527679896 Fahrwerk_12_BZ 0;
BA_ "GenSigFuncType" SG_ 2527679896 Fahrwerk_12_BZ 1;
BA_ "GenSigSendType" SG_ 2527679896 Fahrwerk_12_CRC 0;
BA_ "GenSigFuncType" SG_ 2527679896 Fahrwerk_12_CRC 2;
BA_ "GenSigSendType" SG_ 705 DR_Warnung 0;
BA_ "GenSigSendType" SG_ 705 eABC_Texte 0;
BA_ "GenSigSendType" SG_ 705 eABC_Warnung_Prio1 0;
BA_ "GenSigSendType" SG_ 705 eABC_Warnung_Prio2 0;
BA_ "GenSigSendType" SG_ 705 eAWS_Warnmeldung_Prio1 0;
BA_ "GenSigSendType" SG_ 705 eAWS_Warnmeldung_Prio2 0;
BA_ "GenSigSendType" SG_ 705 EFP_Status_Taster_Fahrwerk 0;
BA_ "GenSigSwitchedByIgnition" SG_ 705 EFP_Status_Taster_Fahrwerk 0;
BA_ "GenSigSendType" SG_ 705 EFP_Status_Taster_Lift 0;
BA_ "GenSigSwitchedByIgnition" SG_ 705 EFP_Status_Taster_Lift 0;
BA_ "GenSigSendType" SG_ 705 EFP_Verbau_DR 0;
BA_ "GenSigSendType" SG_ 705 EFP_Verbau_eABC 0;
BA_ "GenSigSendType" SG_ 705 EFP_Verbau_eAllrad 0;
BA_ "GenSigSendType" SG_ 705 EFP_Verbau_eAWS 0;
BA_ "GenSigSendType" SG_ 705 EFP_Verbau_LF 0;
BA_ "GenSigSendType" SG_ 705 EFP_Warnung_Naesse 0;
BA_ "GenSigSwitchedByIgnition" SG_ 705 EFP_Warnung_Naesse 0;
BA_ "GenSigSendType" SG_ 705 EFP_Warnung_Naesse_verf 0;
BA_ "GenSigSwitchedByIgnition" SG_ 705 EFP_Warnung_Naesse_verf 0;
BA_ "GenSigSendType" SG_ 705 Fahrwerk_Anzeige_01_BZ 0;
BA_ "GenSigFuncType" SG_ 705 Fahrwerk_Anzeige_01_BZ 1;
BA_ "GenSigSendType" SG_ 705 Fahrwerk_Anzeige_01_CRC 0;
BA_ "GenSigFuncType" SG_ 705 Fahrwerk_Anzeige_01_CRC 2;
BA_ "GenSigSendType" SG_ 705 FDR_Warnung_ALR 0;
BA_ "GenSigSwitchedByIgnition" SG_ 705 FDR_Warnung_ALR 0;
BA_ "GenSigSendType" SG_ 705 FDR_Warnung_TV 0;
BA_ "GenSigSwitchedByIgnition" SG_ 705 FDR_Warnung_TV 0;
BA_ "GenSigSendType" SG_ 705 LF_Texte 0;
BA_ "GenSigSendType" SG_ 705 LF_Texte_2 0;
BA_ "GenSigSwitchedByIgnition" SG_ 705 LF_Texte_2 0;
BA_ "GenSigSendType" SG_ 705 LF_Warnung_Prio1 0;
BA_ "GenSigSendType" SG_ 705 LF_Warnung_Prio1_02 0;
BA_ "GenSigSendType" SG_ 705 LF_Warnung_Prio2 0;
BA_ "GenSigSendType" SG_ 705 NR_LED_Ladelevel 0;
BA_ "GenSigStartValue" SG_ 705 NR_LED_Ladelevel 3;
BA_ "GenSigSwitchedByIgnition" SG_ 705 NR_LED_Ladelevel 0;
BA_ "GenSigSendType" SG_ 705 NR_LED_Offroadlevel 0;
BA_ "GenSigStartValue" SG_ 705 NR_LED_Offroadlevel 3;
BA_ "GenSigSwitchedByIgnition" SG_ 705 NR_LED_Offroadlevel 0;
BA_ "GenSigSendType" SG_ 705 NR_LED_Strassenlevel 0;
BA_ "GenSigStartValue" SG_ 705 NR_LED_Strassenlevel 3;
BA_ "GenSigSwitchedByIgnition" SG_ 705 NR_LED_Strassenlevel 0;
BA_ "GenSigSendType" SG_ 705 NR_LED_Sync 0;
BA_ "GenSigStartValue" SG_ 705 NR_LED_Sync 3;
BA_ "GenSigSwitchedByIgnition" SG_ 705 NR_LED_Sync 0;
BA_ "GenSigSendType" SG_ 705 NR_LED_XtraLevel 0;
BA_ "GenSigStartValue" SG_ 705 NR_LED_XtraLevel 3;
BA_ "GenSigSwitchedByIgnition" SG_ 705 NR_LED_XtraLevel 0;
BA_ "GenSigSendType" SG_ 2463978619 FAS_SollStatus_Fkt_AbstWarn_LRR 3;
BA_ "GenSigSwitchedByIgnition" SG_ 2463978619 FAS_SollStatus_Fkt_AbstWarn_LRR 0;
BA_ "GenSigSendType" SG_ 2463978619 FAS_SollStatus_Fkt_AbstWarn_MV 3;
BA_ "GenSigSwitchedByIgnition" SG_ 2463978619 FAS_SollStatus_Fkt_AbstWarn_MV 0;
BA_ "GenSigSendType" SG_ 2463978619 FAS_SollStatus_Fkt_ASW 3;
BA_ "GenSigSwitchedByIgnition" SG_ 2463978619 FAS_SollStatus_Fkt_ASW 0;
BA_ "GenSigSendType" SG_ 2463978619 FAS_SollStatus_Fkt_LGI 3;
BA_ "GenSigSwitchedByIgnition" SG_ 2463978619 FAS_SollStatus_Fkt_LGI 0;
BA_ "GenSigSendType" SG_ 2463978619 FAS_SollStatus_Fkt_MKE 3;
BA_ "GenSigSwitchedByIgnition" SG_ 2463978619 FAS_SollStatus_Fkt_MKE 0;
BA_ "GenSigActiveRepetitions" SG_ 2463978619 FAS_SollStatus_Fkt_NV 10;
BA_ "GenSigSendType" SG_ 2463978619 FAS_SollStatus_Fkt_NV 4;
BA_ "GenSigSwitchedByIgnition" SG_ 2463978619 FAS_SollStatus_Fkt_NV 0;
BA_ "GenSigSendType" SG_ 2463978619 FAS_SollStatus_Fkt_PreCrash 3;
BA_ "GenSigSwitchedByIgnition" SG_ 2463978619 FAS_SollStatus_Fkt_PreCrash 0;
BA_ "GenSigSendType" SG_ 2463978619 FAS_SollStatus_Fkt_STP 3;
BA_ "GenSigSwitchedByIgnition" SG_ 2463978619 FAS_SollStatus_Fkt_STP 0;
BA_ "GenSigSendType" SG_ 2463978619 FAS_SollStatus_Fkt_SWA 3;
BA_ "GenSigSwitchedByIgnition" SG_ 2463978619 FAS_SollStatus_Fkt_SWA 0;
BA_ "GenSigSendType" SG_ 2527679660 FB_Blindheit 0;
BA_ "GenSigSendType" SG_ 2527679660 FB_Fahrerwechsel 0;
BA_ "GenSigStartValue" SG_ 2527679660 FB_Fahrerwechsel 3;
BA_ "GenSigSendType" SG_ 2527679660 FB_Fehler 0;
BA_ "Fehlerwert" SG_ 2527679660 FB_Fehler 1;
BA_ "GenSigSendType" SG_ 2527679660 FB_Kopfaktivitaet_A1 0;
BA_ "GenSigStartValue" SG_ 2527679660 FB_Kopfaktivitaet_A1 15;
BA_ "GenSigSendType" SG_ 2527679660 FB_Kopfaktivitaet_A1_Guete 0;
BA_ "GenSigSendType" SG_ 2527679660 FB_Kopfaktivitaet_A2 0;
BA_ "GenSigStartValue" SG_ 2527679660 FB_Kopfaktivitaet_A2 15;
BA_ "GenSigSendType" SG_ 2527679660 FB_Kopfaktivitaet_A2_Guete 0;
BA_ "GenSigSendType" SG_ 2527679660 FB_Muedigkeit_Guete 0;
BA_ "GenSigSendType" SG_ 2527679660 FB_Muedigkeit_Index 0;
BA_ "GenSigStartValue" SG_ 2527679660 FB_Muedigkeit_Index 255;
BA_ "GenSigSendType" SG_ 2527679660 FB_NichtVerfuegbar 0;
BA_ "GenSigStartValue" SG_ 2527679660 FB_NichtVerfuegbar 1;
BA_ "GenSigSendType" SG_ 707 eAWS_Warnmeldung_Prio3 0;
BA_ "GenSigSwitchedByIgnition" SG_ 707 eAWS_Warnmeldung_Prio3 0;
BA_ "GenSigSendType" SG_ 707 EFP_Anf_Kuehlklappenwarnung 0;
BA_ "GenSigSwitchedByIgnition" SG_ 707 EFP_Anf_Kuehlklappenwarnung 0;
BA_ "GenSigSendType" SG_ 707 EFP_MomRad_Begr 0;
BA_ "GenSigStartValue" SG_ 707 EFP_MomRad_Begr 4094;
BA_ "GenSigSwitchedByIgnition" SG_ 707 EFP_MomRad_Begr 0;
BA_ "Fehlerwert" SG_ 707 EFP_MomRad_Begr 4095;
BA_ "GenSigSendType" SG_ 707 FA_Warnung_Transportniveau 0;
BA_ "GenSigSwitchedByIgnition" SG_ 707 FA_Warnung_Transportniveau 0;
BA_ "GenSigSendType" SG_ 707 FDR_04_BZ 0;
BA_ "GenSigFuncType" SG_ 707 FDR_04_BZ 1;
BA_ "GenSigSwitchedByIgnition" SG_ 707 FDR_04_BZ 0;
BA_ "GenSigSendType" SG_ 707 FDR_04_CRC 0;
BA_ "GenSigFuncType" SG_ 707 FDR_04_CRC 2;
BA_ "GenSigSwitchedByIgnition" SG_ 707 FDR_04_CRC 0;
BA_ "GenSigSendType" SG_ 707 FDR_M_HL_02 0;
BA_ "GenSigStartValue" SG_ 707 FDR_M_HL_02 254;
BA_ "GenSigSwitchedByIgnition" SG_ 707 FDR_M_HL_02 0;
BA_ "Fehlerwert" SG_ 707 FDR_M_HL_02 255;
BA_ "GenSigSendType" SG_ 707 FDR_M_HR_02 0;
BA_ "GenSigStartValue" SG_ 707 FDR_M_HR_02 254;
BA_ "GenSigSwitchedByIgnition" SG_ 707 FDR_M_HR_02 0;
BA_ "Fehlerwert" SG_ 707 FDR_M_HR_02 255;
BA_ "GenSigSendType" SG_ 707 FDR_M_VL_02 0;
BA_ "GenSigStartValue" SG_ 707 FDR_M_VL_02 254;
BA_ "GenSigSwitchedByIgnition" SG_ 707 FDR_M_VL_02 0;
BA_ "Fehlerwert" SG_ 707 FDR_M_VL_02 255;
BA_ "GenSigSendType" SG_ 707 FDR_M_VR_02 0;
BA_ "GenSigStartValue" SG_ 707 FDR_M_VR_02 254;
BA_ "GenSigSwitchedByIgnition" SG_ 707 FDR_M_VR_02 0;
BA_ "Fehlerwert" SG_ 707 FDR_M_VR_02 255;
BA_ "GenSigSendType" SG_ 1605 FLA_Abblendursache 3;
BA_ "Fehlerwert" SG_ 1605 FLA_Abblendursache 255;
BA_ "GenSigSendType" SG_ 1605 FLA_aktiv 3;
BA_ "GenSigSendType" SG_ 1605 FLA_Aufblenden 3;
BA_ "GenSigSendType" SG_ 1605 FLA_Fernlicht_PWM 3;
BA_ "GenSigStartValue" SG_ 1605 FLA_Fernlicht_PWM 100;
BA_ "Fehlerwert" SG_ 1605 FLA_Fernlicht_PWM 127;
BA_ "GenSigSendType" SG_ 1605 FLA_ISP_defekt 3;
BA_ "GenSigSendType" SG_ 1605 FLA_SAE_Mode 3;
BA_ "GenSigSendType" SG_ 1605 FLA_Sensor_blockiert 3;
BA_ "GenSigSendType" SG_ 1605 ISP_Dimmung_ASP_02 3;
BA_ "GenSigSendType" SG_ 1605 ISP_EC_aktiv 3;
BA_ "GenSigStartValue" SG_ 1605 ISP_EC_aktiv 1;
BA_ "GenSigSendType" SG_ 1605 ISP_EC_Lichtwert_hinten 3;
BA_ "GenSigStartValue" SG_ 1605 ISP_EC_Lichtwert_hinten 62;
BA_ "Fehlerwert" SG_ 1605 ISP_EC_Lichtwert_hinten 63;
BA_ "GenSigSendType" SG_ 1605 ISP_EC_Lichtwert_vorne 3;
BA_ "GenSigStartValue" SG_ 1605 ISP_EC_Lichtwert_vorne 62;
BA_ "Fehlerwert" SG_ 1605 ISP_EC_Lichtwert_vorne 63;
BA_ "GenSigSendType" SG_ 1605 ISP_Himmelsrichtung 3;
BA_ "GenSigStartValue" SG_ 1605 ISP_Himmelsrichtung 30;
BA_ "Fehlerwert" SG_ 1605 ISP_Himmelsrichtung 31;
BA_ "GenSigSendType" SG_ 1605 ISP_Kompass_aktiv 3;
BA_ "GenSigStartValue" SG_ 1605 ISP_Kompass_aktiv 1;
BA_ "GenSigSendType" SG_ 1605 ISP_Taste_betaetigt 3;
BA_ "GenSigSendType" SG_ 2589283684 FoD_Anz_Funktionsabschaltung 3;
BA_ "GenSigSwitchedByIgnition" SG_ 2589283684 FoD_Anz_Funktionsabschaltung 0;
BA_ "GenSigSendType" SG_ 2589283684 FoD_Transmission_Info 3;
BA_ "GenSigSwitchedByIgnition" SG_ 2589283684 FoD_Transmission_Info 0;
BA_ "GenSigSendType" SG_ 2549875571 FoD_ZR_Req_Data 3;
BA_ "GenSigFuncType" SG_ 2549875571 FoD_ZR_Req_Data 9;
BA_ "GenSigSwitchedByIgnition" SG_ 2549875571 FoD_ZR_Req_Data 0;
BA_ "GenSigSendType" SG_ 2550006643 FoD_ZR_Resp_Data 3;
BA_ "GenSigFuncType" SG_ 2550006643 FoD_ZR_Resp_Data 9;
BA_ "GenSigSwitchedByIgnition" SG_ 2550006643 FoD_ZR_Resp_Data 0;
BA_ "GenSigSendType" SG_ 173 GE_Fahrstufe 3;
BA_ "GenSigStartValue" SG_ 173 GE_Fahrstufe 1;
BA_ "GenSigSwitchedByIgnition" SG_ 173 GE_Fahrstufe 0;
BA_ "Fehlerwert" SG_ 173 GE_Fahrstufe 15;
BA_ "GenSigSendType" SG_ 173 GE_Freig_MMom_Vorhalt 0;
BA_ "GenSigSwitchedByIgnition" SG_ 173 GE_Freig_MMom_Vorhalt 0;
BA_ "GenSigSendType" SG_ 173 GE_MMom_Soll_02 0;
BA_ "GenSigStartValue" SG_ 173 GE_MMom_Soll_02 1022;
BA_ "GenSigSwitchedByIgnition" SG_ 173 GE_MMom_Soll_02 0;
BA_ "Fehlerwert" SG_ 173 GE_MMom_Soll_02 1023;
BA_ "GenSigSendType" SG_ 173 GE_MMom_Status 0;
BA_ "GenSigSwitchedByIgnition" SG_ 173 GE_MMom_Status 0;
BA_ "GenSigSendType" SG_ 173 GE_MMom_Status_02 0;
BA_ "GenSigSwitchedByIgnition" SG_ 173 GE_MMom_Status_02 0;
BA_ "GenSigSendType" SG_ 173 GE_MMom_Vorhalt_02 0;
BA_ "GenSigStartValue" SG_ 173 GE_MMom_Vorhalt_02 1022;
BA_ "GenSigSwitchedByIgnition" SG_ 173 GE_MMom_Vorhalt_02 0;
BA_ "Fehlerwert" SG_ 173 GE_MMom_Vorhalt_02 1023;
BA_ "GenSigSendType" SG_ 173 GE_reserv_Fahrstufe 0;
BA_ "GenSigSwitchedByIgnition" SG_ 173 GE_reserv_Fahrstufe 0;
BA_ "GenSigSendType" SG_ 173 GE_Schaltablauf 0;
BA_ "GenSigSwitchedByIgnition" SG_ 173 GE_Schaltablauf 0;
BA_ "GenSigSendType" SG_ 173 GE_Status_Kraftschluss 0;
BA_ "GenSigSwitchedByIgnition" SG_ 173 GE_Status_Kraftschluss 0;
BA_ "GenSigSendType" SG_ 173 GE_Uefkt 0;
BA_ "GenSigSwitchedByIgnition" SG_ 173 GE_Uefkt 0;
BA_ "Fehlerwert" SG_ 173 GE_Uefkt 1023;
BA_ "GenSigSendType" SG_ 173 GE_Uefkt_unplausibel 0;
BA_ "GenSigSwitchedByIgnition" SG_ 173 GE_Uefkt_unplausibel 0;
BA_ "GenSigSendType" SG_ 173 GE_Verbot_Ausblendung 0;
BA_ "GenSigSwitchedByIgnition" SG_ 173 GE_Verbot_Ausblendung 0;
BA_ "GenSigSendType" SG_ 173 GE_Zielgang 0;
BA_ "GenSigSwitchedByIgnition" SG_ 173 GE_Zielgang 0;
BA_ "Fehlerwert" SG_ 173 GE_Zielgang 15;
BA_ "GenSigSendType" SG_ 173 Getriebe_11_BZ 0;
BA_ "GenSigFuncType" SG_ 173 Getriebe_11_BZ 1;
BA_ "GenSigSwitchedByIgnition" SG_ 173 Getriebe_11_BZ 0;
BA_ "GenSigSendType" SG_ 173 Getriebe_11_CRC 0;
BA_ "GenSigFuncType" SG_ 173 Getriebe_11_CRC 2;
BA_ "GenSigSwitchedByIgnition" SG_ 173 Getriebe_11_CRC 0;
BA_ "GenSigSendType" SG_ 968 Freilauf_Charisma_FahrPr 0;
BA_ "GenSigSwitchedByIgnition" SG_ 968 Freilauf_Charisma_FahrPr 0;
BA_ "GenSigSendType" SG_ 968 Freilauf_Charisma_Status 0;
BA_ "GenSigSwitchedByIgnition" SG_ 968 Freilauf_Charisma_Status 0;
BA_ "GenSigSendType" SG_ 968 GE_amax_moeglich 0;
BA_ "GenSigStartValue" SG_ 968 GE_amax_moeglich 84;
BA_ "GenSigSwitchedByIgnition" SG_ 968 GE_amax_moeglich 0;
BA_ "GenSigSendType" SG_ 968 GE_Charisma_FahrPr 0;
BA_ "GenSigSwitchedByIgnition" SG_ 968 GE_Charisma_FahrPr 0;
BA_ "GenSigSendType" SG_ 968 GE_Charisma_Status 0;
BA_ "GenSigSwitchedByIgnition" SG_ 968 GE_Charisma_Status 0;
BA_ "GenSigSendType" SG_ 968 GE_Codierung_MSG 0;
BA_ "GenSigSwitchedByIgnition" SG_ 968 GE_Codierung_MSG 0;
BA_ "GenSigSendType" SG_ 968 GE_Freigabe_Info_WFS 0;
BA_ "GenSigSwitchedByIgnition" SG_ 968 GE_Freigabe_Info_WFS 0;
BA_ "GenSigSendType" SG_ 968 GE_Freigabe_Verfallsinfo_WFS 0;
BA_ "GenSigSwitchedByIgnition" SG_ 968 GE_Freigabe_Verfallsinfo_WFS 0;
BA_ "GenSigSendType" SG_ 968 GE_Heizwunsch 0;
BA_ "GenSigStartValue" SG_ 968 GE_Heizwunsch 1;
BA_ "GenSigSwitchedByIgnition" SG_ 968 GE_Heizwunsch 0;
BA_ "GenSigSendType" SG_ 968 GE_LaunchControl 0;
BA_ "GenSigSwitchedByIgnition" SG_ 968 GE_LaunchControl 0;
BA_ "GenSigSendType" SG_ 968 GE_LaunchControl_LB 0;
BA_ "GenSigSwitchedByIgnition" SG_ 968 GE_LaunchControl_LB 0;
BA_ "GenSigSendType" SG_ 968 GE_LFR_Adaption 0;
BA_ "GenSigSwitchedByIgnition" SG_ 968 GE_LFR_Adaption 0;
BA_ "GenSigSendType" SG_ 968 GE_OBD_AbsperrVent 0;
BA_ "GenSigSwitchedByIgnition" SG_ 968 GE_OBD_AbsperrVent 0;
BA_ "GenSigSendType" SG_ 968 GE_OBD_Status 0;
BA_ "GenSigSwitchedByIgnition" SG_ 968 GE_OBD_Status 0;
BA_ "GenSigSendType" SG_ 968 GE_Remotestart_Betrieb 0;
BA_ "GenSigSwitchedByIgnition" SG_ 968 GE_Remotestart_Betrieb 0;
BA_ "GenSigSendType" SG_ 968 GE_Sperr_Info_WFS 0;
BA_ "GenSigSwitchedByIgnition" SG_ 968 GE_Sperr_Info_WFS 0;
BA_ "GenSigSendType" SG_ 968 GE_Status_PaddleNeutral 0;
BA_ "GenSigSwitchedByIgnition" SG_ 968 GE_Status_PaddleNeutral 0;
BA_ "GenSigSendType" SG_ 968 GE_Sumpftemperatur 0;
BA_ "GenSigSwitchedByIgnition" SG_ 968 GE_Sumpftemperatur 0;
BA_ "Fehlerwert" SG_ 968 GE_Sumpftemperatur 255;
BA_ "GenSigSendType" SG_ 968 GE_Zustand_Kuppltemp 0;
BA_ "GenSigSwitchedByIgnition" SG_ 968 GE_Zustand_Kuppltemp 0;
BA_ "GenSigSendType" SG_ 177 GE_Anschleppstart_Freigabe 0;
BA_ "GenSigSwitchedByIgnition" SG_ 177 GE_Anschleppstart_Freigabe 0;
BA_ "GenSigSendType" SG_ 177 GE_Eingangsdrehz_Praed 0;
BA_ "GenSigStartValue" SG_ 177 GE_Eingangsdrehz_Praed 16382;
BA_ "GenSigSwitchedByIgnition" SG_ 177 GE_Eingangsdrehz_Praed 0;
BA_ "Fehlerwert" SG_ 177 GE_Eingangsdrehz_Praed 16383;
BA_ "GenSigSendType" SG_ 177 GE_Fahrprogramm 0;
BA_ "GenSigSwitchedByIgnition" SG_ 177 GE_Fahrprogramm 0;
BA_ "GenSigSendType" SG_ 177 GE_Freilauf_Status 3;
BA_ "GenSigSwitchedByIgnition" SG_ 177 GE_Freilauf_Status 0;
BA_ "Fehlerwert" SG_ 177 GE_Freilauf_Status 7;
BA_ "GenSigSendType" SG_ 177 GE_Getriebestatus_02 0;
BA_ "GenSigSwitchedByIgnition" SG_ 177 GE_Getriebestatus_02 0;
BA_ "GenSigSendType" SG_ 177 GE_Grundeinstellung 0;
BA_ "GenSigSwitchedByIgnition" SG_ 177 GE_Grundeinstellung 0;
BA_ "GenSigSendType" SG_ 177 GE_KomFehler_ESP 0;
BA_ "GenSigSwitchedByIgnition" SG_ 177 GE_KomFehler_ESP 0;
BA_ "Fehlerwert" SG_ 177 GE_KomFehler_ESP 1;
BA_ "GenSigSendType" SG_ 177 GE_Rollrichtung_falsch 0;
BA_ "GenSigSwitchedByIgnition" SG_ 177 GE_Rollrichtung_falsch 0;
BA_ "GenSigSendType" SG_ 177 GE_Strombedarf_erh 0;
BA_ "GenSigSwitchedByIgnition" SG_ 177 GE_Strombedarf_erh 0;
BA_ "GenSigSendType" SG_ 177 GE_TippZustand 0;
BA_ "GenSigSwitchedByIgnition" SG_ 177 GE_TippZustand 0;
BA_ "GenSigSendType" SG_ 177 GE_Uefkt_Praed 0;
BA_ "GenSigSwitchedByIgnition" SG_ 177 GE_Uefkt_Praed 0;
BA_ "Fehlerwert" SG_ 177 GE_Uefkt_Praed 16383;
BA_ "GenSigSendType" SG_ 177 Getriebe_17_BZ 0;
BA_ "GenSigFuncType" SG_ 177 Getriebe_17_BZ 1;
BA_ "GenSigSwitchedByIgnition" SG_ 177 Getriebe_17_BZ 0;
BA_ "GenSigSendType" SG_ 177 Getriebe_17_CRC 0;
BA_ "GenSigFuncType" SG_ 177 Getriebe_17_CRC 2;
BA_ "GenSigSwitchedByIgnition" SG_ 177 Getriebe_17_CRC 0;
BA_ "GenSigSendType" SG_ 879 GNSS_Breite_Ortung 0;
BA_ "GenSigStartValue" SG_ 879 GNSS_Breite_Ortung 134217726;
BA_ "GenSigSwitchedByIgnition" SG_ 879 GNSS_Breite_Ortung 0;
BA_ "Fehlerwert" SG_ 879 GNSS_Breite_Ortung 134217727;
BA_ "GenSigSendType" SG_ 879 GNSS_Fehlerzustand 0;
BA_ "GenSigSwitchedByIgnition" SG_ 879 GNSS_Fehlerzustand 0;
BA_ "GenSigSendType" SG_ 879 GNSS_Laenge_Ortung 0;
BA_ "GenSigStartValue" SG_ 879 GNSS_Laenge_Ortung 268435454;
BA_ "GenSigSwitchedByIgnition" SG_ 879 GNSS_Laenge_Ortung 0;
BA_ "Fehlerwert" SG_ 879 GNSS_Laenge_Ortung 268435455;
BA_ "GenSigSendType" SG_ 879 GNSS_Nachrichtenpaket_ID1 0;
BA_ "GenSigSwitchedByIgnition" SG_ 879 GNSS_Nachrichtenpaket_ID1 0;
BA_ "GenSigSendType" SG_ 879 GNSS_Ortung_FIX_Typ 0;
BA_ "GenSigSwitchedByIgnition" SG_ 879 GNSS_Ortung_FIX_Typ 0;
BA_ "GenSigSendType" SG_ 879 GNSS_Richtung_Breite_Ortung 0;
BA_ "GenSigStartValue" SG_ 879 GNSS_Richtung_Breite_Ortung 1;
BA_ "GenSigSwitchedByIgnition" SG_ 879 GNSS_Richtung_Breite_Ortung 0;
BA_ "GenSigSendType" SG_ 879 GNSS_Richtung_Laenge_Ortung 0;
BA_ "GenSigStartValue" SG_ 879 GNSS_Richtung_Laenge_Ortung 1;
BA_ "GenSigSwitchedByIgnition" SG_ 879 GNSS_Richtung_Laenge_Ortung 0;
BA_ "GenSigSendType" SG_ 884 GNSS_Nachrichtenpaket_ID2 0;
BA_ "GenSigSwitchedByIgnition" SG_ 884 GNSS_Nachrichtenpaket_ID2 0;
BA_ "GenSigSendType" SG_ 884 GNSS_Ortung_2D_Geschw_ue_Grund 0;
BA_ "GenSigStartValue" SG_ 884 GNSS_Ortung_2D_Geschw_ue_Grund 510;
BA_ "GenSigSwitchedByIgnition" SG_ 884 GNSS_Ortung_2D_Geschw_ue_Grund 0;
BA_ "Fehlerwert" SG_ 884 GNSS_Ortung_2D_Geschw_ue_Grund 511;
BA_ "GenSigSendType" SG_ 884 GNSS_Ortung_Ausrichtung 0;
BA_ "GenSigStartValue" SG_ 884 GNSS_Ortung_Ausrichtung 4094;
BA_ "GenSigSwitchedByIgnition" SG_ 884 GNSS_Ortung_Ausrichtung 0;
BA_ "Fehlerwert" SG_ 884 GNSS_Ortung_Ausrichtung 4095;
BA_ "GenSigSendType" SG_ 884 GNSS_Ortung_Latenz 0;
BA_ "GenSigStartValue" SG_ 884 GNSS_Ortung_Latenz 1022;
BA_ "GenSigSwitchedByIgnition" SG_ 884 GNSS_Ortung_Latenz 0;
BA_ "Fehlerwert" SG_ 884 GNSS_Ortung_Latenz 1023;
BA_ "GenSigSendType" SG_ 884 GNSS_Ortung_Noerdliche_Geschw 0;
BA_ "GenSigStartValue" SG_ 884 GNSS_Ortung_Noerdliche_Geschw 1022;
BA_ "GenSigSwitchedByIgnition" SG_ 884 GNSS_Ortung_Noerdliche_Geschw 0;
BA_ "Fehlerwert" SG_ 884 GNSS_Ortung_Noerdliche_Geschw 1023;
BA_ "GenSigSendType" SG_ 884 GNSS_Ortung_Oestliche_Geschw 0;
BA_ "GenSigStartValue" SG_ 884 GNSS_Ortung_Oestliche_Geschw 1022;
BA_ "GenSigSwitchedByIgnition" SG_ 884 GNSS_Ortung_Oestliche_Geschw 0;
BA_ "Fehlerwert" SG_ 884 GNSS_Ortung_Oestliche_Geschw 1023;
BA_ "GenSigSendType" SG_ 884 GNSS_Ortung_Vertikale_Geschw 0;
BA_ "GenSigStartValue" SG_ 884 GNSS_Ortung_Vertikale_Geschw 1022;
BA_ "GenSigSwitchedByIgnition" SG_ 884 GNSS_Ortung_Vertikale_Geschw 0;
BA_ "Fehlerwert" SG_ 884 GNSS_Ortung_Vertikale_Geschw 1023;
BA_ "GenSigSendType" SG_ 886 GNSS_Nachrichtenpaket_ID3 0;
BA_ "GenSigSwitchedByIgnition" SG_ 886 GNSS_Nachrichtenpaket_ID3 0;
BA_ "GenSigSendType" SG_ 886 GNSS_Ortung_GDOP 0;
BA_ "GenSigStartValue" SG_ 886 GNSS_Ortung_GDOP 510;
BA_ "GenSigSwitchedByIgnition" SG_ 886 GNSS_Ortung_GDOP 0;
BA_ "Fehlerwert" SG_ 886 GNSS_Ortung_GDOP 511;
BA_ "GenSigSendType" SG_ 886 GNSS_Ortung_Guete_Ausrichtung 0;
BA_ "GenSigStartValue" SG_ 886 GNSS_Ortung_Guete_Ausrichtung 62;
BA_ "GenSigSwitchedByIgnition" SG_ 886 GNSS_Ortung_Guete_Ausrichtung 0;
BA_ "Fehlerwert" SG_ 886 GNSS_Ortung_Guete_Ausrichtung 63;
BA_ "GenSigSendType" SG_ 886 GNSS_Ortung_Guete_Geschwindigk 0;
BA_ "GenSigStartValue" SG_ 886 GNSS_Ortung_Guete_Geschwindigk 62;
BA_ "GenSigSwitchedByIgnition" SG_ 886 GNSS_Ortung_Guete_Geschwindigk 0;
BA_ "Fehlerwert" SG_ 886 GNSS_Ortung_Guete_Geschwindigk 63;
BA_ "GenSigSendType" SG_ 886 GNSS_Ortung_Guete_horizontal 0;
BA_ "GenSigStartValue" SG_ 886 GNSS_Ortung_Guete_horizontal 254;
BA_ "GenSigSwitchedByIgnition" SG_ 886 GNSS_Ortung_Guete_horizontal 0;
BA_ "Fehlerwert" SG_ 886 GNSS_Ortung_Guete_horizontal 255;
BA_ "GenSigSendType" SG_ 886 GNSS_Ortung_Guete_vertikal 0;
BA_ "GenSigStartValue" SG_ 886 GNSS_Ortung_Guete_vertikal 62;
BA_ "GenSigSwitchedByIgnition" SG_ 886 GNSS_Ortung_Guete_vertikal 0;
BA_ "Fehlerwert" SG_ 886 GNSS_Ortung_Guete_vertikal 63;
BA_ "GenSigSendType" SG_ 886 GNSS_Ortung_HDOP 0;
BA_ "GenSigStartValue" SG_ 886 GNSS_Ortung_HDOP 510;
BA_ "GenSigSwitchedByIgnition" SG_ 886 GNSS_Ortung_HDOP 0;
BA_ "Fehlerwert" SG_ 886 GNSS_Ortung_HDOP 511;
BA_ "GenSigSendType" SG_ 886 GNSS_Ortung_PDOP 0;
BA_ "GenSigStartValue" SG_ 886 GNSS_Ortung_PDOP 510;
BA_ "GenSigSwitchedByIgnition" SG_ 886 GNSS_Ortung_PDOP 0;
BA_ "Fehlerwert" SG_ 886 GNSS_Ortung_PDOP 511;
BA_ "GenSigSendType" SG_ 886 GNSS_Ortung_VDOP 0;
BA_ "GenSigStartValue" SG_ 886 GNSS_Ortung_VDOP 510;
BA_ "GenSigSwitchedByIgnition" SG_ 886 GNSS_Ortung_VDOP 0;
BA_ "Fehlerwert" SG_ 886 GNSS_Ortung_VDOP 511;
BA_ "GenSigSendType" SG_ 888 GNSS_Nachrichtenpaket_ID4 0;
BA_ "GenSigSwitchedByIgnition" SG_ 888 GNSS_Nachrichtenpaket_ID4 0;
BA_ "GenSigSendType" SG_ 888 GNSS_Ortung_Hoehe 0;
BA_ "GenSigStartValue" SG_ 888 GNSS_Ortung_Hoehe 4094;
BA_ "GenSigSwitchedByIgnition" SG_ 888 GNSS_Ortung_Hoehe 0;
BA_ "Fehlerwert" SG_ 888 GNSS_Ortung_Hoehe 4095;
BA_ "GenSigSendType" SG_ 888 GNSS_Ortung_Zeit_in_GPSWoche 0;
BA_ "GenSigStartValue" SG_ 888 GNSS_Ortung_Zeit_in_GPSWoche 1073741822;
BA_ "GenSigSwitchedByIgnition" SG_ 888 GNSS_Ortung_Zeit_in_GPSWoche 0;
BA_ "Fehlerwert" SG_ 888 GNSS_Ortung_Zeit_in_GPSWoche 1073741823;
BA_ "GenSigSendType" SG_ 891 GNSS_Empfaenger_Status 0;
BA_ "GenSigSwitchedByIgnition" SG_ 891 GNSS_Empfaenger_Status 0;
BA_ "GenSigSendType" SG_ 891 GNSS_Empfangbare_Satelliten 0;
BA_ "GenSigSwitchedByIgnition" SG_ 891 GNSS_Empfangbare_Satelliten 0;
BA_ "GenSigSendType" SG_ 891 GNSS_Genutzte_Satelliten 0;
BA_ "GenSigSwitchedByIgnition" SG_ 891 GNSS_Genutzte_Satelliten 0;
BA_ "GenSigSendType" SG_ 891 GNSS_GLONASS_in_Nutzung 0;
BA_ "GenSigSwitchedByIgnition" SG_ 891 GNSS_GLONASS_in_Nutzung 0;
BA_ "GenSigSendType" SG_ 891 GNSS_GPS_in_Nutzung 0;
BA_ "GenSigSwitchedByIgnition" SG_ 891 GNSS_GPS_in_Nutzung 0;
BA_ "GenSigSendType" SG_ 891 GNSS_Nachrichtenpaket_ID5 0;
BA_ "GenSigSwitchedByIgnition" SG_ 891 GNSS_Nachrichtenpaket_ID5 0;
BA_ "GenSigSendType" SG_ 891 GNSS_Sichtbare_Satelliten 0;
BA_ "GenSigSwitchedByIgnition" SG_ 891 GNSS_Sichtbare_Satelliten 0;
BA_ "GenSigSendType" SG_ 891 GNSS_UTC_Zeit 0;
BA_ "GenSigSwitchedByIgnition" SG_ 891 GNSS_UTC_Zeit 0;
BA_ "GenSigSendType" SG_ 1364 GNSS_Nachrichtenpaket_ID6 0;
BA_ "GenSigSwitchedByIgnition" SG_ 1364 GNSS_Nachrichtenpaket_ID6 0;
BA_ "GenSigSendType" SG_ 1364 GNSS_Sat_Info_Azimuth_ID_1 0;
BA_ "GenSigStartValue" SG_ 1364 GNSS_Sat_Info_Azimuth_ID_1 511;
BA_ "GenSigSwitchedByIgnition" SG_ 1364 GNSS_Sat_Info_Azimuth_ID_1 0;
BA_ "GenSigSendType" SG_ 1364 GNSS_Sat_Info_Hoehenwinkel_ID_1 0;
BA_ "GenSigStartValue" SG_ 1364 GNSS_Sat_Info_Hoehenwinkel_ID_1 127;
BA_ "GenSigSwitchedByIgnition" SG_ 1364 GNSS_Sat_Info_Hoehenwinkel_ID_1 0;
BA_ "GenSigSendType" SG_ 1364 GNSS_Sat_Info_Sat_ID_1 0;
BA_ "GenSigSwitchedByIgnition" SG_ 1364 GNSS_Sat_Info_Sat_ID_1 0;
BA_ "GenSigSendType" SG_ 1364 GNSS_Sat_Info_SNR_ID_1 0;
BA_ "GenSigStartValue" SG_ 1364 GNSS_Sat_Info_SNR_ID_1 31;
BA_ "GenSigSwitchedByIgnition" SG_ 1364 GNSS_Sat_Info_SNR_ID_1 0;
BA_ "GenSigSendType" SG_ 299 GRA_Abbrechen 0;
BA_ "GenSigSendType" SG_ 299 GRA_ACC_01_BZ 0;
BA_ "GenSigFuncType" SG_ 299 GRA_ACC_01_BZ 1;
BA_ "GenSigSendType" SG_ 299 GRA_ACC_01_CRC 0;
BA_ "GenSigFuncType" SG_ 299 GRA_ACC_01_CRC 2;
BA_ "GenSigSendType" SG_ 299 GRA_Codierung 0;
BA_ "GenSigSendType" SG_ 299 GRA_Fehler 0;
BA_ "Fehlerwert" SG_ 299 GRA_Fehler 1;
BA_ "GenSigSendType" SG_ 299 GRA_Hauptschalter 3;
BA_ "GenSigSendType" SG_ 299 GRA_LIM_Taste_verfuegbar 0;
BA_ "GenSigFuncType" SG_ 299 GRA_LIM_Taste_verfuegbar 8;
BA_ "GenSigSendType" SG_ 299 GRA_Limiter 3;
BA_ "GenSigSendType" SG_ 299 GRA_reserveByte4 0;
BA_ "GenSigSendType" SG_ 299 GRA_reserveByte5 0;
BA_ "GenSigSendType" SG_ 299 GRA_reserveByte6 0;
BA_ "GenSigSendType" SG_ 299 GRA_reserveByte7 0;
BA_ "GenSigSendType" SG_ 299 GRA_reserveByte8 0;
BA_ "GenSigSendType" SG_ 299 GRA_Tip_Hoch 0;
BA_ "GenSigSendType" SG_ 299 GRA_Tip_Runter 0;
BA_ "GenSigSendType" SG_ 299 GRA_Tip_Setzen 0;
BA_ "GenSigSendType" SG_ 299 GRA_Tip_Stufe_2 0;
BA_ "GenSigSendType" SG_ 299 GRA_Tip_Wiederaufnahme 0;
BA_ "GenSigSendType" SG_ 299 GRA_TravelAssist 3;
BA_ "GenSigSwitchedByIgnition" SG_ 299 GRA_TravelAssist 0;
BA_ "GenSigSendType" SG_ 299 GRA_Typ_Bedienteil 0;
BA_ "GenSigSendType" SG_ 299 GRA_Typ_Hauptschalter 0;
BA_ "GenSigSendType" SG_ 299 GRA_Verstellung_Zeitluecke 0;
BA_ "GenSigSendType" SG_ 310 HAL_01_BZ 0;
BA_ "GenSigFuncType" SG_ 310 HAL_01_BZ 1;
BA_ "GenSigSwitchedByIgnition" SG_ 310 HAL_01_BZ 0;
BA_ "GenSigSendType" SG_ 310 HAL_01_CRC 0;
BA_ "GenSigFuncType" SG_ 310 HAL_01_CRC 2;
BA_ "GenSigSwitchedByIgnition" SG_ 310 HAL_01_CRC 0;
BA_ "GenSigSendType" SG_ 310 HAL_Charisma_FahrPr 0;
BA_ "GenSigSwitchedByIgnition" SG_ 310 HAL_Charisma_FahrPr 0;
BA_ "GenSigSendType" SG_ 310 HAL_Charisma_Status 0;
BA_ "GenSigSwitchedByIgnition" SG_ 310 HAL_Charisma_Status 0;
BA_ "GenSigSendType" SG_ 310 HAL_EFP_FahrPr 0;
BA_ "GenSigSwitchedByIgnition" SG_ 310 HAL_EFP_FahrPr 0;
BA_ "GenSigSendType" SG_ 310 HAL_Fahrerwunschwinkel_Soll 0;
BA_ "GenSigStartValue" SG_ 310 HAL_Fahrerwunschwinkel_Soll 1022;
BA_ "GenSigSwitchedByIgnition" SG_ 310 HAL_Fahrerwunschwinkel_Soll 0;
BA_ "Fehlerwert" SG_ 310 HAL_Fahrerwunschwinkel_Soll 1023;
BA_ "GenSigSendType" SG_ 310 HAL_max_Gradient 0;
BA_ "GenSigStartValue" SG_ 310 HAL_max_Gradient 126;
BA_ "GenSigSwitchedByIgnition" SG_ 310 HAL_max_Gradient 0;
BA_ "Fehlerwert" SG_ 310 HAL_max_Gradient 127;
BA_ "GenSigSendType" SG_ 310 HAL_QBit_Radwinkel 0;
BA_ "GenSigSwitchedByIgnition" SG_ 310 HAL_QBit_Radwinkel 0;
BA_ "GenSigSendType" SG_ 310 HAL_Radwinkel 0;
BA_ "GenSigStartValue" SG_ 310 HAL_Radwinkel 1022;
BA_ "GenSigSwitchedByIgnition" SG_ 310 HAL_Radwinkel 0;
BA_ "Fehlerwert" SG_ 310 HAL_Radwinkel 1023;
BA_ "GenSigSendType" SG_ 310 HAL_Status 0;
BA_ "GenSigSwitchedByIgnition" SG_ 310 HAL_Status 0;
BA_ "GenSigSendType" SG_ 310 HAL_Status_2 0;
BA_ "GenSigSwitchedByIgnition" SG_ 310 HAL_Status_2 0;
BA_ "GenSigSendType" SG_ 310 HAL_VZ_Fahrerwunschwinkel_Soll 0;
BA_ "GenSigSwitchedByIgnition" SG_ 310 HAL_VZ_Fahrerwunschwinkel_Soll 0;
BA_ "GenSigSendType" SG_ 310 HAL_VZ_Radwinkel 0;
BA_ "GenSigSwitchedByIgnition" SG_ 310 HAL_VZ_Radwinkel 0;
BA_ "GenSigSendType" SG_ 310 HAL_Warnungen 3;
BA_ "GenSigSwitchedByIgnition" SG_ 310 HAL_Warnungen 0;
BA_ "GenSigSendType" SG_ 310 HAL_Winkelbegrenzung 0;
BA_ "GenSigSwitchedByIgnition" SG_ 310 HAL_Winkelbegrenzung 0;
BA_ "GenSigSendType" SG_ 1410 HD_Bewegung_auf 0;
BA_ "GenSigSwitchedByIgnition" SG_ 1410 HD_Bewegung_auf 0;
BA_ "GenSigSendType" SG_ 1410 HD_Bewegung_zu 0;
BA_ "GenSigSwitchedByIgnition" SG_ 1410 HD_Bewegung_zu 0;
BA_ "GenSigSendType" SG_ 1410 HD_Endstellung_oben 0;
BA_ "GenSigSwitchedByIgnition" SG_ 1410 HD_Endstellung_oben 0;
BA_ "GenSigSendType" SG_ 1410 HD_Endstellung_unten 0;
BA_ "GenSigSwitchedByIgnition" SG_ 1410 HD_Endstellung_unten 0;
BA_ "GenSigSendType" SG_ 1410 HD_Innentaster_betaetigt 0;
BA_ "GenSigSwitchedByIgnition" SG_ 1410 HD_Innentaster_betaetigt 0;
BA_ "GenSigSendType" SG_ 1410 HD_Position 0;
BA_ "GenSigSwitchedByIgnition" SG_ 1410 HD_Position 0;
BA_ "GenSigSendType" SG_ 1410 HD_Rueckmeld_prog 0;
BA_ "GenSigSwitchedByIgnition" SG_ 1410 HD_Rueckmeld_prog 0;
BA_ "GenSigSendType" SG_ 1410 HD_Taster_defekt 0;
BA_ "GenSigSwitchedByIgnition" SG_ 1410 HD_Taster_defekt 0;
BA_ "GenSigSendType" SG_ 1410 HD_UeKB_erkannt 0;
BA_ "GenSigSwitchedByIgnition" SG_ 1410 HD_UeKB_erkannt 0;
BA_ "GenSigSendType" SG_ 1410 HD_Verr_Taster_betaetigt_inv 0;
BA_ "GenSigSwitchedByIgnition" SG_ 1410 HD_Verr_Taster_betaetigt_inv 0;
BA_ "GenSigSendType" SG_ 1410 HD_Verriegelungstaster_betaetigt 0;
BA_ "GenSigSwitchedByIgnition" SG_ 1410 HD_Verriegelungstaster_betaetigt 0;
BA_ "GenSigSendType" SG_ 1410 HD_ZZH_Schalter_S3 3;
BA_ "GenSigSwitchedByIgnition" SG_ 1410 HD_ZZH_Schalter_S3 0;
BA_ "GenSigSendType" SG_ 1416 BCM1_TCH_HLR_Anf 3;
BA_ "GenSigSwitchedByIgnition" SG_ 1416 BCM1_TCH_HLR_Anf 0;
BA_ "GenSigSendType" SG_ 1416 FSH_LED 3;
BA_ "GenSigSwitchedByIgnition" SG_ 1416 FSH_LED 0;
BA_ "GenSigSendType" SG_ 1416 HLR_SIH_Freigabe_Fond 3;
BA_ "GenSigSwitchedByIgnition" SG_ 1416 HLR_SIH_Freigabe_Fond 0;
BA_ "GenSigSendType" SG_ 1416 HSH_LED 3;
BA_ "GenSigSwitchedByIgnition" SG_ 1416 HSH_LED 0;
BA_ "GenSigSendType" SG_ 1416 KRH_Stufe_LED_li 3;
BA_ "GenSigSwitchedByIgnition" SG_ 1416 KRH_Stufe_LED_li 0;
BA_ "GenSigSendType" SG_ 1416 KRH_Stufe_LED_re 3;
BA_ "GenSigSwitchedByIgnition" SG_ 1416 KRH_Stufe_LED_re 0;
BA_ "GenSigSendType" SG_ 1416 SIH_Stufe_LED_HL 3;
BA_ "GenSigSwitchedByIgnition" SG_ 1416 SIH_Stufe_LED_HL 0;
BA_ "GenSigSendType" SG_ 1416 SIH_Stufe_LED_HR 3;
BA_ "GenSigSwitchedByIgnition" SG_ 1416 SIH_Stufe_LED_HR 0;
BA_ "GenSigSendType" SG_ 1416 SIH_Stufe_LED_li 3;
BA_ "GenSigSwitchedByIgnition" SG_ 1416 SIH_Stufe_LED_li 0;
BA_ "GenSigSendType" SG_ 1416 SIH_Stufe_LED_re 3;
BA_ "GenSigSwitchedByIgnition" SG_ 1416 SIH_Stufe_LED_re 0;
BA_ "GenSigSendType" SG_ 1416 SIL_Stufe_LED_HL 3;
BA_ "GenSigSwitchedByIgnition" SG_ 1416 SIL_Stufe_LED_HL 0;
BA_ "GenSigSendType" SG_ 1416 SIL_Stufe_LED_HR 3;
BA_ "GenSigSwitchedByIgnition" SG_ 1416 SIL_Stufe_LED_HR 0;
BA_ "GenSigSendType" SG_ 1416 SIL_Stufe_LED_li 3;
BA_ "GenSigSwitchedByIgnition" SG_ 1416 SIL_Stufe_LED_li 0;
BA_ "GenSigSendType" SG_ 1416 SIL_Stufe_LED_re 3;
BA_ "GenSigSwitchedByIgnition" SG_ 1416 SIL_Stufe_LED_re 0;
BA_ "GenSigSendType" SG_ 1016 HLR_FlHz_Freigabe_HL 3;
BA_ "GenSigSwitchedByIgnition" SG_ 1016 HLR_FlHz_Freigabe_HL 0;
BA_ "GenSigSendType" SG_ 1016 HLR_FlHz_Freigabe_HR 3;
BA_ "GenSigSwitchedByIgnition" SG_ 1016 HLR_FlHz_Freigabe_HR 0;
BA_ "GenSigSendType" SG_ 1016 HLR_FlHz_Freigabe_Ruhesitz 3;
BA_ "GenSigSwitchedByIgnition" SG_ 1016 HLR_FlHz_Freigabe_Ruhesitz 0;
BA_ "GenSigSendType" SG_ 1016 HLR_FlHz_Freigabe_VL 3;
BA_ "GenSigSwitchedByIgnition" SG_ 1016 HLR_FlHz_Freigabe_VL 0;
BA_ "GenSigSendType" SG_ 1016 HLR_FlHz_Freigabe_VR 3;
BA_ "GenSigSwitchedByIgnition" SG_ 1016 HLR_FlHz_Freigabe_VR 0;
BA_ "GenSigSendType" SG_ 1016 HLR_FSH_Freigabe 3;
BA_ "GenSigSwitchedByIgnition" SG_ 1016 HLR_FSH_Freigabe 0;
BA_ "Fehlerwert" SG_ 1016 HLR_FSH_Freigabe 63;
BA_ "GenSigSendType" SG_ 1016 HLR_HSH_Freigabe 3;
BA_ "GenSigSwitchedByIgnition" SG_ 1016 HLR_HSH_Freigabe 0;
BA_ "GenSigSendType" SG_ 1016 HLR_KRH_Freigabe_VL 3;
BA_ "GenSigSwitchedByIgnition" SG_ 1016 HLR_KRH_Freigabe_VL 0;
BA_ "GenSigSendType" SG_ 1016 HLR_KRH_Freigabe_VR 3;
BA_ "GenSigSwitchedByIgnition" SG_ 1016 HLR_KRH_Freigabe_VR 0;
BA_ "GenSigSendType" SG_ 1016 HLR_LRH_Freigabe 3;
BA_ "GenSigSwitchedByIgnition" SG_ 1016 HLR_LRH_Freigabe 0;
BA_ "GenSigSendType" SG_ 1016 HLR_PTC_Freigabe 3;
BA_ "GenSigStartValue" SG_ 1016 HLR_PTC_Freigabe 3;
BA_ "GenSigSwitchedByIgnition" SG_ 1016 HLR_PTC_Freigabe 0;
BA_ "GenSigSendType" SG_ 1016 HLR_PTC_linear_Freigabe 3;
BA_ "GenSigSwitchedByIgnition" SG_ 1016 HLR_PTC_linear_Freigabe 0;
BA_ "Fehlerwert" SG_ 1016 HLR_PTC_linear_Freigabe 63;
BA_ "GenSigSendType" SG_ 1016 HLR_SIH_Freigabe_Fond 3;
BA_ "GenSigSwitchedByIgnition" SG_ 1016 HLR_SIH_Freigabe_Fond 0;
BA_ "GenSigSendType" SG_ 1016 HLR_SIH_Freigabe_HL 3;
BA_ "GenSigSwitchedByIgnition" SG_ 1016 HLR_SIH_Freigabe_HL 0;
BA_ "GenSigSendType" SG_ 1016 HLR_SIH_Freigabe_HR 3;
BA_ "GenSigSwitchedByIgnition" SG_ 1016 HLR_SIH_Freigabe_HR 0;
BA_ "GenSigSendType" SG_ 1016 HLR_SIH_Freigabe_VL 3;
BA_ "GenSigSwitchedByIgnition" SG_ 1016 HLR_SIH_Freigabe_VL 0;
BA_ "GenSigSendType" SG_ 1016 HLR_SIH_Freigabe_VR 3;
BA_ "GenSigSwitchedByIgnition" SG_ 1016 HLR_SIH_Freigabe_VR 0;
BA_ "GenSigSendType" SG_ 1016 HLR_SIL_Freigabe_HL 3;
BA_ "GenSigSwitchedByIgnition" SG_ 1016 HLR_SIL_Freigabe_HL 0;
BA_ "GenSigSendType" SG_ 1016 HLR_SIL_Freigabe_HR 3;
BA_ "GenSigSwitchedByIgnition" SG_ 1016 HLR_SIL_Freigabe_HR 0;
BA_ "GenSigSendType" SG_ 1016 HLR_SIL_Freigabe_VL 3;
BA_ "GenSigSwitchedByIgnition" SG_ 1016 HLR_SIL_Freigabe_VL 0;
BA_ "GenSigSendType" SG_ 1016 HLR_SIL_Freigabe_VR 3;
BA_ "GenSigSwitchedByIgnition" SG_ 1016 HLR_SIL_Freigabe_VR 0;
BA_ "GenSigSendType" SG_ 1016 HLR_Sp_Heizung_Freigabe_BT 3;
BA_ "GenSigSwitchedByIgnition" SG_ 1016 HLR_Sp_Heizung_Freigabe_BT 0;
BA_ "GenSigSendType" SG_ 1016 HLR_Sp_Heizung_Freigabe_FT 3;
BA_ "GenSigSwitchedByIgnition" SG_ 1016 HLR_Sp_Heizung_Freigabe_FT 0;
BA_ "GenSigSendType" SG_ 1016 HLR_TCH_Freigabe 3;
BA_ "GenSigSwitchedByIgnition" SG_ 1016 HLR_TCH_Freigabe 0;
BA_ "GenSigSendType" SG_ 1412 HSP_01_BZ 0;
BA_ "GenSigFuncType" SG_ 1412 HSP_01_BZ 1;
BA_ "GenSigSwitchedByIgnition" SG_ 1412 HSP_01_BZ 0;
BA_ "GenSigSendType" SG_ 1412 HSP_01_CRC 0;
BA_ "GenSigFuncType" SG_ 1412 HSP_01_CRC 2;
BA_ "GenSigSwitchedByIgnition" SG_ 1412 HSP_01_CRC 0;
BA_ "GenSigSendType" SG_ 1412 HSP_BAP_Messages 0;
BA_ "GenSigSwitchedByIgnition" SG_ 1412 HSP_BAP_Messages 0;
BA_ "GenSigSendType" SG_ 1412 HSP_Charisma_FahrPr 0;
BA_ "GenSigSwitchedByIgnition" SG_ 1412 HSP_Charisma_FahrPr 0;
BA_ "GenSigSendType" SG_ 1412 HSP_Charisma_Status 0;
BA_ "GenSigSwitchedByIgnition" SG_ 1412 HSP_Charisma_Status 0;
BA_ "GenSigSendType" SG_ 1412 HSP_def 0;
BA_ "GenSigSwitchedByIgnition" SG_ 1412 HSP_def 0;
BA_ "Fehlerwert" SG_ 1412 HSP_def 1;
BA_ "GenSigSendType" SG_ 1412 HSP_Endlage_ausgefahren 0;
BA_ "GenSigSwitchedByIgnition" SG_ 1412 HSP_Endlage_ausgefahren 0;
BA_ "GenSigSendType" SG_ 1412 HSP_Endlage_eingefahren 0;
BA_ "GenSigSwitchedByIgnition" SG_ 1412 HSP_Endlage_eingefahren 0;
BA_ "GenSigSendType" SG_ 1412 HSP_ErrorGueltigkeit_1 0;
BA_ "GenSigSwitchedByIgnition" SG_ 1412 HSP_ErrorGueltigkeit_1 0;
BA_ "GenSigSendType" SG_ 1412 HSP_ErrorGueltigkeit_2 0;
BA_ "GenSigSwitchedByIgnition" SG_ 1412 HSP_ErrorGueltigkeit_2 0;
BA_ "GenSigSendType" SG_ 1412 HSP_Komponentensteuerung 0;
BA_ "GenSigSwitchedByIgnition" SG_ 1412 HSP_Komponentensteuerung 0;
BA_ "GenSigSendType" SG_ 1412 HSP_LED_Error 0;
BA_ "GenSigSwitchedByIgnition" SG_ 1412 HSP_LED_Error 0;
BA_ "Fehlerwert" SG_ 1412 HSP_LED_Error 1;
BA_ "GenSigSendType" SG_ 1412 HSP_Lokalaktiv 0;
BA_ "GenSigSwitchedByIgnition" SG_ 1412 HSP_Lokalaktiv 0;
BA_ "GenSigSendType" SG_ 1412 HSP_man_Betaet_nicht_zulaessig 0;
BA_ "GenSigSwitchedByIgnition" SG_ 1412 HSP_man_Betaet_nicht_zulaessig 0;
BA_ "GenSigSendType" SG_ 1412 HSP_Motor_def 0;
BA_ "GenSigSwitchedByIgnition" SG_ 1412 HSP_Motor_def 0;
BA_ "Fehlerwert" SG_ 1412 HSP_Motor_def 1;
BA_ "GenSigSendType" SG_ 1412 HSP_Motor_Temp_Text 0;
BA_ "GenSigSwitchedByIgnition" SG_ 1412 HSP_Motor_Temp_Text 0;
BA_ "GenSigSendType" SG_ 1412 HSP_ResponseError 0;
BA_ "GenSigSwitchedByIgnition" SG_ 1412 HSP_ResponseError 0;
BA_ "Fehlerwert" SG_ 1412 HSP_ResponseError 1;
BA_ "GenSigSendType" SG_ 1412 HSP_Spielschutz 0;
BA_ "GenSigSwitchedByIgnition" SG_ 1412 HSP_Spielschutz 0;
BA_ "GenSigSendType" SG_ 1412 HSP_Spoiler_Error 0;
BA_ "GenSigSwitchedByIgnition" SG_ 1412 HSP_Spoiler_Error 0;
BA_ "GenSigSendType" SG_ 1412 HSP_Status_LED 0;
BA_ "GenSigSwitchedByIgnition" SG_ 1412 HSP_Status_LED 0;
BA_ "GenSigSendType" SG_ 1412 HSP_Taster 0;
BA_ "GenSigSwitchedByIgnition" SG_ 1412 HSP_Taster 0;
BA_ "GenSigSendType" SG_ 1412 HSP_Taster_Error 0;
BA_ "GenSigSwitchedByIgnition" SG_ 1412 HSP_Taster_Error 0;
BA_ "GenSigSendType" SG_ 1412 HSP_Ueberspannung 0;
BA_ "GenSigSwitchedByIgnition" SG_ 1412 HSP_Ueberspannung 0;
BA_ "Fehlerwert" SG_ 1412 HSP_Ueberspannung 1;
BA_ "GenSigSendType" SG_ 1412 HSP_Unterspannung 0;
BA_ "GenSigSwitchedByIgnition" SG_ 1412 HSP_Unterspannung 0;
BA_ "Fehlerwert" SG_ 1412 HSP_Unterspannung 1;
BA_ "GenSigSendType" SG_ 1412 HSP_Warnung_LED 0;
BA_ "GenSigSwitchedByIgnition" SG_ 1412 HSP_Warnung_LED 0;
BA_ "GenSigSendType" SG_ 1412 HSP_Warnung_Text 0;
BA_ "GenSigSwitchedByIgnition" SG_ 1412 HSP_Warnung_Text 0;
BA_ "GenSigSendType" SG_ 1412 HSP_Warnung_Ton 0;
BA_ "GenSigSwitchedByIgnition" SG_ 1412 HSP_Warnung_Ton 0;
BA_ "GenSigSendType" SG_ 1283 HV_Bordnetz_aktiv 3;
BA_ "GenSigSwitchedByIgnition" SG_ 1283 HV_Bordnetz_aktiv 0;
BA_ "GenSigSendType" SG_ 1283 HV_Bordnetz_Fehler 3;
BA_ "GenSigSwitchedByIgnition" SG_ 1283 HV_Bordnetz_Fehler 0;
BA_ "Fehlerwert" SG_ 1283 HV_Bordnetz_Fehler 1;
BA_ "GenSigSendType" SG_ 1283 HVK_01_BZ 0;
BA_ "GenSigFuncType" SG_ 1283 HVK_01_BZ 1;
BA_ "GenSigSwitchedByIgnition" SG_ 1283 HVK_01_BZ 0;
BA_ "GenSigSendType" SG_ 1283 HVK_01_CRC 0;
BA_ "GenSigFuncType" SG_ 1283 HVK_01_CRC 2;
BA_ "GenSigSwitchedByIgnition" SG_ 1283 HVK_01_CRC 0;
BA_ "GenSigSendType" SG_ 1283 HVK_AIAD_Sollmodus_2 3;
BA_ "GenSigSwitchedByIgnition" SG_ 1283 HVK_AIAD_Sollmodus_2 0;
BA_ "GenSigSendType" SG_ 1283 HVK_AktiveEntladung_Anf 3;
BA_ "GenSigSwitchedByIgnition" SG_ 1283 HVK_AktiveEntladung_Anf 0;
BA_ "GenSigSendType" SG_ 1283 HVK_BMS_Sollmodus 3;
BA_ "GenSigStartValue" SG_ 1283 HVK_BMS_Sollmodus 7;
BA_ "GenSigSwitchedByIgnition" SG_ 1283 HVK_BMS_Sollmodus 0;
BA_ "GenSigSendType" SG_ 1283 HVK_DCDC_EKK_Sollmodus 0;
BA_ "GenSigStartValue" SG_ 1283 HVK_DCDC_EKK_Sollmodus 3;
BA_ "GenSigSwitchedByIgnition" SG_ 1283 HVK_DCDC_EKK_Sollmodus 0;
BA_ "GenSigSendType" SG_ 1283 HVK_DCDC_Sollmodus 3;
BA_ "GenSigStartValue" SG_ 1283 HVK_DCDC_Sollmodus 7;
BA_ "GenSigSwitchedByIgnition" SG_ 1283 HVK_DCDC_Sollmodus 0;
BA_ "GenSigSendType" SG_ 1283 HVK_EKK_Sollmodus 3;
BA_ "GenSigStartValue" SG_ 1283 HVK_EKK_Sollmodus 7;
BA_ "GenSigSwitchedByIgnition" SG_ 1283 HVK_EKK_Sollmodus 0;
BA_ "GenSigSendType" SG_ 1283 HVK_Gesamtst_Spgfreiheit 0;
BA_ "GenSigSwitchedByIgnition" SG_ 1283 HVK_Gesamtst_Spgfreiheit 0;
BA_ "Fehlerwert" SG_ 1283 HVK_Gesamtst_Spgfreiheit 3;
BA_ "GenSigSendType" SG_ 1283 HVK_HV_Netz_Warnungen 3;
BA_ "GenSigSwitchedByIgnition" SG_ 1283 HVK_HV_Netz_Warnungen 0;
BA_ "GenSigSendType" SG_ 1283 HVK_HVLM_Sollmodus 3;
BA_ "GenSigStartValue" SG_ 1283 HVK_HVLM_Sollmodus 7;
BA_ "GenSigSwitchedByIgnition" SG_ 1283 HVK_HVLM_Sollmodus 0;
BA_ "GenSigSendType" SG_ 1283 HVK_HVPTC_Sollmodus 3;
BA_ "GenSigStartValue" SG_ 1283 HVK_HVPTC_Sollmodus 7;
BA_ "GenSigSwitchedByIgnition" SG_ 1283 HVK_HVPTC_Sollmodus 0;
BA_ "GenSigSendType" SG_ 1283 HVK_Iso_Messung_Start 3;
BA_ "GenSigSwitchedByIgnition" SG_ 1283 HVK_Iso_Messung_Start 0;
BA_ "GenSigSendType" SG_ 1283 HVK_Istmodus_Anf 3;
BA_ "GenSigSwitchedByIgnition" SG_ 1283 HVK_Istmodus_Anf 0;
BA_ "GenSigSendType" SG_ 1283 HVK_MO_EmSollzustand 3;
BA_ "GenSigStartValue" SG_ 1283 HVK_MO_EmSollzustand 255;
BA_ "GenSigSwitchedByIgnition" SG_ 1283 HVK_MO_EmSollzustand 0;
BA_ "GenSigSendType" SG_ 1283 HVK_TN1_Sollmodus 3;
BA_ "GenSigStartValue" SG_ 1283 HVK_TN1_Sollmodus 3;
BA_ "GenSigSwitchedByIgnition" SG_ 1283 HVK_TN1_Sollmodus 0;
BA_ "GenSigSendType" SG_ 1340 HVLM_04_BZ 0;
BA_ "GenSigFuncType" SG_ 1340 HVLM_04_BZ 1;
BA_ "GenSigSwitchedByIgnition" SG_ 1340 HVLM_04_BZ 0;
BA_ "GenSigSendType" SG_ 1340 HVLM_04_CRC 0;
BA_ "GenSigFuncType" SG_ 1340 HVLM_04_CRC 2;
BA_ "GenSigSwitchedByIgnition" SG_ 1340 HVLM_04_CRC 0;
BA_ "GenSigSendType" SG_ 1340 HVLM_Anf_Ladescreen 0;
BA_ "GenSigSwitchedByIgnition" SG_ 1340 HVLM_Anf_Ladescreen 0;
BA_ "GenSigSendType" SG_ 1340 HVLM_Anforderung_HMS 0;
BA_ "GenSigSwitchedByIgnition" SG_ 1340 HVLM_Anforderung_HMS 0;
BA_ "GenSigSendType" SG_ 1340 HVLM_AWC_Sollmodus 0;
BA_ "GenSigSwitchedByIgnition" SG_ 1340 HVLM_AWC_Sollmodus 0;
BA_ "Fehlerwert" SG_ 1340 HVLM_AWC_Sollmodus 7;
BA_ "GenSigSendType" SG_ 1340 HVLM_Fehlerstatus 0;
BA_ "GenSigStartValue" SG_ 1340 HVLM_Fehlerstatus 7;
BA_ "GenSigSwitchedByIgnition" SG_ 1340 HVLM_Fehlerstatus 0;
BA_ "GenSigSendType" SG_ 1340 HVLM_HV_Anf 0;
BA_ "GenSigSwitchedByIgnition" SG_ 1340 HVLM_HV_Anf 0;
BA_ "GenSigSendType" SG_ 1340 HVLM_HVEM_MaxLeistung 0;
BA_ "GenSigStartValue" SG_ 1340 HVLM_HVEM_MaxLeistung 510;
BA_ "GenSigSwitchedByIgnition" SG_ 1340 HVLM_HVEM_MaxLeistung 0;
BA_ "Fehlerwert" SG_ 1340 HVLM_HVEM_MaxLeistung 511;
BA_ "GenSigSendType" SG_ 1340 HVLM_IstModus_02 0;
BA_ "GenSigStartValue" SG_ 1340 HVLM_IstModus_02 2;
BA_ "GenSigSwitchedByIgnition" SG_ 1340 HVLM_IstModus_02 0;
BA_ "Fehlerwert" SG_ 1340 HVLM_IstModus_02 3;
BA_ "GenSigSendType" SG_ 1340 HVLM_LadeAnforderung 0;
BA_ "GenSigStartValue" SG_ 1340 HVLM_LadeAnforderung 6;
BA_ "GenSigSwitchedByIgnition" SG_ 1340 HVLM_LadeAnforderung 0;
BA_ "Fehlerwert" SG_ 1340 HVLM_LadeAnforderung 7;
BA_ "GenSigSendType" SG_ 1340 HVLM_Ladeart 0;
BA_ "GenSigSwitchedByIgnition" SG_ 1340 HVLM_Ladeart 0;
BA_ "GenSigSendType" SG_ 1340 HVLM_MaxBatLadestromHV 0;
BA_ "GenSigStartValue" SG_ 1340 HVLM_MaxBatLadestromHV 254;
BA_ "GenSigSwitchedByIgnition" SG_ 1340 HVLM_MaxBatLadestromHV 0;
BA_ "Fehlerwert" SG_ 1340 HVLM_MaxBatLadestromHV 255;
BA_ "GenSigSendType" SG_ 1340 HVLM_Parken_beibehalten_HMS 0;
BA_ "GenSigStartValue" SG_ 1340 HVLM_Parken_beibehalten_HMS 2;
BA_ "GenSigSwitchedByIgnition" SG_ 1340 HVLM_Parken_beibehalten_HMS 0;
BA_ "Fehlerwert" SG_ 1340 HVLM_Parken_beibehalten_HMS 3;
BA_ "GenSigSendType" SG_ 1340 HVLM_Standklima_Timer_Status 0;
BA_ "GenSigSwitchedByIgnition" SG_ 1340 HVLM_Standklima_Timer_Status 0;
BA_ "GenSigSendType" SG_ 1340 HVLM_Status_Netz 0;
BA_ "GenSigSwitchedByIgnition" SG_ 1340 HVLM_Status_Netz 0;
BA_ "GenSigSendType" SG_ 1340 HVLM_Status_Tankklappe 0;
BA_ "GenSigStartValue" SG_ 1340 HVLM_Status_Tankklappe 2;
BA_ "GenSigSwitchedByIgnition" SG_ 1340 HVLM_Status_Tankklappe 0;
BA_ "Fehlerwert" SG_ 1340 HVLM_Status_Tankklappe 3;
BA_ "GenSigSendType" SG_ 1340 HVLM_Stecker_Status 0;
BA_ "GenSigSwitchedByIgnition" SG_ 1340 HVLM_Stecker_Status 0;
BA_ "GenSigSendType" SG_ 1340 HVLM_STH_Betriebsmodus 0;
BA_ "GenSigStartValue" SG_ 1340 HVLM_STH_Betriebsmodus 6;
BA_ "GenSigSwitchedByIgnition" SG_ 1340 HVLM_STH_Betriebsmodus 0;
BA_ "Fehlerwert" SG_ 1340 HVLM_STH_Betriebsmodus 7;
BA_ "GenSigSendType" SG_ 1340 HVLM_VK_Modus 0;
BA_ "GenSigSwitchedByIgnition" SG_ 1340 HVLM_VK_Modus 0;
BA_ "Fehlerwert" SG_ 1340 HVLM_VK_Modus 3;
BA_ "GenSigSendType" SG_ 1340 HVLM_VK_STH_Einsatz 0;
BA_ "GenSigStartValue" SG_ 1340 HVLM_VK_STH_Einsatz 6;
BA_ "GenSigSwitchedByIgnition" SG_ 1340 HVLM_VK_STH_Einsatz 0;
BA_ "Fehlerwert" SG_ 1340 HVLM_VK_STH_Einsatz 7;
BA_ "GenSigSendType" SG_ 1524 AMB_Charisma_FahrPr 3;
BA_ "GenSigSwitchedByIgnition" SG_ 1524 AMB_Charisma_FahrPr 0;
BA_ "GenSigSendType" SG_ 1524 AMB_Charisma_Status 3;
BA_ "GenSigSwitchedByIgnition" SG_ 1524 AMB_Charisma_Status 0;
BA_ "GenSigSendType" SG_ 1524 BCM1_DI_Rampe_Innenlicht 3;
BA_ "GenSigSwitchedByIgnition" SG_ 1524 BCM1_DI_Rampe_Innenlicht 0;
BA_ "GenSigSendType" SG_ 1524 BCM1_DI_Rampe_Leselicht 3;
BA_ "GenSigSwitchedByIgnition" SG_ 1524 BCM1_DI_Rampe_Leselicht 0;
BA_ "GenSigSendType" SG_ 1524 BCM1_Innenlicht_gedimmt_H 3;
BA_ "GenSigSwitchedByIgnition" SG_ 1524 BCM1_Innenlicht_gedimmt_H 0;
BA_ "GenSigSendType" SG_ 1524 BCM1_Innenlicht_gedimmt_V 3;
BA_ "GenSigSwitchedByIgnition" SG_ 1524 BCM1_Innenlicht_gedimmt_V 0;
BA_ "GenSigSendType" SG_ 1524 BCM1_Innenlicht_H 3;
BA_ "GenSigSwitchedByIgnition" SG_ 1524 BCM1_Innenlicht_H 0;
BA_ "GenSigSendType" SG_ 1524 BCM1_Innenlicht_V 3;
BA_ "GenSigSwitchedByIgnition" SG_ 1524 BCM1_Innenlicht_V 0;
BA_ "GenSigSendType" SG_ 1524 BCM1_Leselicht_Anf_hl 3;
BA_ "GenSigSwitchedByIgnition" SG_ 1524 BCM1_Leselicht_Anf_hl 0;
BA_ "GenSigSendType" SG_ 1524 BCM1_Leselicht_Anf_hr 3;
BA_ "GenSigSwitchedByIgnition" SG_ 1524 BCM1_Leselicht_Anf_hr 0;
BA_ "GenSigSendType" SG_ 1524 BCM1_Leselicht_Anf_vl 3;
BA_ "GenSigSwitchedByIgnition" SG_ 1524 BCM1_Leselicht_Anf_vl 0;
BA_ "GenSigSendType" SG_ 1524 BCM1_Leselicht_Anf_vr 3;
BA_ "GenSigSwitchedByIgnition" SG_ 1524 BCM1_Leselicht_Anf_vr 0;
BA_ "GenSigSendType" SG_ 1524 BCM1_Leuchten_Aus 3;
BA_ "GenSigSwitchedByIgnition" SG_ 1524 BCM1_Leuchten_Aus 0;
BA_ "GenSigSendType" SG_ 1524 IL_Bel_BFS_Ausstieg 3;
BA_ "GenSigSwitchedByIgnition" SG_ 1524 IL_Bel_BFS_Ausstieg 0;
BA_ "GenSigSendType" SG_ 1524 IL_Bel_FS_Ausstieg 3;
BA_ "GenSigSwitchedByIgnition" SG_ 1524 IL_Bel_FS_Ausstieg 0;
BA_ "GenSigSendType" SG_ 1524 IL_Bel_HBFS_Ausstieg 3;
BA_ "GenSigSwitchedByIgnition" SG_ 1524 IL_Bel_HBFS_Ausstieg 0;
BA_ "GenSigSendType" SG_ 1524 IL_Bel_HFS_Ausstieg 3;
BA_ "GenSigSwitchedByIgnition" SG_ 1524 IL_Bel_HFS_Ausstieg 0;
BA_ "GenSigSendType" SG_ 1524 IL_Dimmung_H_Tuerkontur 3;
BA_ "GenSigSwitchedByIgnition" SG_ 1524 IL_Dimmung_H_Tuerkontur 0;
BA_ "GenSigSendType" SG_ 1524 IL_Dimmung_Lautspr 3;
BA_ "GenSigSwitchedByIgnition" SG_ 1524 IL_Dimmung_Lautspr 0;
BA_ "GenSigSendType" SG_ 1524 IL_Dimmung_Tuerinnengriff 3;
BA_ "GenSigSwitchedByIgnition" SG_ 1524 IL_Dimmung_Tuerinnengriff 0;
BA_ "GenSigSendType" SG_ 1524 IL_Dimmung_Umfeldbel 3;
BA_ "GenSigSwitchedByIgnition" SG_ 1524 IL_Dimmung_Umfeldbel 0;
BA_ "GenSigSendType" SG_ 1524 IL_Dimmung_V_Tuerkontur 3;
BA_ "GenSigSwitchedByIgnition" SG_ 1524 IL_Dimmung_V_Tuerkontur 0;
BA_ "GenSigSendType" SG_ 1524 IL_Innenlicht_aktiv 3;
BA_ "GenSigStartValue" SG_ 1524 IL_Innenlicht_aktiv 1;
BA_ "GenSigSwitchedByIgnition" SG_ 1524 IL_Innenlicht_aktiv 0;
BA_ "GenSigSendType" SG_ 1524 IL_Klemme_30G_aktiv 3;
BA_ "GenSigSwitchedByIgnition" SG_ 1524 IL_Klemme_30G_aktiv 0;
BA_ "GenSigSendType" SG_ 312 IPA_01_BZ 0;
BA_ "GenSigFuncType" SG_ 312 IPA_01_BZ 1;
BA_ "GenSigSwitchedByIgnition" SG_ 312 IPA_01_BZ 0;
BA_ "GenSigSendType" SG_ 312 IPA_01_CRC 0;
BA_ "GenSigFuncType" SG_ 312 IPA_01_CRC 2;
BA_ "GenSigSwitchedByIgnition" SG_ 312 IPA_01_CRC 0;
BA_ "GenSigSendType" SG_ 312 IPA_Anforderung_HMS 0;
BA_ "GenSigSwitchedByIgnition" SG_ 312 IPA_Anforderung_HMS 0;
BA_ "GenSigSendType" SG_ 312 IPA_APS_LED 3;
BA_ "GenSigStartValue" SG_ 312 IPA_APS_LED 6;
BA_ "GenSigSendType" SG_ 312 IPA_Fahrstufenwunsch 0;
BA_ "GenSigSendType" SG_ 312 IPA_Parken_beibehalten_HMS 0;
BA_ "GenSigStartValue" SG_ 312 IPA_Parken_beibehalten_HMS 2;
BA_ "Fehlerwert" SG_ 312 IPA_Parken_beibehalten_HMS 3;
BA_ "GenSigSendType" SG_ 312 IPA_PLA_LED 3;
BA_ "GenSigStartValue" SG_ 312 IPA_PLA_LED 6;
BA_ "GenSigSendType" SG_ 312 IPA_Sollbeschleunigung 0;
BA_ "GenSigSendType" SG_ 312 IPA_Status 3;
BA_ "GenSigSwitchedByIgnition" SG_ 312 IPA_Status 0;
BA_ "GenSigSendType" SG_ 312 IPA_Status_IPA_GE 0;
BA_ "Fehlerwert" SG_ 312 IPA_Status_IPA_GE 7;
BA_ "GenSigSendType" SG_ 312 IPA_Status_IPA_TSK 3;
BA_ "GenSigStartValue" SG_ 312 IPA_Status_IPA_TSK 1;
BA_ "GenSigSendType" SG_ 312 Parken_aktives_System 3;
BA_ "GenSigSendType" SG_ 312 Parken_erhoehtes_Moment 0;
BA_ "GenSigSwitchedByIgnition" SG_ 312 Parken_erhoehtes_Moment 0;
BA_ "GenSigSendType" SG_ 312 Parken_Fahrbereitschaft_Anf 3;
BA_ "GenSigSendType" SG_ 312 Parken_Motorlauf_Anf 3;
BA_ "GenSigActiveRepetitions" SG_ 2527679583 Parken_Aktivierungslicht_Anf 5;
BA_ "GenSigSendType" SG_ 2527679583 Parken_Aktivierungslicht_Anf 4;
BA_ "GenSigSwitchedByIgnition" SG_ 2527679583 Parken_Aktivierungslicht_Anf 0;
BA_ "GenSigActiveRepetitions" SG_ 2527679583 Parken_Bestaetigungsblinken_Anf 5;
BA_ "GenSigSendType" SG_ 2527679583 Parken_Bestaetigungsblinken_Anf 4;
BA_ "GenSigSwitchedByIgnition" SG_ 2527679583 Parken_Bestaetigungsblinken_Anf 0;
BA_ "GenSigActiveRepetitions" SG_ 2527679583 Parken_Fahrbereitschaftlicht_Anf 5;
BA_ "GenSigSendType" SG_ 2527679583 Parken_Fahrbereitschaftlicht_Anf 4;
BA_ "GenSigActiveRepetitions" SG_ 2527679583 Parken_Fahrerhinweise_Anf 5;
BA_ "GenSigSendType" SG_ 2527679583 Parken_Fahrerhinweise_Anf 4;
BA_ "GenSigSwitchedByIgnition" SG_ 2527679583 Parken_Fahrerhinweise_Anf 0;
BA_ "GenSigActiveRepetitions" SG_ 2527679583 Parken_Fahrtrichtungslicht_Anf 5;
BA_ "GenSigSendType" SG_ 2527679583 Parken_Fahrtrichtungslicht_Anf 4;
BA_ "GenSigActiveRepetitions" SG_ 2527679583 Parken_FFB_LED_Anf 5;
BA_ "GenSigSendType" SG_ 2527679583 Parken_FFB_LED_Anf 4;
BA_ "GenSigActiveRepetitions" SG_ 2527679583 Parken_Lichtnachlauf_Anf 5;
BA_ "GenSigSendType" SG_ 2527679583 Parken_Lichtnachlauf_Anf 4;
BA_ "GenSigActiveRepetitions" SG_ 2527679583 Parken_Schluesselsuche_Anf 5;
BA_ "GenSigSendType" SG_ 2527679583 Parken_Schluesselsuche_Anf 4;
BA_ "GenSigActiveRepetitions" SG_ 2527679583 Parken_Seitenspiegel_Anf 5;
BA_ "GenSigSendType" SG_ 2527679583 Parken_Seitenspiegel_Anf 4;
BA_ "GenSigActiveRepetitions" SG_ 2527679583 Parken_Wegfahrsperren_Anf 5;
BA_ "GenSigSendType" SG_ 2527679583 Parken_Wegfahrsperren_Anf 4;
BA_ "GenSigActiveRepetitions" SG_ 2527679583 Parken_ZR_Sondermodus_Anf 5;
BA_ "GenSigSendType" SG_ 2527679583 Parken_ZR_Sondermodus_Anf 4;
BA_ "GenSigSwitchedByIgnition" SG_ 2527679583 Parken_ZR_Sondermodus_Anf 0;
BA_ "GenSigActiveRepetitions" SG_ 2527679583 Parken_ZV_Schliessen 5;
BA_ "GenSigSendType" SG_ 2527679583 Parken_ZV_Schliessen 4;
BA_ "GenSigSendType" SG_ 1903 ISO_AMP_Req_Data 3;
BA_ "GenSigFuncType" SG_ 1903 ISO_AMP_Req_Data 9;
BA_ "GenSigSwitchedByIgnition" SG_ 1903 ISO_AMP_Req_Data 0;
BA_ "GenSigSendType" SG_ 2009 ISO_AMP_Resp_Data 3;
BA_ "GenSigFuncType" SG_ 2009 ISO_AMP_Resp_Data 9;
BA_ "GenSigSwitchedByIgnition" SG_ 2009 ISO_AMP_Resp_Data 0;
BA_ "GenSigSendType" SG_ 1792 ISO_ALL_01_Req_Data 3;
BA_ "GenSigFuncType" SG_ 1792 ISO_ALL_01_Req_Data 9;
BA_ "GenSigSwitchedByIgnition" SG_ 1792 ISO_ALL_01_Req_Data 0;
BA_REL_ "GenSigTimeoutTime" BU_SG_REL_ BedienDisp_vo SG_ 705 EFP_Status_Taster_Fahrwerk 800;
BA_REL_ "GenSigTimeoutTime" BU_SG_REL_ BedienSG_hi SG_ 1016 HLR_SIH_Freigabe_Fond 5000;
BA_REL_ "GenSigTimeoutTime" BU_SG_REL_ BedienSG_hi SG_ 1016 HLR_SIH_Freigabe_HL 5000;
BA_REL_ "GenSigTimeoutTime" BU_SG_REL_ BedienSG_hi SG_ 1016 HLR_SIH_Freigabe_HR 5000;
BA_REL_ "GenSigTimeoutTime" BU_SG_REL_ DDA SG_ 173 GE_Fahrstufe 5000;
BA_REL_ "GenSigTimeoutTime" BU_SG_REL_ DDA SG_ 312 Parken_aktives_System 2000;
BA_REL_ "GenSigTimeoutTime" BU_SG_REL_ DDA SG_ 2527679583 Parken_ZR_Sondermodus_Anf 5000;
BA_REL_ "GenSigTimeoutTime" BU_SG_REL_ OTA_FC SG_ 705 EFP_Status_Taster_Lift 800;
BA_REL_ "GenSigTimeoutTime" BU_SG_REL_ OTA_FC SG_ 705 EFP_Status_Taster_Fahrwerk 800;
BA_REL_ "GenSigTimeoutTime" BU_SG_REL_ OTA_FC SG_ 1605 ISP_Dimmung_ASP_02 5000;
BA_REL_ "GenSigTimeoutTime" BU_SG_REL_ OTA_FC SG_ 173 GE_Fahrstufe 5000;
BA_REL_ "GenSigTimeoutTime" BU_SG_REL_ OTA_FC SG_ 173 GE_Zielgang 5000;
BA_REL_ "GenSigTimeoutTime" BU_SG_REL_ OTA_FC SG_ 968 GE_LaunchControl 2000;
BA_REL_ "GenSigTimeoutTime" BU_SG_REL_ OTA_FC SG_ 968 GE_Sumpftemperatur 2000;
BA_REL_ "GenSigTimeoutTime" BU_SG_REL_ OTA_FC SG_ 177 GE_Fahrprogramm 5000;
BA_REL_ "GenSigTimeoutTime" BU_SG_REL_ OTA_FC SG_ 177 GE_Getriebestatus_02 5000;
BA_REL_ "GenSigTimeoutTime" BU_SG_REL_ OTA_FC SG_ 891 GNSS_UTC_Zeit 5000;
BA_REL_ "GenSigTimeoutTime" BU_SG_REL_ OTA_FC SG_ 891 GNSS_Empfaenger_Status 5000;
BA_REL_ "GenSigTimeoutTime" BU_SG_REL_ OTA_FC SG_ 1412 HSP_Endlage_eingefahren 2000;
BA_REL_ "GenSigTimeoutTime" BU_SG_REL_ OTA_FC SG_ 1412 HSP_Endlage_ausgefahren 2000;
BA_REL_ "GenSigTimeoutTime" BU_SG_REL_ OTA_FC SG_ 1283 HV_Bordnetz_aktiv 1000;
BA_REL_ "GenSigTimeoutTime" BU_SG_REL_ OTA_FC SG_ 1340 HVLM_Ladeart 1000;
BA_REL_ "GenSigTimeoutTime" BU_SG_REL_ OTA_FC SG_ 1340 HVLM_VK_Modus 1000;
BA_REL_ "GenSigTimeoutTime" BU_SG_REL_ OTA_FC SG_ 1340 HVLM_IstModus_02 1000;
BA_REL_ "GenSigTimeoutTime" BU_SG_REL_ OTA_FC SG_ 1340 HVLM_Fehlerstatus 1000;
BA_REL_ "GenSigTimeoutTime" BU_SG_REL_ OTA_FC SG_ 1340 HVLM_Parken_beibehalten_HMS 1000;
BA_REL_ "GenSigTimeoutTime" BU_SG_REL_ OTA_FC SG_ 1340 HVLM_Stecker_Status 1000;
BA_REL_ "GenSigTimeoutTime" BU_SG_REL_ ZR_High SG_ 2463978619 FAS_SollStatus_Fkt_ASW 5000;
BA_REL_ "GenSigTimeoutTime" BU_SG_REL_ ZR_High SG_ 2463978619 FAS_SollStatus_Fkt_SWA 5000;
BA_REL_ "GenSigTimeoutTime" BU_SG_REL_ ZR_High SG_ 2463978619 FAS_SollStatus_Fkt_MKE 5000;
BA_REL_ "GenSigTimeoutTime" BU_SG_REL_ ZR_High SG_ 2463978619 FAS_SollStatus_Fkt_NV 5000;
BA_REL_ "GenSigTimeoutTime" BU_SG_REL_ ZR_High SG_ 2463978619 FAS_SollStatus_Fkt_AbstWarn_MV 5000;
BA_REL_ "GenSigTimeoutTime" BU_SG_REL_ ZR_High SG_ 2463978619 FAS_SollStatus_Fkt_STP 5000;
BA_REL_ "GenSigTimeoutTime" BU_SG_REL_ ZR_High SG_ 2463978619 FAS_SollStatus_Fkt_PreCrash 5000;
BA_REL_ "GenSigTimeoutTime" BU_SG_REL_ ZR_High SG_ 2463978619 FAS_SollStatus_Fkt_LGI 5000;
BA_REL_ "GenSigTimeoutTime" BU_SG_REL_ ZR_High SG_ 2527679660 FB_Fahrerwechsel 3200;
BA_REL_ "GenSigTimeoutTime" BU_SG_REL_ ZR_High SG_ 2527679660 FB_Fehler 3200;
BA_REL_ "GenSigTimeoutTime" BU_SG_REL_ ZR_High SG_ 2527679660 FB_Muedigkeit_Guete 3200;
BA_REL_ "GenSigTimeoutTime" BU_SG_REL_ ZR_High SG_ 2527679660 FB_Muedigkeit_Index 3200;
BA_REL_ "GenSigTimeoutTime" BU_SG_REL_ ZR_High SG_ 707 FDR_M_HL_02 800;
BA_REL_ "GenSigTimeoutTime" BU_SG_REL_ ZR_High SG_ 707 FDR_M_HR_02 800;
BA_REL_ "GenSigTimeoutTime" BU_SG_REL_ ZR_High SG_ 707 FDR_M_VL_02 800;
BA_REL_ "GenSigTimeoutTime" BU_SG_REL_ ZR_High SG_ 707 FDR_M_VR_02 800;
BA_REL_ "GenSigTimeoutTime" BU_SG_REL_ ZR_High SG_ 1605 FLA_ISP_defekt 5000;
BA_REL_ "GenSigTimeoutTime" BU_SG_REL_ ZR_High SG_ 1605 FLA_Sensor_blockiert 5000;
BA_REL_ "GenSigTimeoutTime" BU_SG_REL_ ZR_High SG_ 1605 FLA_Abblendursache 5000;
BA_REL_ "GenSigTimeoutTime" BU_SG_REL_ ZR_High SG_ 2589283684 FoD_Transmission_Info 5000;
BA_REL_ "GenSigTimeoutTime" BU_SG_REL_ ZR_High SG_ 173 GE_Fahrstufe 5000;
BA_REL_ "GenSigTimeoutTime" BU_SG_REL_ ZR_High SG_ 173 GE_Zielgang 5000;
BA_REL_ "GenSigTimeoutTime" BU_SG_REL_ ZR_High SG_ 968 GE_Sumpftemperatur 2000;
BA_REL_ "GenSigTimeoutTime" BU_SG_REL_ ZR_High SG_ 177 GE_Fahrprogramm 5000;
BA_REL_ "GenSigTimeoutTime" BU_SG_REL_ ZR_High SG_ 177 GE_TippZustand 5000;
BA_REL_ "GenSigTimeoutTime" BU_SG_REL_ ZR_High SG_ 879 GNSS_Nachrichtenpaket_ID1 5000;
BA_REL_ "GenSigTimeoutTime" BU_SG_REL_ ZR_High SG_ 879 GNSS_Breite_Ortung 5000;
BA_REL_ "GenSigTimeoutTime" BU_SG_REL_ ZR_High SG_ 879 GNSS_Richtung_Breite_Ortung 5000;
BA_REL_ "GenSigTimeoutTime" BU_SG_REL_ ZR_High SG_ 879 GNSS_Laenge_Ortung 5000;
BA_REL_ "GenSigTimeoutTime" BU_SG_REL_ ZR_High SG_ 879 GNSS_Richtung_Laenge_Ortung 5000;
BA_REL_ "GenSigTimeoutTime" BU_SG_REL_ ZR_High SG_ 879 GNSS_Ortung_FIX_Typ 5000;
BA_REL_ "GenSigTimeoutTime" BU_SG_REL_ ZR_High SG_ 879 GNSS_Fehlerzustand 5000;
BA_REL_ "GenSigTimeoutTime" BU_SG_REL_ ZR_High SG_ 884 GNSS_Nachrichtenpaket_ID2 5000;
BA_REL_ "GenSigTimeoutTime" BU_SG_REL_ ZR_High SG_ 884 GNSS_Ortung_Latenz 5000;
BA_REL_ "GenSigTimeoutTime" BU_SG_REL_ ZR_High SG_ 884 GNSS_Ortung_Ausrichtung 5000;
BA_REL_ "GenSigTimeoutTime" BU_SG_REL_ ZR_High SG_ 884 GNSS_Ortung_2D_Geschw_ue_Grund 5000;
BA_REL_ "GenSigTimeoutTime" BU_SG_REL_ ZR_High SG_ 884 GNSS_Ortung_Noerdliche_Geschw 5000;
BA_REL_ "GenSigTimeoutTime" BU_SG_REL_ ZR_High SG_ 884 GNSS_Ortung_Oestliche_Geschw 5000;
BA_REL_ "GenSigTimeoutTime" BU_SG_REL_ ZR_High SG_ 884 GNSS_Ortung_Vertikale_Geschw 5000;
BA_REL_ "GenSigTimeoutTime" BU_SG_REL_ ZR_High SG_ 886 GNSS_Nachrichtenpaket_ID3 5000;
BA_REL_ "GenSigTimeoutTime" BU_SG_REL_ ZR_High SG_ 886 GNSS_Ortung_GDOP 5000;
BA_REL_ "GenSigTimeoutTime" BU_SG_REL_ ZR_High SG_ 886 GNSS_Ortung_PDOP 5000;
BA_REL_ "GenSigTimeoutTime" BU_SG_REL_ ZR_High SG_ 886 GNSS_Ortung_HDOP 5000;
BA_REL_ "GenSigTimeoutTime" BU_SG_REL_ ZR_High SG_ 886 GNSS_Ortung_VDOP 5000;
BA_REL_ "GenSigTimeoutTime" BU_SG_REL_ ZR_High SG_ 886 GNSS_Ortung_Guete_Geschwindigk 5000;
BA_REL_ "GenSigTimeoutTime" BU_SG_REL_ ZR_High SG_ 886 GNSS_Ortung_Guete_Ausrichtung 5000;
BA_REL_ "GenSigTimeoutTime" BU_SG_REL_ ZR_High SG_ 886 GNSS_Ortung_Guete_horizontal 5000;
BA_REL_ "GenSigTimeoutTime" BU_SG_REL_ ZR_High SG_ 886 GNSS_Ortung_Guete_vertikal 5000;
BA_REL_ "GenSigTimeoutTime" BU_SG_REL_ ZR_High SG_ 888 GNSS_Nachrichtenpaket_ID4 5000;
BA_REL_ "GenSigTimeoutTime" BU_SG_REL_ ZR_High SG_ 888 GNSS_Ortung_Zeit_in_GPSWoche 5000;
BA_REL_ "GenSigTimeoutTime" BU_SG_REL_ ZR_High SG_ 888 GNSS_Ortung_Hoehe 5000;
BA_REL_ "GenSigTimeoutTime" BU_SG_REL_ ZR_High SG_ 891 GNSS_UTC_Zeit 5000;
BA_REL_ "GenSigTimeoutTime" BU_SG_REL_ ZR_High SG_ 891 GNSS_Empfaenger_Status 5000;
BA_REL_ "GenSigTimeoutTime" BU_SG_REL_ ZR_High SG_ 891 GNSS_GPS_in_Nutzung 5000;
BA_REL_ "GenSigTimeoutTime" BU_SG_REL_ ZR_High SG_ 891 GNSS_GLONASS_in_Nutzung 5000;
BA_REL_ "GenSigTimeoutTime" BU_SG_REL_ ZR_High SG_ 891 GNSS_Empfangbare_Satelliten 5000;
BA_REL_ "GenSigTimeoutTime" BU_SG_REL_ ZR_High SG_ 891 GNSS_Sichtbare_Satelliten 5000;
BA_REL_ "GenSigTimeoutTime" BU_SG_REL_ ZR_High SG_ 891 GNSS_Genutzte_Satelliten 5000;
BA_REL_ "GenSigTimeoutTime" BU_SG_REL_ ZR_High SG_ 891 GNSS_Nachrichtenpaket_ID5 5000;
BA_REL_ "GenSigTimeoutTime" BU_SG_REL_ ZR_High SG_ 1364 GNSS_Sat_Info_Sat_ID_1 5000;
BA_REL_ "GenSigTimeoutTime" BU_SG_REL_ ZR_High SG_ 1364 GNSS_Sat_Info_SNR_ID_1 5000;
BA_REL_ "GenSigTimeoutTime" BU_SG_REL_ ZR_High SG_ 1364 GNSS_Sat_Info_Azimuth_ID_1 5000;
BA_REL_ "GenSigTimeoutTime" BU_SG_REL_ ZR_High SG_ 1364 GNSS_Sat_Info_Hoehenwinkel_ID_1 5000;
BA_REL_ "GenSigTimeoutTime" BU_SG_REL_ ZR_High SG_ 1364 GNSS_Nachrichtenpaket_ID6 5000;
BA_REL_ "GenSigTimeoutTime" BU_SG_REL_ ZR_High SG_ 299 GRA_Hauptschalter 2000;
BA_REL_ "GenSigTimeoutTime" BU_SG_REL_ ZR_High SG_ 299 GRA_Abbrechen 2000;
BA_REL_ "GenSigTimeoutTime" BU_SG_REL_ ZR_High SG_ 299 GRA_Typ_Hauptschalter 2000;
BA_REL_ "GenSigTimeoutTime" BU_SG_REL_ ZR_High SG_ 299 GRA_Limiter 2000;
BA_REL_ "GenSigTimeoutTime" BU_SG_REL_ ZR_High SG_ 299 GRA_Tip_Setzen 2000;
BA_REL_ "GenSigTimeoutTime" BU_SG_REL_ ZR_High SG_ 299 GRA_Tip_Hoch 2000;
BA_REL_ "GenSigTimeoutTime" BU_SG_REL_ ZR_High SG_ 299 GRA_Tip_Runter 2000;
BA_REL_ "GenSigTimeoutTime" BU_SG_REL_ ZR_High SG_ 299 GRA_Tip_Wiederaufnahme 2000;
BA_REL_ "GenSigTimeoutTime" BU_SG_REL_ ZR_High SG_ 299 GRA_Verstellung_Zeitluecke 2000;
BA_REL_ "GenSigTimeoutTime" BU_SG_REL_ ZR_High SG_ 299 GRA_Codierung 2000;
BA_REL_ "GenSigTimeoutTime" BU_SG_REL_ ZR_High SG_ 299 GRA_Fehler 2000;
BA_REL_ "GenSigTimeoutTime" BU_SG_REL_ ZR_High SG_ 299 GRA_LIM_Taste_verfuegbar 2000;
BA_REL_ "GenSigTimeoutTime" BU_SG_REL_ ZR_High SG_ 299 GRA_Tip_Stufe_2 2000;
BA_REL_ "GenSigTimeoutTime" BU_SG_REL_ ZR_High SG_ 299 GRA_Typ_Bedienteil 2000;
BA_REL_ "GenSigTimeoutTime" BU_SG_REL_ ZR_High SG_ 1410 HD_Endstellung_oben 2000;
BA_REL_ "GenSigTimeoutTime" BU_SG_REL_ ZR_High SG_ 1410 HD_Endstellung_unten 2000;
BA_REL_ "GenSigTimeoutTime" BU_SG_REL_ ZR_High SG_ 1410 HD_Bewegung_auf 2000;
BA_REL_ "GenSigTimeoutTime" BU_SG_REL_ ZR_High SG_ 1410 HD_Bewegung_zu 2000;
BA_REL_ "GenSigTimeoutTime" BU_SG_REL_ ZR_High SG_ 1410 HD_Innentaster_betaetigt 2000;
BA_REL_ "GenSigTimeoutTime" BU_SG_REL_ ZR_High SG_ 1410 HD_UeKB_erkannt 2000;
BA_REL_ "GenSigTimeoutTime" BU_SG_REL_ ZR_High SG_ 1410 HD_Position 2000;
BA_REL_ "GenSigTimeoutTime" BU_SG_REL_ ZR_High SG_ 1410 HD_Taster_defekt 2000;
BA_REL_ "GenSigTimeoutTime" BU_SG_REL_ ZR_High SG_ 1410 HD_Verriegelungstaster_betaetigt 2000;
BA_REL_ "GenSigTimeoutTime" BU_SG_REL_ ZR_High SG_ 1416 FSH_LED 5000;
BA_REL_ "GenSigTimeoutTime" BU_SG_REL_ ZR_High SG_ 1416 HSH_LED 5000;
BA_REL_ "GenSigTimeoutTime" BU_SG_REL_ ZR_High SG_ 1416 HLR_SIH_Freigabe_Fond 5000;
BA_REL_ "GenSigTimeoutTime" BU_SG_REL_ ZR_High SG_ 1016 HLR_FlHz_Freigabe_Ruhesitz 5000;
BA_REL_ "GenSigTimeoutTime" BU_SG_REL_ ZR_High SG_ 1016 HLR_FlHz_Freigabe_VR 5000;
BA_REL_ "GenSigTimeoutTime" BU_SG_REL_ ZR_High SG_ 1016 HLR_FlHz_Freigabe_VL 5000;
BA_REL_ "GenSigTimeoutTime" BU_SG_REL_ ZR_High SG_ 1016 HLR_FlHz_Freigabe_HR 5000;
BA_REL_ "GenSigTimeoutTime" BU_SG_REL_ ZR_High SG_ 1016 HLR_FlHz_Freigabe_HL 5000;
BA_REL_ "GenSigTimeoutTime" BU_SG_REL_ ZR_High SG_ 1016 HLR_TCH_Freigabe 5000;
BA_REL_ "GenSigTimeoutTime" BU_SG_REL_ ZR_High SG_ 1016 HLR_SIH_Freigabe_Fond 5000;
BA_REL_ "GenSigTimeoutTime" BU_SG_REL_ ZR_High SG_ 1016 HLR_Sp_Heizung_Freigabe_BT 5000;
BA_REL_ "GenSigTimeoutTime" BU_SG_REL_ ZR_High SG_ 1016 HLR_Sp_Heizung_Freigabe_FT 5000;
BA_REL_ "GenSigTimeoutTime" BU_SG_REL_ ZR_High SG_ 1016 HLR_KRH_Freigabe_VL 5000;
BA_REL_ "GenSigTimeoutTime" BU_SG_REL_ ZR_High SG_ 1016 HLR_KRH_Freigabe_VR 5000;
BA_REL_ "GenSigTimeoutTime" BU_SG_REL_ ZR_High SG_ 1016 HLR_SIH_Freigabe_VL 5000;
BA_REL_ "GenSigTimeoutTime" BU_SG_REL_ ZR_High SG_ 1016 HLR_SIH_Freigabe_VR 5000;
BA_REL_ "GenSigTimeoutTime" BU_SG_REL_ ZR_High SG_ 1016 HLR_SIH_Freigabe_HL 5000;
BA_REL_ "GenSigTimeoutTime" BU_SG_REL_ ZR_High SG_ 1016 HLR_SIH_Freigabe_HR 5000;
BA_REL_ "GenSigTimeoutTime" BU_SG_REL_ ZR_High SG_ 1016 HLR_SIL_Freigabe_VL 5000;
BA_REL_ "GenSigTimeoutTime" BU_SG_REL_ ZR_High SG_ 1016 HLR_SIL_Freigabe_VR 5000;
BA_REL_ "GenSigTimeoutTime" BU_SG_REL_ ZR_High SG_ 1016 HLR_SIL_Freigabe_HL 5000;
BA_REL_ "GenSigTimeoutTime" BU_SG_REL_ ZR_High SG_ 1016 HLR_SIL_Freigabe_HR 5000;
BA_REL_ "GenSigTimeoutTime" BU_SG_REL_ ZR_High SG_ 1016 HLR_FSH_Freigabe 5000;
BA_REL_ "GenSigTimeoutTime" BU_SG_REL_ ZR_High SG_ 1016 HLR_HSH_Freigabe 5000;
BA_REL_ "GenSigTimeoutTime" BU_SG_REL_ ZR_High SG_ 1016 HLR_LRH_Freigabe 5000;
BA_REL_ "GenSigTimeoutTime" BU_SG_REL_ ZR_High SG_ 1283 HVK_BMS_Sollmodus 1000;
BA_REL_ "GenSigTimeoutTime" BU_SG_REL_ ZR_High SG_ 1283 HVK_HV_Netz_Warnungen 1000;
BA_REL_ "GenSigTimeoutTime" BU_SG_REL_ ZR_High SG_ 1283 HV_Bordnetz_Fehler 1000;
BA_REL_ "GenSigTimeoutTime" BU_SG_REL_ ZR_High SG_ 1283 HVK_Gesamtst_Spgfreiheit 1000;
BA_REL_ "GenSigTimeoutTime" BU_SG_REL_ ZR_High SG_ 1340 HVLM_STH_Betriebsmodus 1000;
BA_REL_ "GenSigTimeoutTime" BU_SG_REL_ ZR_High SG_ 1340 HVLM_Standklima_Timer_Status 1000;
BA_REL_ "GenSigTimeoutTime" BU_SG_REL_ ZR_High SG_ 1340 HVLM_Status_Netz 1000;
BA_REL_ "GenSigTimeoutTime" BU_SG_REL_ ZR_High SG_ 1340 HVLM_Ladeart 1000;
BA_REL_ "GenSigTimeoutTime" BU_SG_REL_ ZR_High SG_ 1340 HVLM_VK_STH_Einsatz 1000;
BA_REL_ "GenSigTimeoutTime" BU_SG_REL_ ZR_High SG_ 1340 HVLM_VK_Modus 1000;
BA_REL_ "GenSigTimeoutTime" BU_SG_REL_ ZR_High SG_ 1340 HVLM_IstModus_02 1000;
BA_REL_ "GenSigTimeoutTime" BU_SG_REL_ ZR_High SG_ 1340 HVLM_HV_Anf 1000;
BA_REL_ "GenSigTimeoutTime" BU_SG_REL_ ZR_High SG_ 1340 HVLM_Fehlerstatus 1000;
BA_REL_ "GenSigTimeoutTime" BU_SG_REL_ ZR_High SG_ 1340 HVLM_AWC_Sollmodus 1000;
BA_REL_ "GenSigTimeoutTime" BU_SG_REL_ ZR_High SG_ 1340 HVLM_Stecker_Status 1000;
BA_REL_ "GenSigTimeoutTime" BU_SG_REL_ ZR_High SG_ 1340 HVLM_LadeAnforderung 1000;
BA_REL_ "GenSigTimeoutTime" BU_SG_REL_ ZR_High SG_ 1524 IL_Dimmung_V_Tuerkontur 5000;
BA_REL_ "GenSigTimeoutTime" BU_SG_REL_ ZR_High SG_ 1524 IL_Dimmung_H_Tuerkontur 5000;
BA_REL_ "GenSigTimeoutTime" BU_SG_REL_ ZR_High SG_ 1524 IL_Dimmung_Tuerinnengriff 5000;
BA_REL_ "GenSigTimeoutTime" BU_SG_REL_ ZR_High SG_ 1524 IL_Dimmung_Umfeldbel 5000;
BA_REL_ "GenSigTimeoutTime" BU_SG_REL_ ZR_High SG_ 1524 IL_Bel_FS_Ausstieg 5000;
BA_REL_ "GenSigTimeoutTime" BU_SG_REL_ ZR_High SG_ 1524 IL_Bel_BFS_Ausstieg 5000;
BA_REL_ "GenSigTimeoutTime" BU_SG_REL_ ZR_High SG_ 1524 IL_Bel_HFS_Ausstieg 5000;
BA_REL_ "GenSigTimeoutTime" BU_SG_REL_ ZR_High SG_ 1524 IL_Bel_HBFS_Ausstieg 5000;
BA_REL_ "GenSigTimeoutTime" BU_SG_REL_ ZR_High SG_ 1524 BCM1_Innenlicht_gedimmt_V 5000;
BA_REL_ "GenSigTimeoutTime" BU_SG_REL_ ZR_High SG_ 1524 BCM1_Innenlicht_gedimmt_H 5000;
BA_REL_ "GenSigTimeoutTime" BU_SG_REL_ ZR_High SG_ 1524 IL_Innenlicht_aktiv 5000;
BA_REL_ "GenSigTimeoutTime" BU_SG_REL_ ZR_High SG_ 1524 BCM1_DI_Rampe_Innenlicht 5000;
BA_REL_ "GenSigTimeoutTime" BU_SG_REL_ ZR_High SG_ 1524 BCM1_DI_Rampe_Leselicht 5000;
BA_REL_ "GenSigTimeoutTime" BU_SG_REL_ ZR_High SG_ 1524 BCM1_Innenlicht_H 5000;
BA_REL_ "GenSigTimeoutTime" BU_SG_REL_ ZR_High SG_ 1524 BCM1_Innenlicht_V 5000;
BA_REL_ "GenSigTimeoutTime" BU_SG_REL_ ZR_High SG_ 1524 BCM1_Leselicht_Anf_hl 5000;
BA_REL_ "GenSigTimeoutTime" BU_SG_REL_ ZR_High SG_ 1524 BCM1_Leselicht_Anf_hr 5000;
BA_REL_ "GenSigTimeoutTime" BU_SG_REL_ ZR_High SG_ 1524 BCM1_Leselicht_Anf_vl 5000;
BA_REL_ "GenSigTimeoutTime" BU_SG_REL_ ZR_High SG_ 1524 BCM1_Leselicht_Anf_vr 5000;
BA_REL_ "GenSigTimeoutTime" BU_SG_REL_ ZR_High SG_ 1524 BCM1_Leuchten_Aus 5000;
BA_REL_ "GenSigTimeoutTime" BU_SG_REL_ ZR_High SG_ 1524 IL_Dimmung_Lautspr 5000;
BA_REL_ "GenSigTimeoutTime" BU_SG_REL_ ZR_High SG_ 312 IPA_Anforderung_HMS 2000;
BA_REL_ "GenSigTimeoutTime" BU_SG_REL_ ZR_High SG_ 312 Parken_aktives_System 2000;
BA_REL_ "GenSigTimeoutTime" BU_SG_REL_ ZR_High SG_ 2527679583 Parken_Seitenspiegel_Anf 5000;
BA_REL_ "GenSigTimeoutTime" BU_SG_REL_ ZR_High SG_ 2527679583 Parken_ZV_Schliessen 5000;
BA_REL_ "GenSigTimeoutTime" BU_SG_REL_ ZR_High SG_ 2527679583 Parken_ZR_Sondermodus_Anf 5000;
BA_REL_ "GenSigTimeoutTime" BU_SG_REL_ ZR_High SG_ 2527679583 Parken_Bestaetigungsblinken_Anf 5000;
BA_REL_ "GenSigTimeoutTime" BU_SG_REL_ ZR_LIMU SG_ 707 FDR_M_HL_02 800;
BA_REL_ "GenSigTimeoutTime" BU_SG_REL_ ZR_LIMU SG_ 707 FDR_M_HR_02 800;
BA_REL_ "GenSigTimeoutTime" BU_SG_REL_ ZR_LIMU SG_ 707 FDR_M_VL_02 800;
BA_REL_ "GenSigTimeoutTime" BU_SG_REL_ ZR_LIMU SG_ 707 FDR_M_VR_02 800;
BA_REL_ "GenSigTimeoutTime" BU_SG_REL_ ZR_LIMU SG_ 2589283684 FoD_Transmission_Info 5000;
BA_REL_ "GenSigTimeoutTime" BU_SG_REL_ ZR_LIMU SG_ 173 GE_Fahrstufe 5000;
BA_REL_ "GenSigTimeoutTime" BU_SG_REL_ ZR_LIMU SG_ 879 GNSS_Nachrichtenpaket_ID1 5000;
BA_REL_ "GenSigTimeoutTime" BU_SG_REL_ ZR_LIMU SG_ 879 GNSS_Breite_Ortung 5000;
BA_REL_ "GenSigTimeoutTime" BU_SG_REL_ ZR_LIMU SG_ 879 GNSS_Richtung_Breite_Ortung 5000;
BA_REL_ "GenSigTimeoutTime" BU_SG_REL_ ZR_LIMU SG_ 879 GNSS_Laenge_Ortung 5000;
BA_REL_ "GenSigTimeoutTime" BU_SG_REL_ ZR_LIMU SG_ 879 GNSS_Richtung_Laenge_Ortung 5000;
BA_REL_ "GenSigTimeoutTime" BU_SG_REL_ ZR_LIMU SG_ 879 GNSS_Ortung_FIX_Typ 5000;
BA_REL_ "GenSigTimeoutTime" BU_SG_REL_ ZR_LIMU SG_ 879 GNSS_Fehlerzustand 5000;
BA_REL_ "GenSigTimeoutTime" BU_SG_REL_ ZR_LIMU SG_ 884 GNSS_Nachrichtenpaket_ID2 5000;
BA_REL_ "GenSigTimeoutTime" BU_SG_REL_ ZR_LIMU SG_ 884 GNSS_Ortung_Latenz 5000;
BA_REL_ "GenSigTimeoutTime" BU_SG_REL_ ZR_LIMU SG_ 884 GNSS_Ortung_Ausrichtung 5000;
BA_REL_ "GenSigTimeoutTime" BU_SG_REL_ ZR_LIMU SG_ 884 GNSS_Ortung_2D_Geschw_ue_Grund 5000;
BA_REL_ "GenSigTimeoutTime" BU_SG_REL_ ZR_LIMU SG_ 884 GNSS_Ortung_Noerdliche_Geschw 5000;
BA_REL_ "GenSigTimeoutTime" BU_SG_REL_ ZR_LIMU SG_ 884 GNSS_Ortung_Oestliche_Geschw 5000;
BA_REL_ "GenSigTimeoutTime" BU_SG_REL_ ZR_LIMU SG_ 884 GNSS_Ortung_Vertikale_Geschw 5000;
BA_REL_ "GenSigTimeoutTime" BU_SG_REL_ ZR_LIMU SG_ 886 GNSS_Nachrichtenpaket_ID3 5000;
BA_REL_ "GenSigTimeoutTime" BU_SG_REL_ ZR_LIMU SG_ 886 GNSS_Ortung_GDOP 5000;
BA_REL_ "GenSigTimeoutTime" BU_SG_REL_ ZR_LIMU SG_ 886 GNSS_Ortung_PDOP 5000;
BA_REL_ "GenSigTimeoutTime" BU_SG_REL_ ZR_LIMU SG_ 886 GNSS_Ortung_HDOP 5000;
BA_REL_ "GenSigTimeoutTime" BU_SG_REL_ ZR_LIMU SG_ 886 GNSS_Ortung_VDOP 5000;
BA_REL_ "GenSigTimeoutTime" BU_SG_REL_ ZR_LIMU SG_ 886 GNSS_Ortung_Guete_Geschwindigk 5000;
BA_REL_ "GenSigTimeoutTime" BU_SG_REL_ ZR_LIMU SG_ 886 GNSS_Ortung_Guete_Ausrichtung 5000;
BA_REL_ "GenSigTimeoutTime" BU_SG_REL_ ZR_LIMU SG_ 886 GNSS_Ortung_Guete_horizontal 5000;
BA_REL_ "GenSigTimeoutTime" BU_SG_REL_ ZR_LIMU SG_ 886 GNSS_Ortung_Guete_vertikal 5000;
BA_REL_ "GenSigTimeoutTime" BU_SG_REL_ ZR_LIMU SG_ 888 GNSS_Nachrichtenpaket_ID4 5000;
BA_REL_ "GenSigTimeoutTime" BU_SG_REL_ ZR_LIMU SG_ 888 GNSS_Ortung_Zeit_in_GPSWoche 5000;
BA_REL_ "GenSigTimeoutTime" BU_SG_REL_ ZR_LIMU SG_ 888 GNSS_Ortung_Hoehe 5000;
BA_REL_ "GenSigTimeoutTime" BU_SG_REL_ ZR_LIMU SG_ 891 GNSS_UTC_Zeit 5000;
BA_REL_ "GenSigTimeoutTime" BU_SG_REL_ ZR_LIMU SG_ 891 GNSS_Empfaenger_Status 5000;
BA_REL_ "GenSigTimeoutTime" BU_SG_REL_ ZR_LIMU SG_ 891 GNSS_GPS_in_Nutzung 5000;
BA_REL_ "GenSigTimeoutTime" BU_SG_REL_ ZR_LIMU SG_ 891 GNSS_GLONASS_in_Nutzung 5000;
BA_REL_ "GenSigTimeoutTime" BU_SG_REL_ ZR_LIMU SG_ 891 GNSS_Empfangbare_Satelliten 5000;
BA_REL_ "GenSigTimeoutTime" BU_SG_REL_ ZR_LIMU SG_ 891 GNSS_Sichtbare_Satelliten 5000;
BA_REL_ "GenSigTimeoutTime" BU_SG_REL_ ZR_LIMU SG_ 891 GNSS_Genutzte_Satelliten 5000;
BA_REL_ "GenSigTimeoutTime" BU_SG_REL_ ZR_LIMU SG_ 891 GNSS_Nachrichtenpaket_ID5 5000;
BA_REL_ "GenSigTimeoutTime" BU_SG_REL_ ZR_LIMU SG_ 1364 GNSS_Sat_Info_Sat_ID_1 5000;
BA_REL_ "GenSigTimeoutTime" BU_SG_REL_ ZR_LIMU SG_ 1364 GNSS_Sat_Info_SNR_ID_1 5000;
BA_REL_ "GenSigTimeoutTime" BU_SG_REL_ ZR_LIMU SG_ 1364 GNSS_Sat_Info_Azimuth_ID_1 5000;
BA_REL_ "GenSigTimeoutTime" BU_SG_REL_ ZR_LIMU SG_ 1364 GNSS_Sat_Info_Hoehenwinkel_ID_1 5000;
BA_REL_ "GenSigTimeoutTime" BU_SG_REL_ ZR_LIMU SG_ 1364 GNSS_Nachrichtenpaket_ID6 5000;
BA_REL_ "GenSigTimeoutTime" BU_SG_REL_ ZR_LIMU SG_ 310 HAL_VZ_Radwinkel 1000;
BA_REL_ "GenSigTimeoutTime" BU_SG_REL_ ZR_LIMU SG_ 310 HAL_Radwinkel 1000;
BA_REL_ "GenSigTimeoutTime" BU_SG_REL_ ZR_LIMU SG_ 1340 HVLM_Anf_Ladescreen 1000;
BA_REL_ "GenSigTimeoutTime" BU_SG_REL_ ZR_LIMU SG_ 2527679583 Parken_ZR_Sondermodus_Anf 5000;
BA_REL_ "GenSigTimeoutTime" BU_SG_REL_ ZR_MIB_TOP_ab_Gen3 SG_ 2527679896 FA_FahrerAnf_Lift_Abwurf 3200;
BA_REL_ "GenSigTimeoutTime" BU_SG_REL_ ZR_MIB_TOP_ab_Gen3 SG_ 707 FDR_M_HL_02 800;
BA_REL_ "GenSigTimeoutTime" BU_SG_REL_ ZR_MIB_TOP_ab_Gen3 SG_ 707 FDR_M_HR_02 800;
BA_REL_ "GenSigTimeoutTime" BU_SG_REL_ ZR_MIB_TOP_ab_Gen3 SG_ 707 FDR_M_VL_02 800;
BA_REL_ "GenSigTimeoutTime" BU_SG_REL_ ZR_MIB_TOP_ab_Gen3 SG_ 707 FDR_M_VR_02 800;
BA_REL_ "GenSigTimeoutTime" BU_SG_REL_ ZR_MIB_TOP_ab_Gen3 SG_ 2589283684 FoD_Transmission_Info 5000;
BA_REL_ "GenSigTimeoutTime" BU_SG_REL_ ZR_MIB_TOP_ab_Gen3 SG_ 173 GE_Fahrstufe 5000;
BA_REL_ "GenSigTimeoutTime" BU_SG_REL_ ZR_MIB_TOP_ab_Gen3 SG_ 968 GE_Sumpftemperatur 2000;
BA_REL_ "GenSigTimeoutTime" BU_SG_REL_ ZR_MIB_TOP_ab_Gen3 SG_ 879 GNSS_Nachrichtenpaket_ID1 5000;
BA_REL_ "GenSigTimeoutTime" BU_SG_REL_ ZR_MIB_TOP_ab_Gen3 SG_ 879 GNSS_Breite_Ortung 5000;
BA_REL_ "GenSigTimeoutTime" BU_SG_REL_ ZR_MIB_TOP_ab_Gen3 SG_ 879 GNSS_Richtung_Breite_Ortung 5000;
BA_REL_ "GenSigTimeoutTime" BU_SG_REL_ ZR_MIB_TOP_ab_Gen3 SG_ 879 GNSS_Laenge_Ortung 5000;
BA_REL_ "GenSigTimeoutTime" BU_SG_REL_ ZR_MIB_TOP_ab_Gen3 SG_ 879 GNSS_Richtung_Laenge_Ortung 5000;
BA_REL_ "GenSigTimeoutTime" BU_SG_REL_ ZR_MIB_TOP_ab_Gen3 SG_ 879 GNSS_Ortung_FIX_Typ 5000;
BA_REL_ "GenSigTimeoutTime" BU_SG_REL_ ZR_MIB_TOP_ab_Gen3 SG_ 879 GNSS_Fehlerzustand 5000;
BA_REL_ "GenSigTimeoutTime" BU_SG_REL_ ZR_MIB_TOP_ab_Gen3 SG_ 884 GNSS_Nachrichtenpaket_ID2 5000;
BA_REL_ "GenSigTimeoutTime" BU_SG_REL_ ZR_MIB_TOP_ab_Gen3 SG_ 884 GNSS_Ortung_Latenz 5000;
BA_REL_ "GenSigTimeoutTime" BU_SG_REL_ ZR_MIB_TOP_ab_Gen3 SG_ 884 GNSS_Ortung_Ausrichtung 5000;
BA_REL_ "GenSigTimeoutTime" BU_SG_REL_ ZR_MIB_TOP_ab_Gen3 SG_ 884 GNSS_Ortung_2D_Geschw_ue_Grund 5000;
BA_REL_ "GenSigTimeoutTime" BU_SG_REL_ ZR_MIB_TOP_ab_Gen3 SG_ 884 GNSS_Ortung_Noerdliche_Geschw 5000;
BA_REL_ "GenSigTimeoutTime" BU_SG_REL_ ZR_MIB_TOP_ab_Gen3 SG_ 884 GNSS_Ortung_Oestliche_Geschw 5000;
BA_REL_ "GenSigTimeoutTime" BU_SG_REL_ ZR_MIB_TOP_ab_Gen3 SG_ 884 GNSS_Ortung_Vertikale_Geschw 5000;
BA_REL_ "GenSigTimeoutTime" BU_SG_REL_ ZR_MIB_TOP_ab_Gen3 SG_ 886 GNSS_Nachrichtenpaket_ID3 5000;
BA_REL_ "GenSigTimeoutTime" BU_SG_REL_ ZR_MIB_TOP_ab_Gen3 SG_ 886 GNSS_Ortung_GDOP 5000;
BA_REL_ "GenSigTimeoutTime" BU_SG_REL_ ZR_MIB_TOP_ab_Gen3 SG_ 886 GNSS_Ortung_PDOP 5000;
BA_REL_ "GenSigTimeoutTime" BU_SG_REL_ ZR_MIB_TOP_ab_Gen3 SG_ 886 GNSS_Ortung_HDOP 5000;
BA_REL_ "GenSigTimeoutTime" BU_SG_REL_ ZR_MIB_TOP_ab_Gen3 SG_ 886 GNSS_Ortung_VDOP 5000;
BA_REL_ "GenSigTimeoutTime" BU_SG_REL_ ZR_MIB_TOP_ab_Gen3 SG_ 886 GNSS_Ortung_Guete_Geschwindigk 5000;
BA_REL_ "GenSigTimeoutTime" BU_SG_REL_ ZR_MIB_TOP_ab_Gen3 SG_ 886 GNSS_Ortung_Guete_Ausrichtung 5000;
BA_REL_ "GenSigTimeoutTime" BU_SG_REL_ ZR_MIB_TOP_ab_Gen3 SG_ 886 GNSS_Ortung_Guete_horizontal 5000;
BA_REL_ "GenSigTimeoutTime" BU_SG_REL_ ZR_MIB_TOP_ab_Gen3 SG_ 886 GNSS_Ortung_Guete_vertikal 5000;
BA_REL_ "GenSigTimeoutTime" BU_SG_REL_ ZR_MIB_TOP_ab_Gen3 SG_ 888 GNSS_Nachrichtenpaket_ID4 5000;
BA_REL_ "GenSigTimeoutTime" BU_SG_REL_ ZR_MIB_TOP_ab_Gen3 SG_ 888 GNSS_Ortung_Zeit_in_GPSWoche 5000;
BA_REL_ "GenSigTimeoutTime" BU_SG_REL_ ZR_MIB_TOP_ab_Gen3 SG_ 888 GNSS_Ortung_Hoehe 5000;
BA_REL_ "GenSigTimeoutTime" BU_SG_REL_ ZR_MIB_TOP_ab_Gen3 SG_ 891 GNSS_UTC_Zeit 5000;
BA_REL_ "GenSigTimeoutTime" BU_SG_REL_ ZR_MIB_TOP_ab_Gen3 SG_ 891 GNSS_Empfaenger_Status 5000;
BA_REL_ "GenSigTimeoutTime" BU_SG_REL_ ZR_MIB_TOP_ab_Gen3 SG_ 891 GNSS_GPS_in_Nutzung 5000;
BA_REL_ "GenSigTimeoutTime" BU_SG_REL_ ZR_MIB_TOP_ab_Gen3 SG_ 891 GNSS_GLONASS_in_Nutzung 5000;
BA_REL_ "GenSigTimeoutTime" BU_SG_REL_ ZR_MIB_TOP_ab_Gen3 SG_ 891 GNSS_Empfangbare_Satelliten 5000;
BA_REL_ "GenSigTimeoutTime" BU_SG_REL_ ZR_MIB_TOP_ab_Gen3 SG_ 891 GNSS_Sichtbare_Satelliten 5000;
BA_REL_ "GenSigTimeoutTime" BU_SG_REL_ ZR_MIB_TOP_ab_Gen3 SG_ 891 GNSS_Genutzte_Satelliten 5000;
BA_REL_ "GenSigTimeoutTime" BU_SG_REL_ ZR_MIB_TOP_ab_Gen3 SG_ 891 GNSS_Nachrichtenpaket_ID5 5000;
BA_REL_ "GenSigTimeoutTime" BU_SG_REL_ ZR_MIB_TOP_ab_Gen3 SG_ 1364 GNSS_Sat_Info_Sat_ID_1 5000;
BA_REL_ "GenSigTimeoutTime" BU_SG_REL_ ZR_MIB_TOP_ab_Gen3 SG_ 1364 GNSS_Sat_Info_SNR_ID_1 5000;
BA_REL_ "GenSigTimeoutTime" BU_SG_REL_ ZR_MIB_TOP_ab_Gen3 SG_ 1364 GNSS_Sat_Info_Azimuth_ID_1 5000;
BA_REL_ "GenSigTimeoutTime" BU_SG_REL_ ZR_MIB_TOP_ab_Gen3 SG_ 1364 GNSS_Sat_Info_Hoehenwinkel_ID_1 5000;
BA_REL_ "GenSigTimeoutTime" BU_SG_REL_ ZR_MIB_TOP_ab_Gen3 SG_ 1364 GNSS_Nachrichtenpaket_ID6 5000;
BA_REL_ "GenSigTimeoutTime" BU_SG_REL_ ZR_MIB_TOP_ab_Gen3 SG_ 1340 HVLM_Anf_Ladescreen 1000;
BA_REL_ "GenSigTimeoutTime" BU_SG_REL_ ZR_MIB_TOP_ab_Gen3 SG_ 2527679583 Parken_ZR_Sondermodus_Anf 5000;
BA_REL_ "GenSigTimeoutTime" BU_SG_REL_ ZR_Standard SG_ 707 FDR_M_HL_02 800;
BA_REL_ "GenSigTimeoutTime" BU_SG_REL_ ZR_Standard SG_ 707 FDR_M_HR_02 800;
BA_REL_ "GenSigTimeoutTime" BU_SG_REL_ ZR_Standard SG_ 707 FDR_M_VL_02 800;
BA_REL_ "GenSigTimeoutTime" BU_SG_REL_ ZR_Standard SG_ 707 FDR_M_VR_02 800;
BA_REL_ "GenSigTimeoutTime" BU_SG_REL_ ZR_Standard SG_ 968 GE_Sumpftemperatur 2000;
BA_REL_ "GenSigTimeoutTime" BU_SG_REL_ ZR_Standard SG_ 879 GNSS_Nachrichtenpaket_ID1 5000;
BA_REL_ "GenSigTimeoutTime" BU_SG_REL_ ZR_Standard SG_ 879 GNSS_Breite_Ortung 5000;
BA_REL_ "GenSigTimeoutTime" BU_SG_REL_ ZR_Standard SG_ 879 GNSS_Richtung_Breite_Ortung 5000;
BA_REL_ "GenSigTimeoutTime" BU_SG_REL_ ZR_Standard SG_ 879 GNSS_Laenge_Ortung 5000;
BA_REL_ "GenSigTimeoutTime" BU_SG_REL_ ZR_Standard SG_ 879 GNSS_Richtung_Laenge_Ortung 5000;
BA_REL_ "GenSigTimeoutTime" BU_SG_REL_ ZR_Standard SG_ 879 GNSS_Ortung_FIX_Typ 5000;
BA_REL_ "GenSigTimeoutTime" BU_SG_REL_ ZR_Standard SG_ 879 GNSS_Fehlerzustand 5000;
BA_REL_ "GenSigTimeoutTime" BU_SG_REL_ ZR_Standard SG_ 884 GNSS_Nachrichtenpaket_ID2 5000;
BA_REL_ "GenSigTimeoutTime" BU_SG_REL_ ZR_Standard SG_ 884 GNSS_Ortung_Latenz 5000;
BA_REL_ "GenSigTimeoutTime" BU_SG_REL_ ZR_Standard SG_ 884 GNSS_Ortung_Ausrichtung 5000;
BA_REL_ "GenSigTimeoutTime" BU_SG_REL_ ZR_Standard SG_ 884 GNSS_Ortung_2D_Geschw_ue_Grund 5000;
BA_REL_ "GenSigTimeoutTime" BU_SG_REL_ ZR_Standard SG_ 884 GNSS_Ortung_Noerdliche_Geschw 5000;
BA_REL_ "GenSigTimeoutTime" BU_SG_REL_ ZR_Standard SG_ 884 GNSS_Ortung_Oestliche_Geschw 5000;
BA_REL_ "GenSigTimeoutTime" BU_SG_REL_ ZR_Standard SG_ 884 GNSS_Ortung_Vertikale_Geschw 5000;
BA_REL_ "GenSigTimeoutTime" BU_SG_REL_ ZR_Standard SG_ 886 GNSS_Nachrichtenpaket_ID3 5000;
BA_REL_ "GenSigTimeoutTime" BU_SG_REL_ ZR_Standard SG_ 886 GNSS_Ortung_GDOP 5000;
BA_REL_ "GenSigTimeoutTime" BU_SG_REL_ ZR_Standard SG_ 886 GNSS_Ortung_PDOP 5000;
BA_REL_ "GenSigTimeoutTime" BU_SG_REL_ ZR_Standard SG_ 886 GNSS_Ortung_HDOP 5000;
BA_REL_ "GenSigTimeoutTime" BU_SG_REL_ ZR_Standard SG_ 886 GNSS_Ortung_VDOP 5000;
BA_REL_ "GenSigTimeoutTime" BU_SG_REL_ ZR_Standard SG_ 886 GNSS_Ortung_Guete_Geschwindigk 5000;
BA_REL_ "GenSigTimeoutTime" BU_SG_REL_ ZR_Standard SG_ 886 GNSS_Ortung_Guete_Ausrichtung 5000;
BA_REL_ "GenSigTimeoutTime" BU_SG_REL_ ZR_Standard SG_ 886 GNSS_Ortung_Guete_horizontal 5000;
BA_REL_ "GenSigTimeoutTime" BU_SG_REL_ ZR_Standard SG_ 886 GNSS_Ortung_Guete_vertikal 5000;
BA_REL_ "GenSigTimeoutTime" BU_SG_REL_ ZR_Standard SG_ 888 GNSS_Nachrichtenpaket_ID4 5000;
BA_REL_ "GenSigTimeoutTime" BU_SG_REL_ ZR_Standard SG_ 888 GNSS_Ortung_Zeit_in_GPSWoche 5000;
BA_REL_ "GenSigTimeoutTime" BU_SG_REL_ ZR_Standard SG_ 888 GNSS_Ortung_Hoehe 5000;
BA_REL_ "GenSigTimeoutTime" BU_SG_REL_ ZR_Standard SG_ 891 GNSS_UTC_Zeit 5000;
BA_REL_ "GenSigTimeoutTime" BU_SG_REL_ ZR_Standard SG_ 891 GNSS_Empfaenger_Status 5000;
BA_REL_ "GenSigTimeoutTime" BU_SG_REL_ ZR_Standard SG_ 891 GNSS_GPS_in_Nutzung 5000;
BA_REL_ "GenSigTimeoutTime" BU_SG_REL_ ZR_Standard SG_ 891 GNSS_GLONASS_in_Nutzung 5000;
BA_REL_ "GenSigTimeoutTime" BU_SG_REL_ ZR_Standard SG_ 891 GNSS_Empfangbare_Satelliten 5000;
BA_REL_ "GenSigTimeoutTime" BU_SG_REL_ ZR_Standard SG_ 891 GNSS_Sichtbare_Satelliten 5000;
BA_REL_ "GenSigTimeoutTime" BU_SG_REL_ ZR_Standard SG_ 891 GNSS_Genutzte_Satelliten 5000;
BA_REL_ "GenSigTimeoutTime" BU_SG_REL_ ZR_Standard SG_ 891 GNSS_Nachrichtenpaket_ID5 5000;
BA_REL_ "GenSigTimeoutTime" BU_SG_REL_ ZR_Standard SG_ 1364 GNSS_Sat_Info_Sat_ID_1 5000;
BA_REL_ "GenSigTimeoutTime" BU_SG_REL_ ZR_Standard SG_ 1364 GNSS_Sat_Info_SNR_ID_1 5000;
BA_REL_ "GenSigTimeoutTime" BU_SG_REL_ ZR_Standard SG_ 1364 GNSS_Sat_Info_Azimuth_ID_1 5000;
BA_REL_ "GenSigTimeoutTime" BU_SG_REL_ ZR_Standard SG_ 1364 GNSS_Sat_Info_Hoehenwinkel_ID_1 5000;
BA_REL_ "GenSigTimeoutTime" BU_SG_REL_ ZR_Standard SG_ 1364 GNSS_Nachrichtenpaket_ID6 5000;
BA_REL_ "GenSigTimeoutTime" BU_SG_REL_ ZR_Standard SG_ 2527679583 Parken_ZR_Sondermodus_Anf 5000;
VAL_ 2527679896 EFP_ReifenTempOf_VL 63 "Init" ;
VAL_ 2527679896 EFP_ReifenTempOf_VR 63 "Init" ;
VAL_ 2527679896 EFP_ReifenTempOf_HL 63 "Init" ;
VAL_ 2527679896 EFP_ReifenTempOf_HR 63 "Init" ;
VAL_ 2527679896 FA_FahrerAnf_Lift_Abwurf 0 "KeinFahrerAnf_LiftAbwurf" 1 "FahrerAnf_LiftAbwurf" ;
VAL_ 2527679896 FA_Niveau_AOCCT_timer2_verbaut 0 "not_current" 1 "installed_and_coded" ;
VAL_ 2527679896 FA_Niveau_AOCCT_timer2_count 0 "inactiv" 1 "active" ;
VAL_ 2527679896 FA_Niveau_AOCCT_timer1_verbaut 0 "not_current" 1 "installed_and_coded" ;
VAL_ 2527679896 FA_Niveau_AOCCT_timer1_count 0 "inactive" 1 "active" ;
VAL_ 2527679896 FA_Niveau_AOCCT_teststatus 0 "diag_incomplete" 1 "diag_complete" ;
VAL_ 2527679896 FA_Niveau_AOCCT_fehlerstatus 0 "no_failure" 1 "failure" ;
VAL_ 2527679896 FA_Zuladung_VA 62 "Init" 63 "Fehler" ;
VAL_ 2527679896 FA_Zuladung_HA 62 "Init" 63 "Fehler" ;
VAL_ 2527679896 FA_Zuladung_Status_VA 0 "Berechnung_nicht_erfolgt" 1 "Berechnung_FehlertoleranzHoch" 2 "Berechnung_FehlertoleranzNiedrig" ;
VAL_ 2527679896 FA_Zuladung_Status_HA 0 "Berechnung_nicht_erfolgt" 1 "Berechnung_FehlertoleranzHoch" 2 "Berechnung_FehlertoleranzNiedrig" ;
VAL_ 705 EFP_Verbau_DR 0 "nicht_verbaut" 1 "verbaut" ;
VAL_ 705 EFP_Verbau_eAllrad 0 "nicht_verbaut" 1 "verbaut" ;
VAL_ 705 EFP_Verbau_LF 0 "nicht_verbaut" 1 "verbaut" ;
VAL_ 705 LF_Texte 0 "keine_Anzeige" 1 "Text_Fahrzeug_momentan_zu_tief_Regelung_laeuft" 2 "Text_Fahrzeug_momentan_zu_hoch_Regelung_laeuft" 3 "Text_Niveauregelung_abgeschaltet" ;
VAL_ 705 EFP_Verbau_eAWS 0 "nicht_verbaut" 1 "verbaut" ;
VAL_ 705 eAWS_Warnmeldung_Prio1 0 "keine_Anzeige" 1 "kritische_Fehlermeldung" ;
VAL_ 705 eAWS_Warnmeldung_Prio2 0 "keine_Anzeige" 1 "milde_Fehlermeldung" ;
VAL_ 705 LF_Texte_2 0 "Init" 1 "keine_Anzeige" 2 "Text_Fahrzeug_Anheben_angeforder" 3 "Text_Fahrzeug_Absenken_angeforde" 4 "reserviert" 5 "reserviert" 6 "reserviert" 7 "reserviert" 8 "reserviert" 9 "reserviert" 10 "reserviert" 11 "reserviert" 12 "reserviert" 13 "reserviert" 14 "reserviert" 15 "reserviert" ;
VAL_ 705 EFP_Status_Taster_Lift 0 "Keine_Anzeige" 1 "Status1" 2 "Status2" 3 "Status3" ;
VAL_ 705 EFP_Status_Taster_Fahrwerk 0 "Keine_Anzeige" 1 "Status1" 2 "Status2" 3 "Status3" ;
VAL_ 705 FDR_Warnung_ALR 0 "keine_Anzeige" 1 "Text_Stoerung_Allradverteilung" 2 "Text_Ausfall_Allradverteilung" 3 "reserved" ;
VAL_ 705 FDR_Warnung_TV 0 "keine_Anzeige" 1 "Text_Stoerung_TorqueVectoring" 2 "Text_Ausfall_TorqueVectoring" 3 "reserviert" ;
VAL_ 705 EFP_Verbau_eABC 0 "nicht_verbaut" 1 "verbaut" ;
VAL_ 705 LF_Warnung_Prio1_02 0 "keine_Anzeige" 1 "Text_Servicemodus" 2 "Text_Fehler_Luftfeder_Geschwindigkeit_1" 3 "Text_Fehler_Luftfeder_Geschwindigkeit_2" 4 "Text_Fehler_Luftfeder_Begrenzung_v_1" 5 "Text_Fehler_Luftfeder_Begrenzung_v_2" 6 "Text_Fehler_LuFe_Fzg_abstellen" ;
VAL_ 705 LF_Warnung_Prio1 0 "keine_Anzeige" 1 "Text_Servicemodus" 2 "Text_Fehler_Luftfeder_Geschwindigkeit_1" 3 "Text_Fehler_Luftfeder_Geschwindigkeit_2" ;
VAL_ 705 LF_Warnung_Prio2 0 "keine_Anzeige" 1 "Text_Fahrzeug_zu_tief_Bodenfreiheit_eingeschraenkt" 2 "Text_Fehler_Luftfeder" 3 "tbd" ;
VAL_ 705 eABC_Warnung_Prio2 0 "keine_Anzeige" 1 "Text_Stoerung_eABC_service_aufsuchen" 2 "Text_Stoerung_eABC_Bodenfreiheit_eingeschraenkt" 3 "Text_eABC_nicht_verfuegbar" ;
VAL_ 705 eABC_Warnung_Prio1 0 "keine_Anzeige" 1 "Text_Servicemodus" 2 "Text_Fehler_eABC_eingeschraenkte_Lenkbarkeit" 3 "Text_Fehler_eABC_eingeschraenkte_Fahrstabilitaet" 4 "Text_Fehler_eABC_eingeschraenkte_Geschwindigkeit" ;
VAL_ 705 eABC_Texte 0 "keine_Anzeige" 1 "Text_eABC_Vorausschau_nicht_verf" 2 "Text_eABC_Radwechselmodus" 3 "Text_eABC_Standfunktion_nicht_verfuegbar" 4 "Text_eABC_zur_Zeit_nicht_verfueg" 5 "Text_eABC_zur_Zeit_eingeschraenk" ;
VAL_ 705 DR_Warnung 0 "keine_Anzeige" 1 "Text_Fehler_Daempfer" ;
VAL_ 705 NR_LED_Offroadlevel 0 "LED_aus_und_Blinken_aus" 1 "LED_ein_und_Blinken_aus" 2 "LED_ein_und_Blinken_ein" 3 "Init" ;
VAL_ 705 NR_LED_Ladelevel 0 "LED_aus_und_Blinken_aus" 1 "LED_ein_und_Blinken_aus" 2 "LED_ein_und_Blinken_ein" 3 "Init" ;
VAL_ 705 NR_LED_Sync 0 "LED_aus_und_Blinken_aus" 1 "LED_ein_und_Blinken_aus" 2 "LED_ein_und_Blinken_ein" 3 "Init" ;
VAL_ 705 NR_LED_XtraLevel 0 "LED_aus_und_Blinken_aus" 1 "LED_ein_und_Blinken_aus" 2 "LED_ein_und_Blinken_ein" 3 "Init" ;
VAL_ 705 NR_LED_Strassenlevel 0 "LED_aus_und_Blinken_aus" 1 "LED_ein_und_Blinken_aus" 2 "LED_ein_und_Blinken_ein" 3 "Init" ;
VAL_ 705 EFP_Warnung_Naesse 0 "keine_Anzeige" 1 "Naesse_Meldung1" 2 "Naesse_Meldung2" 3 "Naesse_Meldung3" 4 "Naesse_Meldung4" 5 "Naesse_Meldung5" 6 "Naesse_Meldung6" 7 "Naesse_Meldung7" ;
VAL_ 705 EFP_Warnung_Naesse_verf 0 "verfuegbar" 1 "nicht_verfuegbar" ;
VAL_ 2463978619 FAS_SollStatus_Fkt_ASW 0 "Init" 1 "Funktion_ein" 2 "Funktion_aus" ;
VAL_ 2463978619 FAS_SollStatus_Fkt_SWA 0 "Init" 1 "Funktion_ein" 2 "Funktion_aus" ;
VAL_ 2463978619 FAS_SollStatus_Fkt_MKE 0 "Init" 1 "Funktion_ein" 2 "Funktion_aus" ;
VAL_ 2463978619 FAS_SollStatus_Fkt_NV 0 "Init" 1 "Funktion_ein" 2 "Funktion_aus" ;
VAL_ 2463978619 FAS_SollStatus_Fkt_AbstWarn_MV 0 "Init" 1 "Funktion_ein" 2 "Funktion_aus" ;
VAL_ 2463978619 FAS_SollStatus_Fkt_STP 0 "Init" 1 "Funktion_ein" 2 "Funktion_aus" ;
VAL_ 2463978619 FAS_SollStatus_Fkt_PreCrash 0 "Init" 1 "Funktion_ein" 2 "Funktion_aus" ;
VAL_ 2463978619 FAS_SollStatus_Fkt_LGI 0 "Init" 1 "Funktion_ein" 2 "Funktion_aus" ;
VAL_ 2463978619 FAS_SollStatus_Fkt_AbstWarn_LRR 0 "Init" 1 "Funktion_ein" 2 "Funktion_aus" ;
VAL_ 2527679660 FB_Kopfaktivitaet_A1 15 "Init" ;
VAL_ 2527679660 FB_Kopfaktivitaet_A2 15 "Init" ;
VAL_ 2527679660 FB_Blindheit 0 "nicht_erkannt" 1 "erkannt" ;
VAL_ 2527679660 FB_NichtVerfuegbar 0 "verfuegbar" 1 "nicht_verfuegbar" ;
VAL_ 2527679660 FB_Fahrerwechsel 0 "Fahrerwechsel_nicht_erkannt" 1 "Fahrerwechsel_erkannt" 3 "Init" ;
VAL_ 2527679660 FB_Fehler 0 "kein_Fehler" 1 "Fehler" ;
VAL_ 2527679660 FB_Muedigkeit_Index 255 "Init" ;
VAL_ 707 EFP_MomRad_Begr 4094 "Init" 4095 "Fehler" ;
VAL_ 707 FA_Warnung_Transportniveau 0 "keine_Anzeige" 1 "Warnung" ;
VAL_ 707 eAWS_Warnmeldung_Prio3 0 "keine_Anzeige" 1 "Hinweismeldung" ;
VAL_ 707 EFP_Anf_Kuehlklappenwarnung 0 "kein_Warnhinweis" 1 "Warnhinweis" ;
VAL_ 707 FDR_M_HL_02 252 "Darstellung_passiv" 253 "nicht_verbaut" 254 "Init" 255 "Fehler" ;
VAL_ 707 FDR_M_HR_02 252 "Darstellung_passiv" 253 "nicht_verbaut" 254 "Init" 255 "Fehler" ;
VAL_ 707 FDR_M_VL_02 252 "Darstellung_passiv" 253 "nicht_verbaut" 254 "Init" 255 "Fehler" ;
VAL_ 707 FDR_M_VR_02 252 "Darstellung_passiv" 253 "nicht_verbaut" 254 "Init" 255 "Fehler" ;
VAL_ 1605 FLA_aktiv 0 "inaktiv" 1 "aktiv" ;
VAL_ 1605 FLA_ISP_defekt 0 "iO" 1 "defekt" ;
VAL_ 1605 FLA_Sensor_blockiert 0 "Sensor in Ordnung" 1 "Sensor blockiert" ;
VAL_ 1605 FLA_Abblendursache 0 "nichts erkannt (Init-Wert) " 1 "enentgegenkommendes Fahrzeug (Scheinwerfer erkannt) " 2 "vorausfahrendes Fahrzeug (Heckleuchten erkannt) " 4 "Geschwindigkeitslimit unterschritten" 8 "Ortschaft_erkannt" 16 "Umgebungshelligkeit_generell_zu_hell" 32 "Nebel erkannt " 64 "Übertemperatur Imager" 128 "Verzögerungsbedingung" 255 "Fehler" ;
VAL_ 1605 FLA_Fernlicht_PWM 127 "Fehler" ;
VAL_ 1605 ISP_EC_Lichtwert_vorne 62 "Init" 63 "Fehler" ;
VAL_ 1605 ISP_EC_Lichtwert_hinten 62 "Init" 63 "Fehler" ;
VAL_ 1605 ISP_Himmelsrichtung 30 "nicht verfuegbar bzw. Init" 31 "Fehler" ;
VAL_ 1605 ISP_Taste_betaetigt 0 "nicht_betaetigt" 1 "betaetigt" ;
VAL_ 1605 ISP_EC_aktiv 0 "inaktiv" 1 "aktiv" ;
VAL_ 1605 ISP_Kompass_aktiv 0 "inaktiv" 1 "aktiv" ;
VAL_ 1605 FLA_Aufblenden 0 "nicht_aufblenden" 1 "aufblenden" ;
VAL_ 1605 FLA_SAE_Mode 0 "Init" 1 "FLA_Icon_invertiert" ;
VAL_ 2589283684 FoD_Transmission_Info 0 "Initwert" 1 "start_transmission" 2 "finish_transmission" ;
VAL_ 2589283684 FoD_Anz_Funktionsabschaltung 0 "Init" 1 "Popup_aufschalten" ;
VAL_ 173 GE_MMom_Soll_02 1022 "keine_Anforderung_Init" 1023 "Fehler" ;
VAL_ 173 GE_MMom_Vorhalt_02 1022 "Init" 1023 "Fehler" ;
VAL_ 173 GE_Uefkt 1023 "Fehler" ;
VAL_ 173 GE_Fahrstufe 0 "Zwischenstellung" 1 "Init" 5 "Position_P" 6 "Position_R" 7 "Position_N" 8 "Position_D" 9 "Position_S" 10 "Effizienz" 13 "Tipp_in_S" 14 "Tipp_in_D" 15 "Fehler" ;
VAL_ 173 GE_Schaltablauf 0 "keine_Schaltung" 1 "Momentenueberschneidung" 2 "Befuellphase" 3 "Drehzahlueberfuehrung" ;
VAL_ 173 GE_Uefkt_unplausibel 0 "Uefkt_plausibel" 1 "Uefkt_unplausibel" ;
VAL_ 173 GE_MMom_Status_02 0 "kein_Eingriff" 1 "abs_reduzierender_Eingriff_auf_Gesamt_Antrieb_nur_schneller_Pfad" 2 "abs_erhoehender_Eingriff_auf_Gesamt_Antrieb" 3 "relativer_Eingriff_auf_Gesamt_Antrieb" 4 "relativer_Eingriff_auf_E_Maschine" 5 "abs_red_Eingr_auf_Gesamt_Antrieb_nur_Luftpfad" 6 "abs_red_Eingr_auf_Gesamt_Antrieb_Luft-_und_schnellen_Pfad" 7 "abs_Eingriff_auf_Gesamtantrieb_erhoehend_und_reduzierend" ;
VAL_ 173 GE_Status_Kraftschluss 0 "offen_kein_Kraftschluss" 1 "offen_mit_Kraftschluss" 2 "schlupfend_geregelt" 3 "abgesichert_offen_kein_Kraftschl" 4 "geschlossen_mit_Mikroschlupf" 5 "geschlossen_mit_Ueberanpressung" 6 "sonstige_Fehler" 7 "fehlerhaft_geschlossen" ;
VAL_ 173 GE_MMom_Status 0 "keine Anforderung" 1 "reduzierender Getriebeeingriff" 2 "erhöhender Getriebeeingriff" 3 "Änderung mit Sprung" ;
VAL_ 173 GE_Freig_MMom_Vorhalt 0 "nicht_freigegeben" 1 "freigegeben" ;
VAL_ 173 GE_Verbot_Ausblendung 0 "kein_Verbot" 1 "Verbot" ;
VAL_ 173 GE_Zielgang 0 "Gang P/N (ausgekuppelt)" 1 "Gang 1" 2 "Gang 2" 3 "Gang 3" 4 "Gang 4" 5 "Gang 5" 6 "Gang 6" 7 "Gang 7" 8 "Gang R" 11 "Gang 8" 12 "Gang 9" 13 "Gang10" 14 "Istgang nicht definiert" 15 "Fehler" ;
VAL_ 968 GE_OBD_AbsperrVent 0 "kein Fehler / Init / nicht verbaut" 1 "KS- (Kurzschluss nach minus)" 2 "KS+ (Kurzschluss nach plus)" 3 "OC (Leitungsunterbrechung)" 4 "OOR+ (Signal zu gross)" 5 "OOR- (Signal zu klein)" 6 "RC+ (Signal unplausibel zu gross)" 7 "RC- (Signal unplausibel zu klein)" 8 "KS+/OC (Kurzschluss nach plus/Unterbrechung)" 9 "KS-/OC  (Kurzschluss nach minus/Unterbrechung)" 10 "KS-/KS+  (Kurzschluss nach minus/plus)" 11 "KS-/KS+/OC (Kurzschluss nach minus/plus/Unterbrechung)" 12 "Position_unbekannt" 13 "Failsafe_Position" 14 "Referenzfahrt_aktiv" 15 "frei" ;
VAL_ 968 GE_amax_moeglich 511 "nicht_definiert" ;
VAL_ 968 GE_Charisma_FahrPr 0 "keine_Funktion" 1 "Programm_1" 2 "Programm_2" 3 "Programm_3" 4 "Programm_4" 5 "Programm_5" 6 "Programm_6" 7 "Programm_7" 8 "Programm_8" 9 "Programm_9" 10 "Programm_10" 11 "Programm_11" 12 "Programm_12" 13 "Programm_13" 14 "Programm_14" 15 "Programm_15" ;
VAL_ 968 GE_Charisma_Status 0 "Init" 1 "verfuegbar" 2 "nicht_verfuegbar" 3 "asynchron_durch_Fahrerwunsch" ;
VAL_ 968 GE_Freigabe_Verfallsinfo_WFS 0 "Aus" 1 "Ein" ;
VAL_ 968 GE_LaunchControl_LB 0 "init" 1 "LC_not_available" 2 "LCperformance_not_possible" 3 "LCperformance_possible" 4 "LCperformance_armed" 5 "LCperformance_preparation" 6 "LCperformance_launch" 7 "LCperformance_aborted" 8 "LCsmoke_not_possible" 9 "LCsmoke_possible" 10 "LCsmoke_armed" 11 "LCsmoke_launch" 12 "LCsmoke_aborted" 13 "reserved" 14 "reserved" ;
VAL_ 968 GE_Status_PaddleNeutral 0 "Paddle_Neutral_inaktiv" 1 "Paddle_Neutral_aktiv" 2 "Paddle_Neutral_Ende_Timer_aktiv" 3 "Paddle_Neutral_Zwangsausstieg" ;
VAL_ 968 GE_Remotestart_Betrieb 0 "GSG_nicht_bereit_fuer_RS" 1 "GSG_bereit_fuer_oder_im_RS" ;
VAL_ 968 Freilauf_Charisma_FahrPr 0 "keine_Funktion" 1 "Programm_1" 2 "Programm_2" 3 "Programm_3" 4 "Programm_4" 5 "Programm_5" 6 "Programm_6" 7 "Programm_7" 8 "Programm_8" 9 "Programm_9" 10 "Programm_10" 11 "Programm_11" 12 "Programm_12" 13 "Programm_13" 14 "Programm_14" 15 "Programm_15" ;
VAL_ 968 Freilauf_Charisma_Status 0 "Init" 1 "verfuegbar" 2 "nicht_verfuegbar" 3 "asynchron_durch_Fahrerwunsch" ;
VAL_ 968 GE_Freigabe_Info_WFS 0 "ungueltig" 1 "gueltig" ;
VAL_ 968 GE_Sperr_Info_WFS 0 "nicht_gesperrt" 1 "gesperrt" ;
VAL_ 968 GE_Zustand_Kuppltemp 0 "Init" 1 "Kupplungstemp_normal" 2 "Kupplungstemp_hoch" 3 "Kupplungsschutz_aktivieren" ;
VAL_ 968 GE_Codierung_MSG 0 "Codierung iO / Init" 1 "Codierung niO" ;
VAL_ 968 GE_LaunchControl 0 "inaktiv" 1 "aktiv" ;
VAL_ 968 GE_Heizwunsch 0 "maximaler_Waermebedarf" 1 "kein_Waermebedarf" 2 "Kuehlbedarf" 3 "Notfall_(maximaler_Kuehlbedarf)" ;
VAL_ 968 GE_OBD_Status 0 "MIL aus" 1 "MIL ein" ;
VAL_ 968 GE_LFR_Adaption 0 "fuer_Adaption_geeignet" 1 "fuer_Adaption_nicht_geeignet" ;
VAL_ 968 GE_Sumpftemperatur 255 "Fehler" ;
VAL_ 177 GE_Fahrprogramm 0 "Init" 1 "nicht_belegt" 2 "Normal" 3 "Sport" 4 "Offroad" 5 "Efficiency" 6 "Sport_Plus" 7 "Sport_Response" 10 "Snow" 11 "Gravel" 12 "Mud_Ruts" 13 "Sand_Dune" ;
VAL_ 177 GE_TippZustand 0 "Init_Kein_Tipp" 1 "Tipp_permanent" 2 "Tipp_temporaer" ;
VAL_ 177 GE_Freilauf_Status 0 "Freilauf_inaktiv_aber_moeglich" 1 "Freilauf_aktiv" 2 "Freilauf_nicht_moegl_1Verhinderer" 3 "Freilauf_nicht_moegl_gr_1Verhinderer" 7 "Fehler" ;
VAL_ 177 GE_Grundeinstellung 0 "inaktiv" 1 "aktiv" ;
VAL_ 177 GE_Anschleppstart_Freigabe 0 "keine_Freigabe" 1 "Freigabe" ;
VAL_ 177 GE_Strombedarf_erh 0 "keine_Anforderung" 1 "erhoehte_Anforderung" ;
VAL_ 177 GE_Uefkt_Praed 16383 "Fehler" ;
VAL_ 177 GE_KomFehler_ESP 0 "kein_Fehler" 1 "Fehler" ;
VAL_ 177 GE_Rollrichtung_falsch 0 "richtige_Rollrichtung_o_Init" 1 "falsche_Rollrichtung" ;
VAL_ 177 GE_Getriebestatus_02 0 "inaktiv" 1 "Rennstartvorbereitung" 2 "Rennstart" 3 "Anfahrt" 4 "Anfahrt_Komfort" 5 "Anfahrt_Leerlaufregler" 6 "bereit_zur_Ueberanpressung" 7 "Low_Speed_Modus" 8 "eLaunch" ;
VAL_ 177 GE_Eingangsdrehz_Praed 16382 "Init" 16383 "Fehler" ;
VAL_ 879 GNSS_Breite_Ortung 134217726 "Init" 134217727 "Fehler" ;
VAL_ 879 GNSS_Richtung_Breite_Ortung 0 "Nord" 1 "Sued" ;
VAL_ 879 GNSS_Laenge_Ortung 268435454 "Init" 268435455 "Fehler" ;
VAL_ 879 GNSS_Richtung_Laenge_Ortung 0 "Ost" 1 "West" ;
VAL_ 879 GNSS_Ortung_FIX_Typ 0 "Init" 1 "No_Fix" 2 "2D_Fix" 3 "3D_Fix" ;
VAL_ 879 GNSS_Fehlerzustand 0 "Kein_Fehler" 1 "P_Mode" 2 "T_Mode" 3 "GNSS_Receiver_Problem" 4 "Kommunikationsproblem_im_SG" 5 "Start_GNSS_Receiver" 6 "GNSS_Receiver_aus" 7 "SG_spezifischer_Fehler" ;
VAL_ 884 GNSS_Ortung_Latenz 1022 "Init" 1023 "Fehler" ;
VAL_ 884 GNSS_Ortung_Ausrichtung 4094 "Init" 4095 "Fehler" ;
VAL_ 884 GNSS_Ortung_2D_Geschw_ue_Grund 510 "Init" 511 "Fehler" ;
VAL_ 884 GNSS_Ortung_Noerdliche_Geschw 1022 "Init" 1023 "Fehler" ;
VAL_ 884 GNSS_Ortung_Oestliche_Geschw 1022 "Init" 1023 "Fehler" ;
VAL_ 884 GNSS_Ortung_Vertikale_Geschw 1022 "Init" 1023 "Fehler" ;
VAL_ 886 GNSS_Ortung_GDOP 510 "Init" 511 "Fehler" ;
VAL_ 886 GNSS_Ortung_PDOP 510 "Init" 511 "Fehler" ;
VAL_ 886 GNSS_Ortung_HDOP 510 "Init" 511 "Fehler" ;
VAL_ 886 GNSS_Ortung_VDOP 510 "Init" 511 "Fehler" ;
VAL_ 886 GNSS_Ortung_Guete_Geschwindigk 62 "Init" 63 "Fehler" ;
VAL_ 886 GNSS_Ortung_Guete_Ausrichtung 62 "Init" 63 "Fehler" ;
VAL_ 886 GNSS_Ortung_Guete_horizontal 254 "Init" 255 "Fehler" ;
VAL_ 886 GNSS_Ortung_Guete_vertikal 62 "Init" 63 "Fehler" ;
VAL_ 888 GNSS_Ortung_Zeit_in_GPSWoche 1073741822 "Init" 1073741823 "Fehler" ;
VAL_ 888 GNSS_Ortung_Hoehe 4094 "Init" 4095 "Fehler" ;
VAL_ 891 GNSS_UTC_Zeit 0 "Init" ;
VAL_ 891 GNSS_Empfaenger_Status 0 "Backup_Mode" 1 "Live" ;
VAL_ 891 GNSS_GPS_in_Nutzung 0 "unbenutzt" 1 "benutzt" ;
VAL_ 891 GNSS_GLONASS_in_Nutzung 0 "unbenutzt" 1 "benutzt" ;
VAL_ 891 GNSS_Empfangbare_Satelliten 0 "Init" 31 "31_oder_mehr" ;
VAL_ 891 GNSS_Sichtbare_Satelliten 0 "Init" 31 "31_oder_mehr" ;
VAL_ 891 GNSS_Genutzte_Satelliten 0 "Init" 31 "31_oder_mehr" ;
VAL_ 1364 GNSS_Sat_Info_SNR_ID_1 31 "SNR_mehr_als_61_dB" ;
VAL_ 1364 GNSS_Sat_Info_Azimuth_ID_1 511 "Init" ;
VAL_ 1364 GNSS_Sat_Info_Hoehenwinkel_ID_1 127 "Init" ;
VAL_ 299 GRA_Hauptschalter 0 "Hauptschalter_aus__Taster_nicht_betaetigt" 1 "Hauptschalter_ein__Taster_betaetigt" ;
VAL_ 299 GRA_Abbrechen 0 "nicht_betaetigt" 1 "betaetigt" ;
VAL_ 299 GRA_Typ_Hauptschalter 0 "gerasteter_Lenkstockschalter" 1 "getasteter_Lenkstockschalter" ;
VAL_ 299 GRA_Limiter 0 "nicht_betaetigt" 1 "betaetigt" ;
VAL_ 299 GRA_Tip_Setzen 0 "nicht_betaetigt" 1 "betaetigt" ;
VAL_ 299 GRA_Tip_Hoch 0 "nicht_betaetigt" 1 "betaetigt" ;
VAL_ 299 GRA_Tip_Runter 0 "nicht_betaetigt" 1 "betaetigt" ;
VAL_ 299 GRA_Tip_Wiederaufnahme 0 "nicht_betaetigt" 1 "betaetigt" ;
VAL_ 299 GRA_Verstellung_Zeitluecke 0 "Taste_nicht_betaetigt" 1 "Dist_minus_1" 2 "Dist_plus_1" 3 "Dist_Toggle" ;
VAL_ 299 GRA_Codierung 0 "kein_Hebel" 1 "GRA_Hebel" 2 "ACC_Hebel" 3 "Limiter_Only" ;
VAL_ 299 GRA_Fehler 0 "kein_Fehler" 1 "Fehler" ;
VAL_ 299 GRA_LIM_Taste_verfuegbar 0 "Limiter_Taste_nicht_vorhanden" 1 "Limiter_Taste_vorhanden" ;
VAL_ 299 GRA_Tip_Stufe_2 0 "Tip_Stufe_1__keine_Betaetigung" 1 "Tip_Stufe_2" ;
VAL_ 299 GRA_Typ_Bedienteil 0 "Init" 1 "4_Positions_Bedienteil" 2 "6_Positions_Bedienteil" 3 "8_Positions_Bedienteil" 4 "PAG_5_Positions_Bedienteil" 5 "VW_MFL_Gen2" 6 "VW_MFL_Gen3" 7 "PAG_DX1_Bedienteil" ;
VAL_ 299 GRA_TravelAssist 0 "nicht_betaetigt" 1 "betaetigt" ;
VAL_ 310 HAL_Status 0 "Normalbetrieb" 1 "Lenkungsausfall" 2 "Derating_aktiv" 3 "Lenkung_manuell_deaktiviert" ;
VAL_ 310 HAL_VZ_Radwinkel 0 "positiv_Lenkeinschlag_links" 1 "negativ_Lenkeinschlag_rechts" ;
VAL_ 310 HAL_QBit_Radwinkel 0 "gueltiger_Wert" 1 "Ersatz_Init_oder_Fehlerwert" ;
VAL_ 310 HAL_Radwinkel 1020 "Unterspannung" 1021 "nicht_kalibriert" 1022 "Init" 1023 "Fehler" ;
VAL_ 310 HAL_Warnungen 0 "keine_Warnung" 1 "Ausfall_rote_Warnung" 2 "Systemstoerung_gelbe_Warnung" 3 "HAL_deaktiviert" ;
VAL_ 310 HAL_Winkelbegrenzung 0 "nicht_aktiv" 1 "Lenkwinkelbegrenzung_aktiv" ;
VAL_ 310 HAL_VZ_Fahrerwunschwinkel_Soll 0 "positiv" 1 "negativ" ;
VAL_ 310 HAL_Fahrerwunschwinkel_Soll 1022 "Init" 1023 "Fehler" ;
VAL_ 310 HAL_max_Gradient 126 "Init" 127 "Fehler" ;
VAL_ 310 HAL_EFP_FahrPr 0 "keine_Funktion" 1 "Programm_1" 2 "Programm_2" 3 "Programm_3" 4 "Programm_4" 5 "Programm_5" 6 "Programm_6" 7 "Programm_7" 8 "Programm_8" 9 "Programm_9" 10 "Programm_10" 11 "Programm_11" 12 "Programm_12" 13 "Programm_13" 14 "Programm_14" 15 "Programm_15" ;
VAL_ 310 HAL_Status_2 0 "Init" 1 "Fahrbereit" 2 "Symmetriefahrt" 3 "Gelbe_Warnung" 4 "Rote_Warnung" 5 "Hinterachlenkung_deaktiviert" ;
VAL_ 310 HAL_Charisma_Status 0 "Init" 1 "verfuegbar" 2 "nicht_verfuegbar" 3 "asynchron_durch_Fahrerwunsch" ;
VAL_ 310 HAL_Charisma_FahrPr 0 "keine_Funktion" 1 "Programm_1" 2 "Programm_2" 3 "Programm_3" 4 "Programm_4" 5 "Programm_5" 6 "Programm_6" 7 "Programm_7" 8 "Programm_8" 9 "Programm_9" 10 "Programm_10" 11 "Programm_11" 12 "Programm_12" 13 "Programm_13" 14 "Programm_14" 15 "Programm_15" ;
VAL_ 1410 HD_Endstellung_oben 1 "HD in Endstellung oben (offen)" ;
VAL_ 1410 HD_Endstellung_unten 0 "Init" 1 "HD in Endstellung unten (geschlossen)" ;
VAL_ 1410 HD_Bewegung_auf 0 "Init" 1 "HD in Bewegung auf" ;
VAL_ 1410 HD_Bewegung_zu 0 "Init" 1 "HD in Bewegung zu" ;
VAL_ 1410 HD_Innentaster_betaetigt 0 "HD_Innentaster_nicht_betaetigt" 1 "HD_Innentaster_betaetigt" ;
VAL_ 1410 HD_UeKB_erkannt 0 "Init" 1 "Einklemmschutz aktiv" ;
VAL_ 1410 HD_Taster_defekt 0 "Taster_funktionsfähig" 1 "Taster defekt" ;
VAL_ 1410 HD_Rueckmeld_prog 0 "keine Rueckmeldung" 1 "Rueckmeldung zur Programmierung Endstellung aktiv" ;
VAL_ 1410 HD_Verriegelungstaster_betaetigt 0 "Taster_nicht_betaetigt" 1 "Taster_betaetigt" ;
VAL_ 1410 HD_Verr_Taster_betaetigt_inv 0 "Taster_betaetigt" 1 "Taster_nicht_betaetigt" ;
VAL_ 1410 HD_ZZH_Schalter_S3 0 "nicht_betaetigt" 1 "betaetigt" ;
VAL_ 1416 FSH_LED 0 "Aus" 1 "Ein" ;
VAL_ 1416 HSH_LED 0 "Aus" 1 "Ein" ;
VAL_ 1416 SIH_Stufe_LED_li 0 "Aus" 2 "Stufe_2" 4 "Stufe_4" 6 "Stufe_6" ;
VAL_ 1416 SIH_Stufe_LED_re 0 "Aus" 2 "Stufe_2" 4 "Stufe_4" 6 "Stufe_6" ;
VAL_ 1416 SIL_Stufe_LED_li 0 "Aus" 1 "Stufe_1" 2 "Stufe_2" 3 "Stufe_3" 4 "Stufe_4" 5 "Stufe_5" 6 "Stufe_6" ;
VAL_ 1416 SIL_Stufe_LED_re 0 "Aus" 1 "Stufe_1" 2 "Stufe_2" 3 "Stufe_3" 4 "Stufe_4" 5 "Stufe_5" 6 "Stufe_6" ;
VAL_ 1416 KRH_Stufe_LED_li 0 "Aus" 1 "Stufe_1" 2 "Stufe_2" 3 "Stufe_3" ;
VAL_ 1416 KRH_Stufe_LED_re 0 "Aus" 1 "Stufe_1" 2 "Stufe_2" 3 "Stufe_3" ;
VAL_ 1416 BCM1_TCH_HLR_Anf 0 "keine_Anforderung" 1 "Anforderung" ;
VAL_ 1416 HLR_SIH_Freigabe_Fond 0 "keine_Freigabe" 1 "Freigabe" ;
VAL_ 1416 SIL_Stufe_LED_HL 0 "Aus" 1 "Stufe_1" 2 "Stufe_2" 3 "Stufe_3" 4 "Stufe_4" 5 "Stufe_5" 6 "Stufe_6" ;
VAL_ 1416 SIL_Stufe_LED_HR 0 "Aus" 1 "Stufe_1" 2 "Stufe_2" 3 "Stufe_3" 4 "Stufe_4" 5 "Stufe_5" 6 "Stufe_6" ;
VAL_ 1416 SIH_Stufe_LED_HL 0 "Aus" 1 "Stufe_1" 2 "Stufe_2" 3 "Stufe_3" 4 "Stufe_4" 5 "Stufe_5" 6 "Stufe_6" ;
VAL_ 1416 SIH_Stufe_LED_HR 0 "Aus" 1 "Stufe_1" 2 "Stufe_2" 3 "Stufe_3" 4 "Stufe_4" 5 "Stufe_5" 6 "Stufe_6" ;
VAL_ 1016 HLR_FlHz_Freigabe_Ruhesitz 0 "0_Prozent" 1 "33_Prozent" 2 "66_Prozent" 3 "100_Prozent" ;
VAL_ 1016 HLR_FlHz_Freigabe_VR 0 "0_Prozent" 1 "33_Prozent" 2 "66_Prozent" 3 "100_Prozent" ;
VAL_ 1016 HLR_FlHz_Freigabe_VL 0 "0_Prozent" 1 "33_Prozent" 2 "66_Prozent" 3 "100_Prozent" ;
VAL_ 1016 HLR_FlHz_Freigabe_HR 0 "0_Prozent" 1 "33_Prozent" 2 "66_Prozent" 3 "100_Prozent" ;
VAL_ 1016 HLR_FlHz_Freigabe_HL 0 "0_Prozent" 1 "33_Prozent" 2 "66_Prozent" 3 "100_Prozent" ;
VAL_ 1016 HLR_TCH_Freigabe 0 "keine_Freigabe" 1 "Freigabe" ;
VAL_ 1016 HLR_SIH_Freigabe_Fond 0 "keine_Freigabe" 1 "Freigabe" ;
VAL_ 1016 HLR_Sp_Heizung_Freigabe_BT 0 "keine_Freigabe" 1 "Freigabe" ;
VAL_ 1016 HLR_Sp_Heizung_Freigabe_FT 0 "keine_Freigabe" 1 "Freigabe" ;
VAL_ 1016 HLR_KRH_Freigabe_VL 0 "0_Prozent" 1 "33_Prozent" 2 "66_Prozent" 3 "100_Prozent" ;
VAL_ 1016 HLR_KRH_Freigabe_VR 0 "0_Prozent" 1 "33_Prozent" 2 "66_Prozent" 3 "100_Prozent" ;
VAL_ 1016 HLR_SIH_Freigabe_VL 0 "0_Prozent" 1 "33_Prozent" 2 "66_Prozent" 3 "100_Prozent" ;
VAL_ 1016 HLR_SIH_Freigabe_VR 0 "0_Prozent" 1 "33_Prozent" 2 "66_Prozent" 3 "100_Prozent" ;
VAL_ 1016 HLR_SIH_Freigabe_HL 0 "0_Prozent" 1 "33_Prozent" 2 "66_Prozent" 3 "100_Prozent" ;
VAL_ 1016 HLR_SIH_Freigabe_HR 0 "0_Prozent" 1 "33_Prozent" 2 "66_Prozent" 3 "100_Prozent" ;
VAL_ 1016 HLR_SIL_Freigabe_VL 0 "0_Prozent" 1 "33_Prozent" 2 "66_Prozent" 3 "100_Prozent" ;
VAL_ 1016 HLR_SIL_Freigabe_VR 0 "0_Prozent" 1 "33_Prozent" 2 "66_Prozent" 3 "100_Prozent" ;
VAL_ 1016 HLR_SIL_Freigabe_HL 0 "0_Prozent" 1 "33_Prozent" 2 "66_Prozent" 3 "100_Prozent" ;
VAL_ 1016 HLR_SIL_Freigabe_HR 0 "0_Prozent" 1 "33_Prozent" 2 "66_Prozent" 3 "100_Prozent" ;
VAL_ 1016 HLR_FSH_Freigabe 0 "AUS" 63 "Fehler" ;
VAL_ 1016 HLR_HSH_Freigabe 0 "keine_Freigabe" 1 "Freigabe" ;
VAL_ 1016 HLR_LRH_Freigabe 0 "keine_Freigabe" 1 "Freigabe" ;
VAL_ 1016 HLR_PTC_linear_Freigabe 63 "Fehler" ;
VAL_ 1016 HLR_PTC_Freigabe 0 "Aus" 1 "Stufe_1" 2 "Stufe_2" 3 "Stufe_3" ;
VAL_ 1412 HSP_Taster 0 "nicht_betaetigt" 1 "betaetigt" ;
VAL_ 1412 HSP_Status_LED 0 "LED_nicht_angesteuert" 1 "LED_angesteuert" ;
VAL_ 1412 HSP_Warnung_LED 0 "Aus" 1 "Ein" ;
VAL_ 1412 HSP_Warnung_Ton 0 "Aus" 1 "Ein" ;
VAL_ 1412 HSP_Warnung_Text 0 "Aus" 1 "Ein" ;
VAL_ 1412 HSP_Endlage_eingefahren 0 "Endlage nicht erreicht" 1 "Endlage erreicht" ;
VAL_ 1412 HSP_Endlage_ausgefahren 0 "Endlage nicht erreicht" 1 "Endlage erreicht" ;
VAL_ 1412 HSP_Unterspannung 0 "normal" 1 "Fehler" ;
VAL_ 1412 HSP_Ueberspannung 0 "normal" 1 "Fehler" ;
VAL_ 1412 HSP_Lokalaktiv 0 "war_nicht_lokal_aktiv" 1 "war_lokal_aktiv" ;
VAL_ 1412 HSP_ResponseError 0 "normal" 1 "Fehler" ;
VAL_ 1412 HSP_ErrorGueltigkeit_1 0 "Fehler_passiv__Fehlerpfad_nicht_durchlaufen" 1 "Fehler_gueltig__Fehlerpfad_durchlaufen" ;
VAL_ 1412 HSP_ErrorGueltigkeit_2 0 "Fehler_passiv__Fehlerpfad_nicht_durchlaufen" 1 "Fehler_gueltig__Fehlerpfad_durchlaufen" ;
VAL_ 1412 HSP_def 0 "normal" 1 "Fehler" ;
VAL_ 1412 HSP_Motor_def 0 "normal" 1 "Fehler" ;
VAL_ 1412 HSP_Spoiler_Error 0 "iO" 1 "Fehler__Endlage_nicht_erreicht" ;
VAL_ 1412 HSP_Taster_Error 0 "Taster_iO" 1 "Fehler__haengender_Taster" ;
VAL_ 1412 HSP_LED_Error 0 "normal" 1 "Fehler" ;
VAL_ 1412 HSP_Spielschutz 0 "inaktiv" 1 "aktiv" ;
VAL_ 1412 HSP_Motor_Temp_Text 0 "Aus" 1 "Ein" ;
VAL_ 1412 HSP_Charisma_FahrPr 0 "keine_Funktion" 1 "Programm_1" 2 "Programm_2" 3 "Programm_3" 4 "Programm_4" 5 "Programm_5" 6 "Programm_6" 7 "Programm_7" 8 "Programm_8" 9 "Programm_9" 10 "Programm_10" 11 "Programm_11" 12 "Programm_12" 13 "Programm_13" 14 "Programm_14" 15 "Programm_15" ;
VAL_ 1412 HSP_Charisma_Status 0 "Init" 1 "verfuegbar" 2 "nicht_verfuegbar" 3 "asynchron_durch_Fahrerwunsch" ;
VAL_ 1412 HSP_man_Betaet_nicht_zulaessig 0 "inaktiv" 1 "aktiv" ;
VAL_ 1412 HSP_Komponentensteuerung 0 "Aus" 1 "Ein" ;
VAL_ 1412 HSP_BAP_Messages 0 "No_message" 1 "Spoiler_extending" 2 "Spoiler_extending_hold_button" 3 "Spoiler_retracting" 4 "Spoiler_retracting_hold_button" 5 "Spoiler_extended" 6 "Spoiler_retracted" 7 "Extending_spoiler_not_possible" 8 "Retracting_spoiler_not_possible" 9 "Spoiler_not_available" 10 "Thermal_protection" 11 "Protection_against_misuse" 12 "Spoiler_intermediate_position" ;
VAL_ 1283 HVK_Istmodus_Anf 0 "nicht_angefordert" 1 "angefordert" ;
VAL_ 1283 HVK_TN1_Sollmodus 0 "HV_Off" 1 "HV_On" 2 "reserviert" 3 "Initialisierung" ;
VAL_ 1283 HVK_MO_EmSollzustand 0 "HvOff" 1 "HvStbyReq" 2 "HvStbyWait" 3 "HvBattOnReq" 4 "HvBattOnWait" 10 "HvOnIdle" 18 "HvOnDrvReq" 19 "HvOnDrvWait" 20 "HvOnDrvRdy" 28 "HvStepUpReq" 29 "HvStepUpWait" 30 "HvStepUp" 38 "HvStepDownReq" 39 "HvStepDownWait" 40 "HvStepDown" 46 "HvAcChPreReq" 47 "HvAcChPreWait" 48 "HvAcChReq" 49 "HvAcChWait" 50 "HvAcCh" 56 "HvDcChPreReq" 57 "HvDcChPreWait" 58 "HvDcChReq" 59 "HvDcChWait" 60 "HvDcCh" 67 "HvChOffReq" 68 "HvChOffWait" 69 "HvOnIdleReq" 70 "HvOnIdleWait" 96 "HvCpntOffReq" 97 "HvCpntOffWait" 98 "HvBattOffReq" 99 "HvBattOffWait" 109 "HvDcDcFailOffReq" 110 "HvDcDcFail" 119 "HvElmOffReq" 120 "HvElmOff" 126 "HvFailCpntOffReq" 127 "HvFailCpntOffWait" 128 "HvFailBattOffReq" 129 "HvFailBattOffWait" 130 "HvFailBattOff" 138 "HvFailUCtlReq" 139 "HvFailUCtlWait" 140 "HvFailUCtl" 150 "HvEmgcyOff" 255 "Init" ;
VAL_ 1283 HVK_BMS_Sollmodus 0 "HV_Off" 1 "HV_On" 3 "AC_Laden_erw" 4 "AC_Laden" 6 "DC_Laden" 7 "Init" ;
VAL_ 1283 HVK_DCDC_Sollmodus 0 "Standby" 1 "HV_On_Vorladen" 2 "Tiefsetzen" 3 "Hochsetzen" 4 "Pruefpuls_12V" 7 "Initialisierung" ;
VAL_ 1283 HVK_EKK_Sollmodus 0 "Keine_Freigabe" 1 "Freigabe" 2 "Freigabe_ausgesetzt" 7 "Init" ;
VAL_ 1283 HVK_HVPTC_Sollmodus 0 "Keine_Freigabe" 1 "Freigabe" 2 "Freigabe_ausgesetzt" 7 "Init" ;
VAL_ 1283 HVK_HVLM_Sollmodus 0 "keine_Freigabe" 1 "Freigabe_Lademanager" 2 "Vorladung_AC_Pfad" 7 "Init" ;
VAL_ 1283 HVK_HV_Netz_Warnungen 0 "Keine_Warnung" 1 "Warntext_HV_Netz_Anf" 2 "Fehlertext_HV_Netz_Anf" 3 "Warnung_Kein_Wiederstart_moeglich" ;
VAL_ 1283 HV_Bordnetz_aktiv 0 "inaktiv" 1 "aktiv" ;
VAL_ 1283 HV_Bordnetz_Fehler 0 "kein_Fehler" 1 "Fehler" ;
VAL_ 1283 HVK_Gesamtst_Spgfreiheit 0 "Funktion_Init__ohne_Funktion" 1 "HV_System_spannungsfrei" 2 "HV_System_nicht_spannungsfrei" 3 "Fehler" ;
VAL_ 1283 HVK_AktiveEntladung_Anf 0 "nicht_angefordert" 1 "angefordert" ;
VAL_ 1283 HVK_Iso_Messung_Start 0 "keine_Messung" 1 "Messung_HV_Netz_1" 2 "Messung_HV_Netz_2" 4 "deaktiviert" ;
VAL_ 1283 HVK_AIAD_Sollmodus_2 0 "keine_Freigabe" 1 "Freigabe" ;
VAL_ 1283 HVK_DCDC_EKK_Sollmodus 0 "aus" 1 "ein" 2 "reserviert" 3 "Init" ;
VAL_ 1340 HVLM_STH_Betriebsmodus 0 "Keine_Klimatisierung" 1 "Heizen" 2 "Abtauen" 6 "Init" 7 "Fehler" ;
VAL_ 1340 HVLM_Standklima_Timer_Status 0 "Standklimatimer_nicht_aktiv" 1 "Standklimatimer_aktiv" ;
VAL_ 1340 HVLM_HVEM_MaxLeistung 510 "Init" 511 "Fehler" ;
VAL_ 1340 HVLM_Status_Netz 0 "Fzg_nicht_am_Netz" 1 "Fzg_ist_am_Stromnetz" ;
VAL_ 1340 HVLM_Anf_Ladescreen 0 "Ladescreen_off" 1 "Ladescreen_on" ;
VAL_ 1340 HVLM_Ladeart 0 "keine_Auswahl" 1 "AC_Laden" 2 "DC_Laden" 3 "Konditionierung" ;
VAL_ 1340 HVLM_VK_STH_Einsatz 0 "Verbrennerstandheizung verbieten" 1 "Automatik (Verbrennerstandheizung erlauben)" 2 "Verbrennerstandheizung erzwingen" 3 "reserviert" 4 "reserviert" 5 "reserviert" 6 "Init" 7 "Fehler" ;
VAL_ 1340 HVLM_VK_Modus 0 "keine Vorkonditionierung" 1 "Sofort-Konditionierung" 2 "zeitversetzte Konditionierung" 3 "Fehler" ;
VAL_ 1340 HVLM_IstModus_02 0 "inaktiv" 1 "aktiv" 2 "Init" 3 "Fehler" ;
VAL_ 1340 HVLM_HV_Anf 0 "keine_Anforderung" 1 "Laden_angefordert" 2 "Batteriekonditionierung_angefordert" 3 "Standklimatisierung_angefordert" ;
VAL_ 1340 HVLM_Fehlerstatus 0 "Komponente_IO" 1 "Eingeschr_KompFkt_DC_Lad_NIO" 2 "Eingeschr_KompFkt_AC_Lad_NIO" 3 "Eingeschr_KompFkt_Interlock" 4 "Eingeschr_KompFkt_reserve" 5 "Eingeschr_KompFkt_reserve" 6 "Keine_Komponentenfunktion" 7 "Init" ;
VAL_ 1340 HVLM_Anforderung_HMS 0 "keine_Anforderung" 1 "halten" 2 "parken" 3 "halten_Standby" 4 "anfahren" 5 "Loesen_ueber_Rampe" ;
VAL_ 1340 HVLM_Parken_beibehalten_HMS 0 "Parken_nicht_beibehalten" 1 "Parken_beibehalten" 2 "Init" 3 "Fehler" ;
VAL_ 1340 HVLM_Status_Tankklappe 0 "geschlossen" 1 "offen" 2 "Init" 3 "Fehler" ;
VAL_ 1340 HVLM_AWC_Sollmodus 0 "init" 1 "Inaktiv" 2 "Standby" 3 "AWCLaden" 4 "Notabschaltung" 5 "Reserve" 6 "Reserve" 7 "Fehler" ;
VAL_ 1340 HVLM_Stecker_Status 0 "Init" 1 "kein_Stecker_gesteckt" 2 "Stecker_erkannt_nicht_verriegelt" 3 "Stecker_erkannt_und_verriegelt" ;
VAL_ 1340 HVLM_LadeAnforderung 0 "keine_Anforderung" 1 "AC_Laden" 2 "DC_Laden" 3 "Nachladen_12V" 4 "AC_Laden_AWC" 5 "Reserve" 6 "Init" 7 "Fehler" ;
VAL_ 1340 HVLM_MaxBatLadestromHV 254 "Init" 255 "Fehler" ;
VAL_ 1524 IL_Bel_FS_Ausstieg 0 "inaktiv" 1 "aktiv" ;
VAL_ 1524 IL_Bel_BFS_Ausstieg 0 "inaktiv" 1 "aktiv" ;
VAL_ 1524 IL_Bel_HFS_Ausstieg 0 "inaktiv" 1 "aktiv" ;
VAL_ 1524 IL_Bel_HBFS_Ausstieg 0 "inaktiv" 1 "aktiv" ;
VAL_ 1524 BCM1_Innenlicht_gedimmt_V 0 "100% Innenlicht" 1 "gedimmtes Innenlicht" ;
VAL_ 1524 BCM1_Innenlicht_gedimmt_H 0 "100% Innenlicht" 1 "gedimmtes Innenlicht" ;
VAL_ 1524 IL_Innenlicht_aktiv 0 "Innenlicht inaktiv" 1 "Innenlicht aktiv" ;
VAL_ 1524 IL_Klemme_30G_aktiv 0 "Kl_30G_abgeschaltet" 1 "eingeschaltet" ;
VAL_ 1524 BCM1_DI_Rampe_Innenlicht 0 "Dimmrampe 0" 1 "Dimmrampe 1" ;
VAL_ 1524 BCM1_DI_Rampe_Leselicht 0 "Dimmrampe 0" 1 "Dimmrampe 1" ;
VAL_ 1524 BCM1_Innenlicht_H 0 "Aus" 1 "Ein" ;
VAL_ 1524 BCM1_Innenlicht_V 0 "Aus" 1 "Ein" ;
VAL_ 1524 BCM1_Leselicht_Anf_hl 0 "Aus" 1 "Ein" ;
VAL_ 1524 BCM1_Leselicht_Anf_hr 0 "Aus" 1 "Ein" ;
VAL_ 1524 BCM1_Leselicht_Anf_vl 0 "Aus" 1 "Ein" ;
VAL_ 1524 BCM1_Leselicht_Anf_vr 0 "Aus" 1 "Ein" ;
VAL_ 1524 BCM1_Leuchten_Aus 0 "keine Aenderung" 1 "Aus" ;
VAL_ 1524 AMB_Charisma_FahrPr 0 "keine_Funktion" 1 "Programm_1" 2 "Programm_2" 3 "Programm_3" 4 "Programm_4" 5 "Programm_5" 6 "Programm_6" 7 "Programm_7" 8 "Programm_8" 9 "Programm_9" 10 "Programm_10" 11 "Programm_11" 12 "Programm_12" 13 "Programm_13" 14 "Programm_14" 15 "Programm_15" ;
VAL_ 1524 AMB_Charisma_Status 0 "Init" 1 "verfuegbar" 2 "nicht_verfuegbar" 3 "asynchron_durch_Fahrerwunsch" ;
VAL_ 312 IPA_Anforderung_HMS 0 "keine_Anforderung" 1 "halten" 2 "parken" 3 "halten_Standby" 4 "anfahren" 5 "Loesen_ueber_Rampe" 6 "Parken_mit_P" ;
VAL_ 312 Parken_aktives_System 0 "kein_aktives_System" 1 "Manoevrierassistent_Ueberwachung" 2 "IPA" 3 "fernbedientes_Parken" 4 "Manoevrierassistent" 5 "Manoevrierassistent_quer" 6 "Anhaengerrangierassistent" 7 "fernbedienter_Anhaengerrangierassistent" ;
VAL_ 312 Parken_erhoehtes_Moment 0 "keine_Anforderung" 1 "Anforderung_Rampe1" 2 "Anforderung_Rampe2" 3 "Anforderung_Rampe3" 4 "Anforderung_Rampe4" 5 "Anforderung_Rampe5" 6 "Anforderung_Rampe6" 7 "Anforderung_Rampe7" 8 "Anforderung_Rampe8" 9 "Anforderung_Rampe9" 10 "Anforderung_Rampe10" 11 "Anforderung_Rampe11" 12 "Anforderung_Rampe12" 13 "Anforderung_Rampe13" 14 "Anforderung_Rampe14" 15 "Anforderung_Rampe15" ;
VAL_ 312 Parken_Motorlauf_Anf 0 "Keine_Anforderung" 1 "Motor_aus" 2 "Motor_an" 3 "Weiterlauf_Fahreruebernahme" ;
VAL_ 312 IPA_Fahrstufenwunsch 0 "Init" 1 "Fahrstufe_beibehalten" 2 "Position_R" 3 "Position_D" 4 "Position_N" ;
VAL_ 312 IPA_Status 0 "Init" 4 "IPA_Anzeige_Aktiv" 5 "IPA_Fahreruebernahme" 6 "IPA_Aktiv" 7 "IPA_Standby" 8 "IPA_Funktionsbereit" 9 "IPA_PP_Aktivierung" 10 "IPA_Abbruch" 11 "IPA_Aktivierend" 15 "IPA_PP_Start" ;
VAL_ 312 IPA_Status_IPA_GE 0 "Init" 1 "Neustart" 2 "Funktionsbereit" 3 "Aktiv" 7 "Fehler" ;
VAL_ 312 IPA_Status_IPA_TSK 1 "IPA_TSK_Init" 2 "IPA_TSK_Fehler" 4 "IPA_TSK_aktivierbar" 5 "IPA_TSK_pausiert" 6 "IPA_TSK_aktiv" 8 "IPA_TSK_funktionsbereit" ;
VAL_ 312 IPA_Sollbeschleunigung 0 "Neutralwert" ;
VAL_ 312 Parken_Fahrbereitschaft_Anf 0 "keine_Anforderung" 1 "Anforderung_Fahrbereitschaft" ;
VAL_ 312 IPA_Parken_beibehalten_HMS 0 "Parken_nicht_beibehalten" 1 "Parken_beibehalten" 2 "Init" 3 "Fehler" ;
VAL_ 312 IPA_PLA_LED 0 "LED_aus" 1 "LED_ein" 2 "LED_blinken" 3 "Funktion_gesperrt__LED_aus" 6 "Init" ;
VAL_ 312 IPA_APS_LED 0 "LED_aus" 1 "LED_ein" 2 "LED_blinken" 3 "Funktion_gesperrt__LED_aus" 6 "Init" ;
VAL_ 2527679583 Parken_Seitenspiegel_Anf 0 "Keine_Anforderung" 1 "Seitenspiegel_anklappen" 2 "Seitenspiegel_abklappen" ;
VAL_ 2527679583 Parken_ZV_Schliessen 0 "Keine_Anforderung" 1 "ZV_verriegeln" 2 "ZV_safen" ;
VAL_ 2527679583 Parken_ZR_Sondermodus_Anf 0 "Init" 1 "Keine_Anforderung" 2 "Anforderung_Sondermodus" ;
VAL_ 2527679583 Parken_Schluesselsuche_Anf 0 "keine_Anforderung" 1 "Anforderung_Schluesselsuche" ;
VAL_ 2527679583 Parken_FFB_LED_Anf 0 "keine_Anforderung" 1 "Abbruch_Fehler" 2 "Bereit_OK" 3 "Beendet" ;
VAL_ 2527679583 Parken_Wegfahrsperren_Anf 0 "keine_Anforderung" 1 "Anforderung_Fahreruebernahme" 2 "Anforderung_Fahreruebergabe" ;
VAL_ 2527679583 Parken_Aktivierungslicht_Anf 0 "keine_Anforderung" 1 "Aktivierungslicht" ;
VAL_ 2527679583 Parken_Fahrtrichtungslicht_Anf 0 "keine_Anforderung" 1 "Vorwaerts" 2 "Rueckwaerts" ;
VAL_ 2527679583 Parken_Lichtnachlauf_Anf 0 "keine_Anforderung" 1 "Anforderung_Lichtnachlauf" ;
VAL_ 2527679583 Parken_Fahrerhinweise_Anf 0 "keine_Anforderung" 1 "Fahrerhinweise_anzeigen" ;
VAL_ 2527679583 Parken_Bestaetigungsblinken_Anf 0 "keine_Anforderung" 1 "Erfolgsblinken_Einparken" 2 "Abbruchsblinken" 3 "Erfolgsblinken_Ausparken" ;
VAL_ 2527679583 Parken_Fahrbereitschaftlicht_Anf 0 "keine_Anforderung" 1 "Fahrbereitschaftslicht" ;
